VERSION ""

NS_ :

BS_:

BU_: TIMClient3 TIMClient2 TIMClient1 TIMServer
VAL_TABLE_ TIM_AuthErrorCode 39 "LwAPossibleBitMismatch" 38 "AuthenticationAbortedDueToGeneralPeerError" 37 "AuthenticationAbortedByPeerDueToError" 36 "ChallengeDataCorrupt" 35 "InvalidChallengeLength" 34 "FunctionFacilityNotCertified" 33 "RequestNotAllowed" 32 "Reserved_0x20" 31 "AuthenticationTimeout" 30 "CertificateTypeInvalid" 29 "DeviceCertificateRevoked" 28 "ManufacturerSeriesCertificateRevoked" 27 "ManufacturerCertificateRevoked" 26 "LabCertificateRevoked" 25 "RootCertificateRevoked" 24 "CertificateTypeMismatch" 23 "CertificateChainInvalid" 22 "ECU_CCID_Mismatch" 21 "NAME_Mismatch" 20 "ECC_PublicKeyValidationFailed" 19 "UnexpectedRestartAuthenticationBitSet" 18 "AuthenticationStatusInvalid" 17 "AuthenticationTypeNotSupported" 16 "AuthenticationStatusLost" 15 "DeviceCertificateDataCorrupt" 14 "ManufacturerSeriesCertificateDataCorrupt" 13 "ManufacturerCertificateDataCorrupt" 12 "TestLabCertificateDataCorrupt" 11 "RootCertificateDataCorrupt" 10 "InternalError" 9 "ChallengesDontMatch" 8 "DeviceCertificateSignatureInvalid" 7 "ManufacturerSeriesCertificateSignatureInvalid" 6 "ManufacturerCertificateSignatureInvalid" 5 "LabCertificateSignatureInvalid" 4 "RootCertificateSignatureInvalid" 3 "NotAuthenticationServerOrClient" 2 "CertificateFormatNotSupported" 1 "ParticipantBusy" 0 "NoError" ;
VAL_TABLE_ TIM_CertificateType 255 "NotAvailable" 6 "CRLCertificate" 5 "CRLSigningCertificate" 4 "DeviceCertificate" 3 "ManufacturereSeriesCertificate" 2 "ManufacturerCertificate" 1 "TestlabCertificate" 0 "AEFRootCertificate" ;
VAL_TABLE_ NetworkInterconnUnitParametrics 16 "NetworkInterconnectionUnitType" 15 "NumberOfPorts" 14 "UptimeSinceLastPowerOnReset " 13 "AverageNumOfMsgsFilteredPerSec" 12 "AverageNumOfMsgsForwardedPerSec" 11 "AverageNumOfMsgsReceivedPerSec" 10 "NumOfMsgsWithExcessTransitDelayTime " 9 "NumOfMsgsLostDueToBufferOverflow " 8 "AverageTransitDelayTime" 7 "MaxTransitDelayTime" 6 "MaxNumOfMsgsFilteredPerSec" 5 "MaxNumOfMsgsForwardedPerSec" 4 "MaxNumOfMsgsReceivedPerSec" 3 "NumberOfFilterDatabaseEntries" 2 "MaxFilterDatabaseSize" 1 "BufferSize" 0 "RequestAllParameters" ;
VAL_TABLE_ FMI 0 "Above normal (most severe)" 1 "Below normal (most severe)" 2 "Data erratic" 3 "Voltage above normal" 4 "Voltage below normal" 5 "Current below normal" 6 "Current above normal" 7 "Mechanical system not responding" 8 "Abnormal frequency" 9 "Abnormal update rate" 10 "Abnormal rate of change" 11 "Root cause not known" 12 "Bad intelligent device" 13 "Out of calibration" 14 "Special intstructions" 15 "Above normal (least severe)" 16 "Above normal (moderately severe)" 17 "Below normal (least severe)" 18 "Below normal (moderately severe)" 19 "Received network data in error" 31 "Not available" 20 "Data Drifted High" 21 "Data Drifted Low" ;

BO_ 2619670017 TIM21_TIMClient: 16 TIMClient1
 SG_ CurvatureRequest m70 : 32|16@1+ (0.25,-8032) [-8032|8031.75] "1/km" Vector__XXX
 SG_ VehicleSpeedRequest m68 : 32|16@1+ (0.001,-32.128) [-32.127|32.127] "m/s" Vector__XXX
 SG_ HitchPosReq m66 : 32|16@1+ (0.01,0) [0|100] "%" Vector__XXX
 SG_ PTOSpeedRequest m64 : 32|16@1+ (0.125,-4016) [0|0] "1/min" Vector__XXX
 SG_ RequestCounter m0 : 8|4@1+ (1,0) [0|0] "" Vector__XXX
 SG_ AuxValveFlowReq m0 : 32|16@1+ (0.004,-128.512) [0|0] "%" Vector__XXX
 SG_ TIMClientState m249 : 20|4@1+ (1,0) [0|0] "" Vector__XXX
 SG_ ClientHearbeatCounter m249 : 8|8@1+ (1,0) [0|0] "" Vector__XXX
 SG_ TIMFunctionId_4 m245 : 64|8@1+ (1,0) [0|0] "" Vector__XXX
 SG_ TIMFunctionId_3 m245 : 48|8@1+ (1,0) [0|0] "" Vector__XXX
 SG_ TIMFunctionId_2 m245 : 32|8@1+ (1,0) [0|0] "" Vector__XXX
 SG_ TIMFunctionId_1 m245 : 16|8@1+ (1,0) [0|0] "" Vector__XXX
 SG_ NumOfTIMFunctions m245 : 8|8@1+ (1,0) [1|250] "" Vector__XXX
 SG_ RequestType_4 m245 : 77|3@1+ (1,0) [0|0] "" Vector__XXX
 SG_ RequestType_3 m245 : 61|3@1+ (1,0) [0|0] "" Vector__XXX
 SG_ RequestType_2 m245 : 45|3@1+ (1,0) [0|0] "" Vector__XXX
 SG_ RequestType_1 m245 : 29|3@1+ (1,0) [0|0] "" Vector__XXX
 SG_ MinimumTIMVersionNr m246 : 24|8@1+ (1,0) [0|0] "" Vector__XXX
 SG_ ImplementedTIMVersionNr m246 : 16|8@1+ (1,0) [0|0] "" Vector__XXX
 SG_ TIMMessageType m0 : 12|4@1+ (1,0) [0|0] "" Vector__XXX
 SG_ GroupFunctionValue M : 0|8@1+ (1,0) [0|0] "" Vector__XXX

BO_ 2619670018 TIM21_TIMClient2: 16 TIMClient2
 SG_ CurvatureRequest m70 : 32|16@1+ (0.25,-8032) [-8032|8031.75] "1/km" Vector__XXX
 SG_ VehicleSpeedRequest m68 : 32|16@1+ (0.001,-32.128) [-32.127|32.127] "m/s" Vector__XXX
 SG_ HitchPosReq m66 : 32|16@1+ (0.01,0) [0|100] "%" Vector__XXX
 SG_ PTOSpeedRequest m64 : 32|16@1+ (0.125,-4016) [0|0] "1/min" Vector__XXX
 SG_ RequestCounter m0 : 8|4@1+ (1,0) [0|0] "" Vector__XXX
 SG_ AuxValveFlowReq m0 : 32|16@1+ (0.004,-128.512) [0|0] "%" Vector__XXX
 SG_ TIMClientState m249 : 20|4@1+ (1,0) [0|0] "" Vector__XXX
 SG_ ClientHearbeatCounter m249 : 8|8@1+ (1,0) [0|0] "" Vector__XXX
 SG_ TIMFunctionId_4 m245 : 64|8@1+ (1,0) [0|0] "" Vector__XXX
 SG_ TIMFunctionId_3 m245 : 48|8@1+ (1,0) [0|0] "" Vector__XXX
 SG_ TIMFunctionId_2 m245 : 32|8@1+ (1,0) [0|0] "" Vector__XXX
 SG_ TIMFunctionId_1 m245 : 16|8@1+ (1,0) [0|0] "" Vector__XXX
 SG_ NumOfTIMFunctions m245 : 8|8@1+ (1,0) [1|250] "" Vector__XXX
 SG_ RequestType_4 m245 : 77|3@1+ (1,0) [0|0] "" Vector__XXX
 SG_ RequestType_3 m245 : 61|3@1+ (1,0) [0|0] "" Vector__XXX
 SG_ RequestType_2 m245 : 45|3@1+ (1,0) [0|0] "" Vector__XXX
 SG_ RequestType_1 m245 : 29|3@1+ (1,0) [0|0] "" Vector__XXX
 SG_ MinimumTIMVersionNr m246 : 24|8@1+ (1,0) [0|0] "" Vector__XXX
 SG_ ImplementedTIMVersionNr m246 : 16|8@1+ (1,0) [0|0] "" Vector__XXX
 SG_ TIMMessageType m0 : 12|4@1+ (1,0) [0|0] "" Vector__XXX
 SG_ GroupFunctionValue M : 0|8@1+ (1,0) [0|0] "" Vector__XXX

BO_ 2619670019 TIM21_TIMClient3: 16 TIMClient3
 SG_ CurvatureRequest m70 : 32|16@1+ (0.25,-8032) [-8032|8031.75] "1/km" Vector__XXX
 SG_ VehicleSpeedRequest m68 : 32|16@1+ (0.001,-32.128) [-32.127|32.127] "m/s" Vector__XXX
 SG_ HitchPosReq m66 : 32|16@1+ (0.01,0) [0|100] "%" Vector__XXX
 SG_ PTOSpeedRequest m64 : 32|16@1+ (0.125,-4016) [0|0] "1/min" Vector__XXX
 SG_ RequestCounter m0 : 8|4@1+ (1,0) [0|0] "" Vector__XXX
 SG_ AuxValveFlowReq m0 : 32|16@1+ (0.004,-128.512) [0|0] "%" Vector__XXX
 SG_ TIMClientState m249 : 20|4@1+ (1,0) [0|0] "" Vector__XXX
 SG_ ClientHearbeatCounter m249 : 8|8@1+ (1,0) [0|0] "" Vector__XXX
 SG_ TIMFunctionId_4 m245 : 64|8@1+ (1,0) [0|0] "" Vector__XXX
 SG_ TIMFunctionId_3 m245 : 48|8@1+ (1,0) [0|0] "" Vector__XXX
 SG_ TIMFunctionId_2 m245 : 32|8@1+ (1,0) [0|0] "" Vector__XXX
 SG_ TIMFunctionId_1 m245 : 16|8@1+ (1,0) [0|0] "" Vector__XXX
 SG_ NumOfTIMFunctions m245 : 8|8@1+ (1,0) [1|250] "" Vector__XXX
 SG_ RequestType_4 m245 : 77|3@1+ (1,0) [0|0] "" Vector__XXX
 SG_ RequestType_3 m245 : 61|3@1+ (1,0) [0|0] "" Vector__XXX
 SG_ RequestType_2 m245 : 45|3@1+ (1,0) [0|0] "" Vector__XXX
 SG_ RequestType_1 m245 : 29|3@1+ (1,0) [0|0] "" Vector__XXX
 SG_ MinimumTIMVersionNr m246 : 24|8@1+ (1,0) [0|0] "" Vector__XXX
 SG_ ImplementedTIMVersionNr m246 : 16|8@1+ (1,0) [0|0] "" Vector__XXX
 SG_ TIMMessageType m0 : 12|4@1+ (1,0) [0|0] "" Vector__XXX
 SG_ GroupFunctionValue M : 0|8@1+ (1,0) [0|0] "" Vector__XXX

BO_ 2619604717 TIM12_TIMServer: 16 TIMServer
 SG_ Curvature m70 : 32|16@1+ (0.25,-8032) [-8032|8031.75] "1/km" Vector__XXX
 SG_ GuidanceExitReasonCode m70 : 27|5@1+ (1,0) [0|0] "" Vector__XXX
 SG_ VehicleSpeed m68 : 32|16@1+ (0.001,-32.128) [-32.127|32.127] "m/s" Vector__XXX
 SG_ SpeedExitReasonCode m68 : 27|5@1+ (1,0) [0|0] "" Vector__XXX
 SG_ HitchPosition m66 : 32|16@1+ (0.01,0) [0|100] "%" Vector__XXX
 SG_ HitchExitReasonCode m66 : 27|5@1+ (1,0) [0|0] "" Vector__XXX
 SG_ PTOSpeed m64 : 32|16@1+ (0.125,-4016) [0|0] "1/min" Vector__XXX
 SG_ PTOExitReasonCode m64 : 27|5@1+ (1,0) [0|0] "" Vector__XXX
 SG_ TIMAuxValveFlow m0 : 32|16@1+ (0.004,-128.512) [0|0] "%" Vector__XXX
 SG_ FlowType m0 : 24|2@1+ (1,0) [0|0] "" Vector__XXX
 SG_ ReflectedRequestCounter m0 : 8|4@1+ (1,0) [0|0] "" Vector__XXX
 SG_ AuxValveExitReasonCode m0 : 27|5@1+ (1,0) [0|0] "" Vector__XXX
 SG_ AutomationStatus m0 : 16|4@1+ (1,0) [0|0] "" Vector__XXX
 SG_ TIMSystemOperationState m250 : 24|4@1+ (1,0) [0|15] "" Vector__XXX
 SG_ TIMServerState m250 : 28|4@1+ (1,0) [0|0] "" Vector__XXX
 SG_ TIMSystemState m250 : 16|4@1+ (1,0) [0|0] "" Vector__XXX
 SG_ TIMServerMasterIndication m250 : 20|4@1+ (1,0) [0|0] "" Vector__XXX
 SG_ ServerHeartbeatCounter m250 : 8|8@1+ (1,0) [0|0] "" Vector__XXX
 SG_ AssignmentResult_4 m245 : 77|3@1+ (1,0) [0|0] "" Vector__XXX
 SG_ AssignmentResult_3 m245 : 61|3@1+ (1,0) [0|0] "" Vector__XXX
 SG_ AssignmentResult_2 m245 : 45|3@1+ (1,0) [0|0] "" Vector__XXX
 SG_ AssignmentErrorReason_4 m245 : 72|5@1+ (1,0) [0|0] "" Vector__XXX
 SG_ AssignmentErrorReason_3 m245 : 56|5@1+ (1,0) [0|0] "" Vector__XXX
 SG_ AssignmentErrorReason_2 m245 : 40|5@1+ (1,0) [0|0] "" Vector__XXX
 SG_ AssignmentErrorReason_1 m245 : 24|5@1+ (1,0) [0|0] "" Vector__XXX
 SG_ AssignmentResult_1 m245 : 29|3@1+ (1,0) [0|0] "" Vector__XXX
 SG_ TIMFunctionId_4 m245 : 64|8@1+ (1,0) [0|0] "" Vector__XXX
 SG_ TIMFunctionId_3 m245 : 48|8@1+ (1,0) [0|0] "" Vector__XXX
 SG_ TIMFunctionId_2 m245 : 32|8@1+ (1,0) [0|0] "" Vector__XXX
 SG_ TIMFunctionId_1 m245 : 16|8@1+ (1,0) [0|0] "" Vector__XXX
 SG_ NumOfTIMFunctions m245 : 8|8@1+ (1,0) [1|250] "" Vector__XXX
 SG_ NumOfSuportedTIMFunctions m244 : 8|8@1+ (1,0) [1|250] "" Vector__XXX
 SG_ TIMConnectionVersion m246 : 16|8@1+ (1,0) [0|0] "" Vector__XXX
 SG_ ErrorCode m246 : 8|8@1+ (1,0) [0|0] "" Vector__XXX
 SG_ MinimumTIMVersionNr m248 : 24|8@1+ (1,0) [0|0] "" Vector__XXX
 SG_ ImplementedTIMVersionNr m248 : 16|8@1+ (1,0) [0|0] "" Vector__XXX
 SG_ BootTime m248 : 8|8@1+ (1,0) [0|0] "" Vector__XXX
 SG_ TIMMessageType m0 : 12|4@1+ (1,0) [0|0] "" Vector__XXX
 SG_ GroupFunctionValue M : 0|8@1+ (1,0) [0|0] "" Vector__XXX

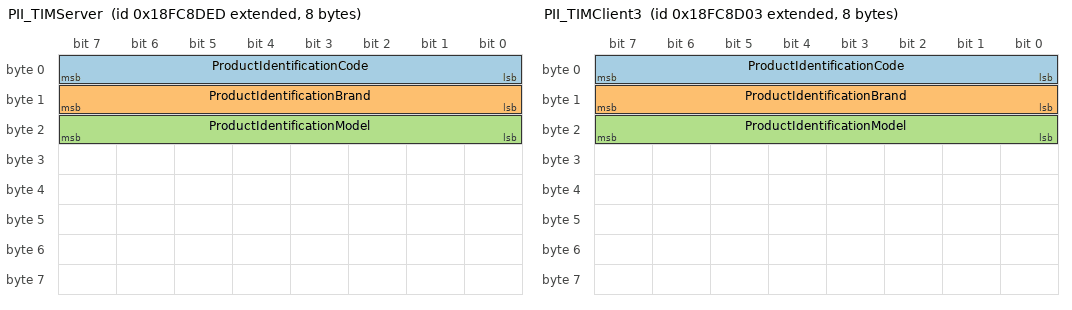
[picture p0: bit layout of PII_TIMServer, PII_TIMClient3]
BO_ 2566688237 PII_TIMServer: 8 TIMServer
 SG_ ProductIdentificationCode : 0|8@1- (1,0) [0|0] "" Vector__XXX
 SG_ ProductIdentificationBrand : 8|8@1- (1,0) [0|0] "" Vector__XXX
 SG_ ProductIdentificationModel : 16|8@1- (1,0) [0|0] "" Vector__XXX

BO_ 2566688003 PII_TIMClient3: 8 TIMClient3
 SG_ ProductIdentificationCode : 0|8@1- (1,0) [0|0] "" Vector__XXX
 SG_ ProductIdentificationBrand : 8|8@1- (1,0) [0|0] "" Vector__XXX
 SG_ ProductIdentificationModel : 16|8@1- (1,0) [0|0] "" Vector__XXX

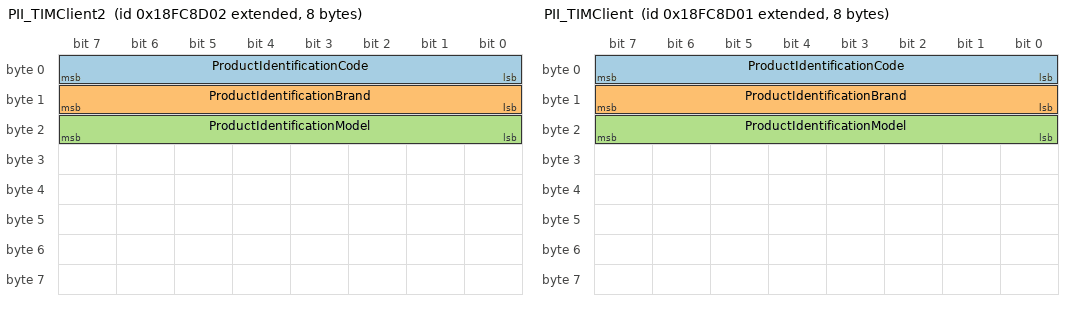
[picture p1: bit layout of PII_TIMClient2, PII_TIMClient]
BO_ 2566688002 PII_TIMClient2: 8 TIMClient2
 SG_ ProductIdentificationCode : 0|8@1- (1,0) [0|0] "" Vector__XXX
 SG_ ProductIdentificationBrand : 8|8@1- (1,0) [0|0] "" Vector__XXX
 SG_ ProductIdentificationModel : 16|8@1- (1,0) [0|0] "" Vector__XXX

BO_ 2566688001 PII_TIMClient: 8 TIMClient1
 SG_ ProductIdentificationCode : 0|8@1- (1,0) [0|0] "" Vector__XXX
 SG_ ProductIdentificationBrand : 8|8@1- (1,0) [0|0] "" Vector__XXX
 SG_ ProductIdentificationModel : 16|8@1- (1,0) [0|0] "" Vector__XXX

BO_ 2566734573 ICC_TIMServer: 8 TIMServer
 SG_ CertLaboratoryType_FirstDef m0 : 9|3@1+ (1,0) [0|7] "" Vector__XXX
 SG_ TestProtocolRevision_MSBits m1 : 11|2@1+ (1,0) [0|0] "" Vector__XXX
 SG_ MessageRevision M : 47|1@1+ (1,0) [0|0] "" Vector__XXX
 SG_ CertificationReferenceNumber : 48|16@1+ (1,0) [0|65535] "" Vector__XXX
 SG_ CertTypeTaskController m0 : 39|1@1+ (1,0) [0|1] "" Vector__XXX
 SG_ CertTypeTCWorkingSetMaster m0 : 38|1@1+ (1,0) [0|1] "" Vector__XXX
 SG_ CertTypeTCWorkingSetMember m0 : 37|1@1+ (1,0) [0|1] "" Vector__XXX
 SG_ CertTypeFileServer m0 : 36|1@1+ (1,0) [0|1] "" Vector__XXX
 SG_ CertTypeGPSReceiver m0 : 35|1@1+ (1,0) [0|1] "" Vector__XXX
 SG_ CertTypeMinimumECU m0 : 31|1@1+ (1,0) [0|1] "" Vector__XXX
 SG_ CertTypeTECUClass1 m0 : 30|1@1+ (1,0) [0|1] "" Vector__XXX
 SG_ CertTypeTECUClass2 m0 : 29|1@1+ (1,0) [0|1] "" Vector__XXX
 SG_ CertTypeTECUClass3 m0 : 28|1@1+ (1,0) [0|1] "" Vector__XXX
 SG_ CertTypeClass3ECU m0 : 27|1@1+ (1,0) [0|1] "" Vector__XXX
 SG_ CertTypeVirtualTerminal m0 : 26|1@1+ (1,0) [0|1] "" Vector__XXX
 SG_ CertTypeVTWorkingSetMaster m0 : 25|1@1+ (1,0) [0|1] "" Vector__XXX
 SG_ CertTypeVTWorkingSetMember m0 : 24|1@1+ (1,0) [0|1] "" Vector__XXX
 SG_ CertificationLaboratoryID : 13|11@1+ (1,0) [0|2047] "" Vector__XXX
 SG_ CertLaboratoryType_SecondDef m1 : 9|2@1+ (1,0) [0|3] "" Vector__XXX
 SG_ TestProtocolRevision : 6|3@1+ (1,0) [0|7] "" Vector__XXX
 SG_ TestProtocolPublicationYear : 0|6@1+ (1,2000) [2000|2061] "year" Vector__XXX

BO_ 2566734339 ICC_TIMClient3: 8 TIMClient3
 SG_ CertLaboratoryType_FirstDef m0 : 9|3@1+ (1,0) [0|7] "" Vector__XXX
 SG_ TestProtocolRevision_MSBits m1 : 11|2@1+ (1,0) [0|0] "" Vector__XXX
 SG_ MessageRevision M : 47|1@1+ (1,0) [0|0] "" Vector__XXX
 SG_ CertificationReferenceNumber : 48|16@1+ (1,0) [0|65535] "" Vector__XXX
 SG_ CertTypeTaskController m0 : 39|1@1+ (1,0) [0|1] "" Vector__XXX
 SG_ CertTypeTCWorkingSetMaster m0 : 38|1@1+ (1,0) [0|1] "" Vector__XXX
 SG_ CertTypeTCWorkingSetMember m0 : 37|1@1+ (1,0) [0|1] "" Vector__XXX
 SG_ CertTypeFileServer m0 : 36|1@1+ (1,0) [0|1] "" Vector__XXX
 SG_ CertTypeGPSReceiver m0 : 35|1@1+ (1,0) [0|1] "" Vector__XXX
 SG_ CertTypeMinimumECU m0 : 31|1@1+ (1,0) [0|1] "" Vector__XXX
 SG_ CertTypeTECUClass1 m0 : 30|1@1+ (1,0) [0|1] "" Vector__XXX
 SG_ CertTypeTECUClass2 m0 : 29|1@1+ (1,0) [0|1] "" Vector__XXX
 SG_ CertTypeTECUClass3 m0 : 28|1@1+ (1,0) [0|1] "" Vector__XXX
 SG_ CertTypeClass3ECU m0 : 27|1@1+ (1,0) [0|1] "" Vector__XXX
 SG_ CertTypeVirtualTerminal m0 : 26|1@1+ (1,0) [0|1] "" Vector__XXX
 SG_ CertTypeVTWorkingSetMaster m0 : 25|1@1+ (1,0) [0|1] "" Vector__XXX
 SG_ CertTypeVTWorkingSetMember m0 : 24|1@1+ (1,0) [0|1] "" Vector__XXX
 SG_ CertificationLaboratoryID : 13|11@1+ (1,0) [0|2047] "" Vector__XXX
 SG_ CertLaboratoryType_SecondDef m1 : 9|2@1+ (1,0) [0|3] "" Vector__XXX
 SG_ TestProtocolRevision : 6|3@1+ (1,0) [0|7] "" Vector__XXX
 SG_ TestProtocolPublicationYear : 0|6@1+ (1,2000) [2000|2061] "year" Vector__XXX

BO_ 2566734338 ICC_TIMClient2: 8 TIMClient2
 SG_ CertLaboratoryType_FirstDef m0 : 9|3@1+ (1,0) [0|7] "" Vector__XXX
 SG_ TestProtocolRevision_MSBits m1 : 11|2@1+ (1,0) [0|0] "" Vector__XXX
 SG_ MessageRevision M : 47|1@1+ (1,0) [0|0] "" Vector__XXX
 SG_ CertificationReferenceNumber : 48|16@1+ (1,0) [0|65535] "" Vector__XXX
 SG_ CertTypeTaskController m0 : 39|1@1+ (1,0) [0|1] "" Vector__XXX
 SG_ CertTypeTCWorkingSetMaster m0 : 38|1@1+ (1,0) [0|1] "" Vector__XXX
 SG_ CertTypeTCWorkingSetMember m0 : 37|1@1+ (1,0) [0|1] "" Vector__XXX
 SG_ CertTypeFileServer m0 : 36|1@1+ (1,0) [0|1] "" Vector__XXX
 SG_ CertTypeGPSReceiver m0 : 35|1@1+ (1,0) [0|1] "" Vector__XXX
 SG_ CertTypeMinimumECU m0 : 31|1@1+ (1,0) [0|1] "" Vector__XXX
 SG_ CertTypeTECUClass1 m0 : 30|1@1+ (1,0) [0|1] "" Vector__XXX
 SG_ CertTypeTECUClass2 m0 : 29|1@1+ (1,0) [0|1] "" Vector__XXX
 SG_ CertTypeTECUClass3 m0 : 28|1@1+ (1,0) [0|1] "" Vector__XXX
 SG_ CertTypeClass3ECU m0 : 27|1@1+ (1,0) [0|1] "" Vector__XXX
 SG_ CertTypeVirtualTerminal m0 : 26|1@1+ (1,0) [0|1] "" Vector__XXX
 SG_ CertTypeVTWorkingSetMaster m0 : 25|1@1+ (1,0) [0|1] "" Vector__XXX
 SG_ CertTypeVTWorkingSetMember m0 : 24|1@1+ (1,0) [0|1] "" Vector__XXX
 SG_ CertificationLaboratoryID : 13|11@1+ (1,0) [0|2047] "" Vector__XXX
 SG_ CertLaboratoryType_SecondDef m1 : 9|2@1+ (1,0) [0|3] "" Vector__XXX
 SG_ TestProtocolRevision : 6|3@1+ (1,0) [0|7] "" Vector__XXX
 SG_ TestProtocolPublicationYear : 0|6@1+ (1,2000) [2000|2061] "year" Vector__XXX

BO_ 2566734337 ICC_TIMClient: 8 TIMClient1
 SG_ CertLaboratoryType_FirstDef m0 : 9|3@1+ (1,0) [0|7] "" Vector__XXX
 SG_ TestProtocolRevision_MSBits m1 : 11|2@1+ (1,0) [0|0] "" Vector__XXX
 SG_ MessageRevision M : 47|1@1+ (1,0) [0|0] "" Vector__XXX
 SG_ CertificationReferenceNumber : 48|16@1+ (1,0) [0|65535] "" Vector__XXX
 SG_ CertTypeTaskController m0 : 39|1@1+ (1,0) [0|1] "" Vector__XXX
 SG_ CertTypeTCWorkingSetMaster m0 : 38|1@1+ (1,0) [0|1] "" Vector__XXX
 SG_ CertTypeTCWorkingSetMember m0 : 37|1@1+ (1,0) [0|1] "" Vector__XXX
 SG_ CertTypeFileServer m0 : 36|1@1+ (1,0) [0|1] "" Vector__XXX
 SG_ CertTypeGPSReceiver m0 : 35|1@1+ (1,0) [0|1] "" Vector__XXX
 SG_ CertTypeMinimumECU m0 : 31|1@1+ (1,0) [0|1] "" Vector__XXX
 SG_ CertTypeTECUClass1 m0 : 30|1@1+ (1,0) [0|1] "" Vector__XXX
 SG_ CertTypeTECUClass2 m0 : 29|1@1+ (1,0) [0|1] "" Vector__XXX
 SG_ CertTypeTECUClass3 m0 : 28|1@1+ (1,0) [0|1] "" Vector__XXX
 SG_ CertTypeClass3ECU m0 : 27|1@1+ (1,0) [0|1] "" Vector__XXX
 SG_ CertTypeVirtualTerminal m0 : 26|1@1+ (1,0) [0|1] "" Vector__XXX
 SG_ CertTypeVTWorkingSetMaster m0 : 25|1@1+ (1,0) [0|1] "" Vector__XXX
 SG_ CertTypeVTWorkingSetMember m0 : 24|1@1+ (1,0) [0|1] "" Vector__XXX
 SG_ CertificationLaboratoryID : 13|11@1+ (1,0) [0|2047] "" Vector__XXX
 SG_ CertLaboratoryType_SecondDef m1 : 9|2@1+ (1,0) [0|3] "" Vector__XXX
 SG_ TestProtocolRevision : 6|3@1+ (1,0) [0|7] "" Vector__XXX
 SG_ TestProtocolPublicationYear : 0|6@1+ (1,2000) [2000|2061] "year" Vector__XXX

BO_ 2624650989 AUTH12_TIMServer: 16 TIMServer
 SG_ NumberOfAuthenticatedClients m8 : 8|8@1+ (1,0) [0|255] "" Vector__XXX
 SG_ AuthenticationStatus m249 : 16|4@1+ (1,0) [0|0] "" Vector__XXX
 SG_ ChallengeSigned m249 : 25|1@1+ (1,0) [0|0] "" Vector__XXX
 SG_ DeviceCertIsValid m249 : 26|1@1+ (1,0) [0|0] "" Vector__XXX
 SG_ ManufactSeriesCertIsValid m249 : 27|1@1+ (1,0) [0|0] "" Vector__XXX
 SG_ ManufactCertIsValid m249 : 28|1@1+ (1,0) [0|0] "" Vector__XXX
 SG_ TestlabCertIsValid m249 : 29|1@1+ (1,0) [0|0] "" Vector__XXX
 SG_ LwAPossible m249 : 30|1@1+ (1,0) [0|0] "" Vector__XXX
 SG_ ReStartAuth m249 : 31|1@1+ (1,0) [0|0] "" Vector__XXX
 SG_ ChallengeData m4 : 40|16@1+ (1,0) [0|0] "" Vector__XXX
 SG_ CertificateData m2 : 40|16@1+ (1,0) [0|0] "" Vector__XXX
 SG_ CertType m2 : 32|8@1+ (1,0) [0|0] "" Vector__XXX
 SG_ CertificateFormat m2 : 24|8@1+ (1,0) [0|0] "" Vector__XXX
 SG_ AuthenticationType m2 : 20|4@1+ (1,0) [0|0] "" Vector__XXX
 SG_ MessageCode M : 0|8@1+ (1,0) [0|0] "" Vector__XXX
 SG_ ErrorCode m2 : 8|8@1+ (1,0) [0|0] "" Vector__XXX

BO_ 2624585219 AUTH21_TIMClient3: 16 TIMClient3
 SG_ NumberOfAuthenticatedServers m9 : 8|8@1+ (1,0) [0|255] "" Vector__XXX
 SG_ LwAPossible m250 : 30|1@1+ (1,0) [0|0] "" Vector__XXX
 SG_ TestlabCertIsValid m250 : 29|1@1+ (1,0) [0|0] "" Vector__XXX
 SG_ ReStartAuth m250 : 31|1@1+ (1,0) [0|0] "" Vector__XXX
 SG_ ManufactSeriesCertIsValid m250 : 27|1@1+ (1,0) [0|0] "" Vector__XXX
 SG_ ManufactCertIsValid m250 : 28|1@1+ (1,0) [0|0] "" Vector__XXX
 SG_ DeviceCertIsValid m250 : 26|1@1+ (1,0) [0|0] "" Vector__XXX
 SG_ ChallengeSigned m250 : 25|1@1+ (1,0) [0|0] "" Vector__XXX
 SG_ AuthenticationStatus m250 : 16|4@1+ (1,0) [0|0] "" Vector__XXX
 SG_ ChallengeData m5 : 40|16@1+ (1,0) [0|0] "" Vector__XXX
 SG_ CertificateData m3 : 40|16@1+ (1,0) [0|0] "" Vector__XXX
 SG_ ErrorCode m3 : 8|8@1+ (1,0) [0|0] "" Vector__XXX
 SG_ CertType m2 : 32|8@1+ (1,0) [0|0] "" Vector__XXX
 SG_ CertificateFormat m2 : 24|8@1+ (1,0) [0|0] "" Vector__XXX
 SG_ AuthenticationType m2 : 20|4@1+ (1,0) [0|0] "" Vector__XXX
 SG_ MessageCode M : 0|8@1+ (1,0) [0|0] "" Vector__XXX

BO_ 2624585218 AUTH21_TIMClient2: 16 TIMClient2
 SG_ NumberOfAuthenticatedServers m9 : 8|8@1+ (1,0) [0|255] "" Vector__XXX
 SG_ LwAPossible m250 : 30|1@1+ (1,0) [0|0] "" Vector__XXX
 SG_ TestlabCertIsValid m250 : 29|1@1+ (1,0) [0|0] "" Vector__XXX
 SG_ ReStartAuth m250 : 31|1@1+ (1,0) [0|0] "" Vector__XXX
 SG_ ManufactSeriesCertIsValid m250 : 27|1@1+ (1,0) [0|0] "" Vector__XXX
 SG_ ManufactCertIsValid m250 : 28|1@1+ (1,0) [0|0] "" Vector__XXX
 SG_ DeviceCertIsValid m250 : 26|1@1+ (1,0) [0|0] "" Vector__XXX
 SG_ ChallengeSigned m250 : 25|1@1+ (1,0) [0|0] "" Vector__XXX
 SG_ AuthenticationStatus m250 : 16|4@1+ (1,0) [0|0] "" Vector__XXX
 SG_ ChallengeData m5 : 40|16@1+ (1,0) [0|0] "" Vector__XXX
 SG_ CertificateData m3 : 40|16@1+ (1,0) [0|0] "" Vector__XXX
 SG_ ErrorCode m3 : 8|8@1+ (1,0) [0|0] "" Vector__XXX
 SG_ CertType m2 : 32|8@1+ (1,0) [0|0] "" Vector__XXX
 SG_ CertificateFormat m2 : 24|8@1+ (1,0) [0|0] "" Vector__XXX
 SG_ AuthenticationType m2 : 20|4@1+ (1,0) [0|0] "" Vector__XXX
 SG_ MessageCode M : 0|8@1+ (1,0) [0|0] "" Vector__XXX

BO_ 2624585217 AUTH21_TIMClient: 16 TIMClient1
 SG_ NumberOfAuthenticatedServers m9 : 8|8@1+ (1,0) [0|255] "" Vector__XXX
 SG_ LwAPossible m250 : 30|1@1+ (1,0) [0|0] "" Vector__XXX
 SG_ TestlabCertIsValid m250 : 29|1@1+ (1,0) [0|0] "" Vector__XXX
 SG_ ReStartAuth m250 : 31|1@1+ (1,0) [0|0] "" Vector__XXX
 SG_ ManufactSeriesCertIsValid m250 : 27|1@1+ (1,0) [0|0] "" Vector__XXX
 SG_ ManufactCertIsValid m250 : 28|1@1+ (1,0) [0|0] "" Vector__XXX
 SG_ DeviceCertIsValid m250 : 26|1@1+ (1,0) [0|0] "" Vector__XXX
 SG_ ChallengeSigned m250 : 25|1@1+ (1,0) [0|0] "" Vector__XXX
 SG_ AuthenticationStatus m250 : 16|4@1+ (1,0) [0|0] "" Vector__XXX
 SG_ ChallengeData m5 : 40|16@1+ (1,0) [0|0] "" Vector__XXX
 SG_ CertificateData m3 : 40|16@1+ (1,0) [0|0] "" Vector__XXX
 SG_ ErrorCode m3 : 8|8@1+ (1,0) [0|0] "" Vector__XXX
 SG_ CertType m2 : 32|8@1+ (1,0) [0|0] "" Vector__XXX
 SG_ CertificateFormat m2 : 24|8@1+ (1,0) [0|0] "" Vector__XXX
 SG_ AuthenticationType m2 : 20|4@1+ (1,0) [0|0] "" Vector__XXX
 SG_ MessageCode M : 0|8@1+ (1,0) [0|0] "" Vector__XXX

BO_ 2565799661 ACL_TIMServer: 8 TIMServer
 SG_ ReservedBit : 48|1@1+ (1,0) [0|0] "" Vector__XXX
 SG_ ArbitraryAddressCapable : 63|1@1+ (1,0) [0|1] "" Vector__XXX
 SG_ IndustryGroup M : 60|3@1+ (1,0) [0|7] "" Vector__XXX
 SG_ VehicleSystemInstance : 56|4@1+ (1,0) [0|15] "" Vector__XXX
 SG_ VehicleSystem m0 : 49|7@1+ (1,0) [0|127] "" Vector__XXX
 SG_ VehicleSystem5 m5 : 49|7@1+ (1,0) [0|127] "" Vector__XXX
 SG_ VehicleSystem4 m4 : 49|7@1+ (1,0) [0|127] "" Vector__XXX
 SG_ VehicleSystem3 m3 : 49|7@1+ (1,0) [0|127] "" Vector__XXX
 SG_ VehicleSystem2 m2 : 49|7@1+ (1,0) [0|127] "" Vector__XXX
 SG_ VehicleSystem1 m1 : 49|7@1+ (1,0) [0|127] "" Vector__XXX
 SG_ Function : 40|8@1+ (1,0) [0|255] "" Vector__XXX
 SG_ FunctionInstance : 35|5@1+ (1,0) [0|31] "" Vector__XXX
 SG_ ECUInstance : 32|3@1+ (1,0) [0|7] "" Vector__XXX
 SG_ ManufacturerCode : 21|11@1+ (1,0) [0|2047] "" Vector__XXX
 SG_ IdentityNumber : 0|21@1+ (1,0) [0|2097152] "" Vector__XXX

BO_ 2565799427 ACL_TIMClient3: 8 TIMClient3
 SG_ ReservedBit : 48|1@1+ (1,0) [0|0] "" Vector__XXX
 SG_ ArbitraryAddressCapable : 63|1@1+ (1,0) [0|1] "" Vector__XXX
 SG_ IndustryGroup M : 60|3@1+ (1,0) [0|7] "" Vector__XXX
 SG_ VehicleSystemInstance : 56|4@1+ (1,0) [0|15] "" Vector__XXX
 SG_ VehicleSystem m0 : 49|7@1+ (1,0) [0|127] "" Vector__XXX
 SG_ VehicleSystem5 m5 : 49|7@1+ (1,0) [0|127] "" Vector__XXX
 SG_ VehicleSystem4 m4 : 49|7@1+ (1,0) [0|127] "" Vector__XXX
 SG_ VehicleSystem3 m3 : 49|7@1+ (1,0) [0|127] "" Vector__XXX
 SG_ VehicleSystem2 m2 : 49|7@1+ (1,0) [0|127] "" Vector__XXX
 SG_ VehicleSystem1 m1 : 49|7@1+ (1,0) [0|127] "" Vector__XXX
 SG_ Function : 40|8@1+ (1,0) [0|255] "" Vector__XXX
 SG_ FunctionInstance : 35|5@1+ (1,0) [0|31] "" Vector__XXX
 SG_ ECUInstance : 32|3@1+ (1,0) [0|7] "" Vector__XXX
 SG_ ManufacturerCode : 21|11@1+ (1,0) [0|2047] "" Vector__XXX
 SG_ IdentityNumber : 0|21@1+ (1,0) [0|2097152] "" Vector__XXX

CM_ BO_ 2619670017 "TIM message: TIM client to TIM server";
CM_ BO_ 2619670018 "TIM message: TIM client to TIM server";
CM_ BO_ 2619670019 "TIM message: TIM client to TIM server";
CM_ BO_ 2619604717 "TIM message: TIM server to TIM client";
CM_ BO_ 2566688237 "Product Identification Information: Each control function of a product shall respond with the same product identification information when it 
receives the Request PGN message for this PGN.";
CM_ SG_ 2566688237 ProductIdentificationCode "The Product Identification Code as assigned by the manufacturer correspondents with the number on the type 
plate of a product.";
CM_ SG_ 2566688237 ProductIdentificationBrand "Specifies  the  brand  of  a  product.  
The  combination  of  the  Product Identification Code and the Product Identification Brand shall make the product unique in the world.";
CM_ SG_ 2566688237 ProductIdentificationModel "The Product Identification Model specifies a unique product within a Brand. ";
CM_ BO_ 2566688003 "Product Identification Information: Each control function of a product shall respond with the same product identification information when it 
receives the Request PGN message for this PGN.";
CM_ SG_ 2566688003 ProductIdentificationCode "The Product Identification Code as assigned by the manufacturer correspondents with the number on the type 
plate of a product.";
CM_ SG_ 2566688003 ProductIdentificationBrand "Specifies  the  brand  of  a  product.  
The  combination  of  the  Product Identification Code and the Product Identification Brand shall make the product unique in the world.";
CM_ SG_ 2566688003 ProductIdentificationModel "The Product Identification Model specifies a unique product within a Brand. ";
CM_ BO_ 2566688002 "Product Identification Information: Each control function of a product shall respond with the same product identification information when it 
receives the Request PGN message for this PGN.";
CM_ SG_ 2566688002 ProductIdentificationCode "The Product Identification Code as assigned by the manufacturer correspondents with the number on the type 
plate of a product.";
CM_ SG_ 2566688002 ProductIdentificationBrand "Specifies  the  brand  of  a  product.  
The  combination  of  the  Product Identification Code and the Product Identification Brand shall make the product unique in the world.";
CM_ SG_ 2566688002 ProductIdentificationModel "The Product Identification Model specifies a unique product within a Brand. ";
CM_ BO_ 2566688001 "Product Identification Information: Each control function of a product shall respond with the same product identification information when it 
receives the Request PGN message for this PGN.";
CM_ SG_ 2566688001 ProductIdentificationCode "The Product Identification Code as assigned by the manufacturer correspondents with the number on the type 
plate of a product.";
CM_ SG_ 2566688001 ProductIdentificationBrand "Specifies  the  brand  of  a  product.  
The  combination  of  the  Product Identification Code and the Product Identification Brand shall make the product unique in the world.";
CM_ SG_ 2566688001 ProductIdentificationModel "The Product Identification Model specifies a unique product within a Brand. ";
CM_ BO_ 2566734573 "ISOBUS compliance certification";
CM_ SG_ 2566734573 CertLaboratoryType_FirstDef "Approving body for the certification laboratory.";
CM_ SG_ 2566734573 MessageRevision "This parameter distinguishes the format of the ISOBUS Compliance Certification message in the second 
edition from the format in the third and later editions.";
CM_ SG_ 2566734573 CertificationReferenceNumber "ISOBUS Compliance certification reference number";
CM_ SG_ 2566734573 CertTypeTaskController "ISOBUS Compliance certification type - Task Controller";
CM_ SG_ 2566734573 CertTypeTCWorkingSetMaster "ISOBUS Compliance certification type - TC working set master";
CM_ SG_ 2566734573 CertTypeTCWorkingSetMember "ISOBUS Compliance certification type - TC working set member";
CM_ SG_ 2566734573 CertTypeFileServer "ISOBUS Compliance certification type - File server";
CM_ SG_ 2566734573 CertTypeGPSReceiver "ISOBUS Compliance certification type - GPS receiver";
CM_ SG_ 2566734573 CertTypeMinimumECU "ISOBUS Compliance certification type - Minimum ECU";
CM_ SG_ 2566734573 CertTypeTECUClass1 "ISOBUS Compliance certification type - TECU Class 1";
CM_ SG_ 2566734573 CertTypeTECUClass2 "ISOBUS Compliance certification type - TECU Class 2";
CM_ SG_ 2566734573 CertTypeTECUClass3 "ISOBUS Compliance certification type - TECU Class 3";
CM_ SG_ 2566734573 CertTypeClass3ECU "ISOBUS Compliance certification type - Class 3 ECU";
CM_ SG_ 2566734573 CertTypeVirtualTerminal "ISOBUS Compliance certification type - Virtual terminal";
CM_ SG_ 2566734573 CertTypeVTWorkingSetMaster "ISOBUS Compliance certification type - VT working set master";
CM_ SG_ 2566734573 CertTypeVTWorkingSetMember "ISOBUS Compliance certification type - VT working set member";
CM_ SG_ 2566734573 CertificationLaboratoryID "ISOBUS Compliance certification laboratory ID";
CM_ SG_ 2566734573 CertLaboratoryType_SecondDef "Approving body for the certification laboratory.";
CM_ SG_ 2566734573 TestProtocolRevision "ISOBUS compliance certificate revision";
CM_ SG_ 2566734573 TestProtocolPublicationYear "ISOBUS compliance certification year";
CM_ BO_ 2566734339 "ISOBUS compliance certification";
CM_ SG_ 2566734339 CertLaboratoryType_FirstDef "Approving body for the certification laboratory.";
CM_ SG_ 2566734339 MessageRevision "This parameter distinguishes the format of the ISOBUS Compliance Certification message in the second 
edition from the format in the third and later editions.";
CM_ SG_ 2566734339 CertificationReferenceNumber "ISOBUS Compliance certification reference number";
CM_ SG_ 2566734339 CertTypeTaskController "ISOBUS Compliance certification type - Task Controller";
CM_ SG_ 2566734339 CertTypeTCWorkingSetMaster "ISOBUS Compliance certification type - TC working set master";
CM_ SG_ 2566734339 CertTypeTCWorkingSetMember "ISOBUS Compliance certification type - TC working set member";
CM_ SG_ 2566734339 CertTypeFileServer "ISOBUS Compliance certification type - File server";
CM_ SG_ 2566734339 CertTypeGPSReceiver "ISOBUS Compliance certification type - GPS receiver";
CM_ SG_ 2566734339 CertTypeMinimumECU "ISOBUS Compliance certification type - Minimum ECU";
CM_ SG_ 2566734339 CertTypeTECUClass1 "ISOBUS Compliance certification type - TECU Class 1";
CM_ SG_ 2566734339 CertTypeTECUClass2 "ISOBUS Compliance certification type - TECU Class 2";
CM_ SG_ 2566734339 CertTypeTECUClass3 "ISOBUS Compliance certification type - TECU Class 3";
CM_ SG_ 2566734339 CertTypeClass3ECU "ISOBUS Compliance certification type - Class 3 ECU";
CM_ SG_ 2566734339 CertTypeVirtualTerminal "ISOBUS Compliance certification type - Virtual terminal";
CM_ SG_ 2566734339 CertTypeVTWorkingSetMaster "ISOBUS Compliance certification type - VT working set master";
CM_ SG_ 2566734339 CertTypeVTWorkingSetMember "ISOBUS Compliance certification type - VT working set member";
CM_ SG_ 2566734339 CertificationLaboratoryID "ISOBUS Compliance certification laboratory ID";
CM_ SG_ 2566734339 CertLaboratoryType_SecondDef "Approving body for the certification laboratory.";
CM_ SG_ 2566734339 TestProtocolRevision "ISOBUS compliance certificate revision";
CM_ SG_ 2566734339 TestProtocolPublicationYear "ISOBUS compliance certification year";
CM_ BO_ 2566734338 "ISOBUS compliance certification";
CM_ SG_ 2566734338 CertLaboratoryType_FirstDef "Approving body for the certification laboratory.";
CM_ SG_ 2566734338 MessageRevision "This parameter distinguishes the format of the ISOBUS Compliance Certification message in the second 
edition from the format in the third and later editions.";
CM_ SG_ 2566734338 CertificationReferenceNumber "ISOBUS Compliance certification reference number";
CM_ SG_ 2566734338 CertTypeTaskController "ISOBUS Compliance certification type - Task Controller";
CM_ SG_ 2566734338 CertTypeTCWorkingSetMaster "ISOBUS Compliance certification type - TC working set master";
CM_ SG_ 2566734338 CertTypeTCWorkingSetMember "ISOBUS Compliance certification type - TC working set member";
CM_ SG_ 2566734338 CertTypeFileServer "ISOBUS Compliance certification type - File server";
CM_ SG_ 2566734338 CertTypeGPSReceiver "ISOBUS Compliance certification type - GPS receiver";
CM_ SG_ 2566734338 CertTypeMinimumECU "ISOBUS Compliance certification type - Minimum ECU";
CM_ SG_ 2566734338 CertTypeTECUClass1 "ISOBUS Compliance certification type - TECU Class 1";
CM_ SG_ 2566734338 CertTypeTECUClass2 "ISOBUS Compliance certification type - TECU Class 2";
CM_ SG_ 2566734338 CertTypeTECUClass3 "ISOBUS Compliance certification type - TECU Class 3";
CM_ SG_ 2566734338 CertTypeClass3ECU "ISOBUS Compliance certification type - Class 3 ECU";
CM_ SG_ 2566734338 CertTypeVirtualTerminal "ISOBUS Compliance certification type - Virtual terminal";
CM_ SG_ 2566734338 CertTypeVTWorkingSetMaster "ISOBUS Compliance certification type - VT working set master";
CM_ SG_ 2566734338 CertTypeVTWorkingSetMember "ISOBUS Compliance certification type - VT working set member";
CM_ SG_ 2566734338 CertificationLaboratoryID "ISOBUS Compliance certification laboratory ID";
CM_ SG_ 2566734338 CertLaboratoryType_SecondDef "Approving body for the certification laboratory.";
CM_ SG_ 2566734338 TestProtocolRevision "ISOBUS compliance certificate revision";
CM_ SG_ 2566734338 TestProtocolPublicationYear "ISOBUS compliance certification year";
CM_ BO_ 2566734337 "ISOBUS compliance certification";
CM_ SG_ 2566734337 CertLaboratoryType_FirstDef "Approving body for the certification laboratory.";
CM_ SG_ 2566734337 MessageRevision "This parameter distinguishes the format of the ISOBUS Compliance Certification message in the second 
edition from the format in the third and later editions.";
CM_ SG_ 2566734337 CertificationReferenceNumber "ISOBUS Compliance certification reference number";
CM_ SG_ 2566734337 CertTypeTaskController "ISOBUS Compliance certification type - Task Controller";
CM_ SG_ 2566734337 CertTypeTCWorkingSetMaster "ISOBUS Compliance certification type - TC working set master";
CM_ SG_ 2566734337 CertTypeTCWorkingSetMember "ISOBUS Compliance certification type - TC working set member";
CM_ SG_ 2566734337 CertTypeFileServer "ISOBUS Compliance certification type - File server";
CM_ SG_ 2566734337 CertTypeGPSReceiver "ISOBUS Compliance certification type - GPS receiver";
CM_ SG_ 2566734337 CertTypeMinimumECU "ISOBUS Compliance certification type - Minimum ECU";
CM_ SG_ 2566734337 CertTypeTECUClass1 "ISOBUS Compliance certification type - TECU Class 1";
CM_ SG_ 2566734337 CertTypeTECUClass2 "ISOBUS Compliance certification type - TECU Class 2";
CM_ SG_ 2566734337 CertTypeTECUClass3 "ISOBUS Compliance certification type - TECU Class 3";
CM_ SG_ 2566734337 CertTypeClass3ECU "ISOBUS Compliance certification type - Class 3 ECU";
CM_ SG_ 2566734337 CertTypeVirtualTerminal "ISOBUS Compliance certification type - Virtual terminal";
CM_ SG_ 2566734337 CertTypeVTWorkingSetMaster "ISOBUS Compliance certification type - VT working set master";
CM_ SG_ 2566734337 CertTypeVTWorkingSetMember "ISOBUS Compliance certification type - VT working set member";
CM_ SG_ 2566734337 CertificationLaboratoryID "ISOBUS Compliance certification laboratory ID";
CM_ SG_ 2566734337 CertLaboratoryType_SecondDef "Approving body for the certification laboratory.";
CM_ SG_ 2566734337 TestProtocolRevision "ISOBUS compliance certificate revision";
CM_ SG_ 2566734337 TestProtocolPublicationYear "ISOBUS compliance certification year";
CM_ BO_ 2624650989 "TIM message: Authentication server to Authentication client";
CM_ BO_ 2624585219 "TIM message: Authentication client to Authentication server";
CM_ BO_ 2624585218 "TIM message: Authentication client to Authentication server";
CM_ BO_ 2624585217 "TIM message: Authentication client to Authentication server";
CM_ BO_ 2565799661 "Address Claimed";
CM_ SG_ 2565799661 ReservedBit "The reserved bit shall be set to zero.";
CM_ BO_ 2565799427 "Address Claimed";
CM_ SG_ 2565799427 ReservedBit "The reserved bit shall be set to zero.";
BA_DEF_  "ISO11783_11_SpecVersion" STRING ;
BA_DEF_  "ISO11783_7_SpecVersion" STRING ;
BA_DEF_  "ISO11783_6_SpecVersion" STRING ;
BA_DEF_ SG_  "DDI" INT 0 65535;
BA_DEF_ BO_  "SingleFrame" INT 0 1;
BA_DEF_ BU_  "NodeLayerModules" STRING ;
BA_DEF_  "ProtocolType" STRING ;
BA_DEF_  "BusType" STRING ;
BA_DEF_  "ISO11783_TIM_SpecVersion" STRING ;
BA_DEF_ BU_  "NmStationAddress" INT 0 255;
BA_DEF_ BU_  "NmJ1939AAC" INT 0 1;
BA_DEF_ BU_  "NmJ1939IndustryGroup" INT 0 7;
BA_DEF_ BU_  "NmJ1939Function" INT 0 255;
BA_DEF_ BU_  "NmJ1939FunctionInstance" INT 0 7;
BA_DEF_ BU_  "NmJ1939ManufacturerCode" INT 0 2047;
BA_DEF_ BU_  "NmJ1939IdentityNumber" INT 0 2097151;
BA_DEF_ BO_  "VFrameFormat" ENUM  "StandardCAN","ExtendedCAN","reserved","J1939PG","vector_leerstring";
BA_DEF_ BO_  "GenMsgSendType" ENUM  "cyclic","NotUsed","IfActive","NotUsed","NotUsed","NotUsed","NotUsed","NotUsed","noMsgSendType","vector_leerstring";
BA_DEF_ BO_  "GenMsgCycleTime" INT 0 3600000;
BA_DEF_ BO_  "GenMsgRequestable" INT 0 1;
BA_DEF_ BO_  "GenMsgCycleTimeFast" INT 0 3600000;
BA_DEF_ SG_  "SPN" INT 0 524287;
BA_DEF_  "DatabaseVersion" STRING ;
BA_DEF_ SG_  "GenSigSendType" ENUM  "Cyclic","OnWrite","OnWriteWithRepetition","OnChange","OnChangeWithRepetition","IfActive","IfActiveWithRepetition","NoSigSendType";
BA_DEF_ SG_  "SigType" ENUM  "Default","Range","RangeSigned","ASCII","Discrete","Control","ReferencePGN","DTC","StringDelimiter","StringLength","StringLengthControl","MessageCounter","MessageChecksum";
BA_DEF_  "ISO11783_12_SpecVersion" STRING ;
BA_DEF_  "ISO11783_13_SpecVersion" STRING ;
BA_DEF_ SG_  "GenSigStartValue" INT -2147483648 2147483647;
BA_DEF_ BU_  "ISO11783IOPVersion" ENUM  "0","1","2","3","4";
BA_DEF_ BU_  "ISO11783PDDVersion" ENUM  "0","1","2","3";
BA_DEF_ SG_  "SystemSignalLongSymbol" STRING ;
BA_DEF_DEF_  "ISO11783_11_SpecVersion" "";
BA_DEF_DEF_  "ISO11783_7_SpecVersion" "";
BA_DEF_DEF_  "ISO11783_6_SpecVersion" "";
BA_DEF_DEF_  "DDI" 0;
BA_DEF_DEF_  "SingleFrame" 1;
BA_DEF_DEF_  "NodeLayerModules" "";
BA_DEF_DEF_  "ProtocolType" "";
BA_DEF_DEF_  "BusType" "";
BA_DEF_DEF_  "ISO11783_TIM_SpecVersion" "";
BA_DEF_DEF_  "NmStationAddress" 254;
BA_DEF_DEF_  "NmJ1939AAC" 0;
BA_DEF_DEF_  "NmJ1939IndustryGroup" 0;
BA_DEF_DEF_  "NmJ1939Function" 0;
BA_DEF_DEF_  "NmJ1939FunctionInstance" 0;
BA_DEF_DEF_  "NmJ1939ManufacturerCode" 0;
BA_DEF_DEF_  "NmJ1939IdentityNumber" 0;
BA_DEF_DEF_  "VFrameFormat" "J1939PG";
BA_DEF_DEF_  "GenMsgSendType" "noMsgSendType";
BA_DEF_DEF_  "GenMsgCycleTime" 0;
BA_DEF_DEF_  "GenMsgRequestable" 1;
BA_DEF_DEF_  "GenMsgCycleTimeFast" 0;
BA_DEF_DEF_  "SPN" 0;
BA_DEF_DEF_  "DatabaseVersion" "";
BA_DEF_DEF_  "GenSigSendType" "NoSigSendType";
BA_DEF_DEF_  "SigType" "Default";
BA_DEF_DEF_  "ISO11783_12_SpecVersion" "";
BA_DEF_DEF_  "ISO11783_13_SpecVersion" "";
BA_DEF_DEF_  "GenSigStartValue" 0;
BA_DEF_DEF_  "ISO11783IOPVersion" "3";
BA_DEF_DEF_  "ISO11783PDDVersion" "3";
BA_DEF_DEF_  "SystemSignalLongSymbol" "";
BA_ "ISO11783_12_SpecVersion" "2013-01-29 IS (ISO/TC 23/SC 19)";
BA_ "DatabaseVersion" "7.5 SP2";
BA_ "ProtocolType" "ISO11783";
BA_ "ISO11783_6_SpecVersion" "2010-05-11 FDIS";
BA_ "ISO11783_7_SpecVersion" "2009-01-29 FDIS";
BA_ "ISO11783_11_SpecVersion" "2007-04-01 IS";
BA_ "BusType" "CAN";
BA_ "ISO11783_13_SpecVersion" "2010-01-29 2007 With Amendments ";
BA_ "ISO11783_TIM_SpecVersion" "AEF 023 DIG 0_07 ISOBUS - ISOBUS Automation Principles";
BA_ "NmJ1939ManufacturerCode" BU_ TIMClient3 1861;
BA_ "NmJ1939IndustryGroup" BU_ TIMClient3 2;
BA_ "NmJ1939AAC" BU_ TIMClient3 1;
BA_ "NmStationAddress" BU_ TIMClient3 3;
BA_ "NodeLayerModules" BU_ TIMClient3 "ISO11783_IL.dll";
BA_ "NmJ1939FunctionInstance" BU_ TIMClient3 3;
BA_ "NmJ1939ManufacturerCode" BU_ TIMClient2 1861;
BA_ "NmJ1939FunctionInstance" BU_ TIMClient2 2;
BA_ "NmJ1939IndustryGroup" BU_ TIMClient2 2;
BA_ "NmJ1939AAC" BU_ TIMClient2 1;
BA_ "NmStationAddress" BU_ TIMClient2 2;
BA_ "NodeLayerModules" BU_ TIMClient2 "ISO11783_IL.dll";
BA_ "NmJ1939ManufacturerCode" BU_ TIMClient1 1861;
BA_ "NmJ1939FunctionInstance" BU_ TIMClient1 1;
BA_ "NmJ1939IndustryGroup" BU_ TIMClient1 2;
BA_ "NmJ1939AAC" BU_ TIMClient1 1;
BA_ "NmStationAddress" BU_ TIMClient1 1;
BA_ "NodeLayerModules" BU_ TIMClient1 "ISO11783_IL.dll";
BA_ "NmJ1939ManufacturerCode" BU_ TIMServer 1861;
BA_ "NmJ1939IndustryGroup" BU_ TIMServer 2;
BA_ "NmJ1939AAC" BU_ TIMServer 1;
BA_ "NmStationAddress" BU_ TIMServer 237;
BA_ "NodeLayerModules" BU_ TIMServer "ISO11783_IL.dll";
BA_ "NmJ1939Function" BU_ TIMServer 142;
BA_ "NmJ1939IdentityNumber" BU_ TIMServer 2;
BA_ "SigType" SG_ 2619670017 CurvatureRequest 1;
BA_ "GenSigStartValue" SG_ 2619670017 CurvatureRequest 32128;
BA_ "SigType" SG_ 2619670017 VehicleSpeedRequest 1;
BA_ "GenSigStartValue" SG_ 2619670017 VehicleSpeedRequest 32128;
BA_ "SigType" SG_ 2619670017 HitchPosReq 1;
BA_ "SigType" SG_ 2619670017 PTOSpeedRequest 1;
BA_ "GenSigStartValue" SG_ 2619670017 PTOSpeedRequest 32128;
BA_ "SigType" SG_ 2619670017 AuxValveFlowReq 1;
BA_ "GenSigStartValue" SG_ 2619670017 AuxValveFlowReq 32128;
BA_ "GenSigStartValue" SG_ 2619670017 NumOfTIMFunctions 1;
BA_ "SigType" SG_ 2619670018 CurvatureRequest 1;
BA_ "GenSigStartValue" SG_ 2619670018 CurvatureRequest 32128;
BA_ "SigType" SG_ 2619670018 VehicleSpeedRequest 1;
BA_ "GenSigStartValue" SG_ 2619670018 VehicleSpeedRequest 32128;
BA_ "SigType" SG_ 2619670018 HitchPosReq 1;
BA_ "SigType" SG_ 2619670018 PTOSpeedRequest 1;
BA_ "GenSigStartValue" SG_ 2619670018 PTOSpeedRequest 32128;
BA_ "SigType" SG_ 2619670018 AuxValveFlowReq 1;
BA_ "GenSigStartValue" SG_ 2619670018 AuxValveFlowReq 32128;
BA_ "GenSigStartValue" SG_ 2619670018 NumOfTIMFunctions 1;
BA_ "SigType" SG_ 2619670019 CurvatureRequest 1;
BA_ "GenSigStartValue" SG_ 2619670019 CurvatureRequest 32128;
BA_ "SigType" SG_ 2619670019 VehicleSpeedRequest 1;
BA_ "GenSigStartValue" SG_ 2619670019 VehicleSpeedRequest 32128;
BA_ "SigType" SG_ 2619670019 HitchPosReq 1;
BA_ "SigType" SG_ 2619670019 PTOSpeedRequest 1;
BA_ "GenSigStartValue" SG_ 2619670019 PTOSpeedRequest 32128;
BA_ "SigType" SG_ 2619670019 AuxValveFlowReq 1;
BA_ "GenSigStartValue" SG_ 2619670019 AuxValveFlowReq 32128;
BA_ "GenSigStartValue" SG_ 2619670019 NumOfTIMFunctions 1;
BA_ "SigType" SG_ 2619604717 Curvature 1;
BA_ "GenSigStartValue" SG_ 2619604717 Curvature 32128;
BA_ "SigType" SG_ 2619604717 VehicleSpeed 1;
BA_ "GenSigStartValue" SG_ 2619604717 VehicleSpeed 32128;
BA_ "SigType" SG_ 2619604717 HitchPosition 1;
BA_ "SigType" SG_ 2619604717 PTOSpeed 1;
BA_ "GenSigStartValue" SG_ 2619604717 PTOSpeed 32128;
BA_ "SigType" SG_ 2619604717 TIMAuxValveFlow 1;
BA_ "GenSigStartValue" SG_ 2619604717 TIMAuxValveFlow 32128;
BA_ "GenSigStartValue" SG_ 2619604717 NumOfTIMFunctions 1;
BA_ "GenSigStartValue" SG_ 2619604717 NumOfSuportedTIMFunctions 1;
BA_ "SPN" SG_ 2566688237 ProductIdentificationCode 6699;
BA_ "SigType" SG_ 2566688237 ProductIdentificationCode 8;
BA_ "SPN" SG_ 2566688237 ProductIdentificationBrand 6701;
BA_ "SigType" SG_ 2566688237 ProductIdentificationBrand 8;
BA_ "SPN" SG_ 2566688237 ProductIdentificationModel 6701;
BA_ "SigType" SG_ 2566688237 ProductIdentificationModel 8;
BA_ "SPN" SG_ 2566688003 ProductIdentificationCode 6699;
BA_ "SigType" SG_ 2566688003 ProductIdentificationCode 8;
BA_ "SPN" SG_ 2566688003 ProductIdentificationBrand 6701;
BA_ "SigType" SG_ 2566688003 ProductIdentificationBrand 8;
BA_ "SPN" SG_ 2566688003 ProductIdentificationModel 6701;
BA_ "SigType" SG_ 2566688003 ProductIdentificationModel 8;
BA_ "SPN" SG_ 2566688002 ProductIdentificationCode 6699;
BA_ "SigType" SG_ 2566688002 ProductIdentificationCode 8;
BA_ "SPN" SG_ 2566688002 ProductIdentificationBrand 6701;
BA_ "SigType" SG_ 2566688002 ProductIdentificationBrand 8;
BA_ "SPN" SG_ 2566688002 ProductIdentificationModel 6701;
BA_ "SigType" SG_ 2566688002 ProductIdentificationModel 8;
BA_ "SPN" SG_ 2566688001 ProductIdentificationCode 6699;
BA_ "SigType" SG_ 2566688001 ProductIdentificationCode 8;
BA_ "SPN" SG_ 2566688001 ProductIdentificationBrand 6701;
BA_ "SigType" SG_ 2566688001 ProductIdentificationBrand 8;
BA_ "SPN" SG_ 2566688001 ProductIdentificationModel 6701;
BA_ "SigType" SG_ 2566688001 ProductIdentificationModel 8;
BA_ "SPN" SG_ 2566734573 CertLaboratoryType_FirstDef 4315;
BA_ "SPN" SG_ 2566734573 MessageRevision 7446;
BA_ "SPN" SG_ 2566734573 CertificationReferenceNumber 4330;
BA_ "SPN" SG_ 2566734573 CertTypeTaskController 4325;
BA_ "SPN" SG_ 2566734573 CertTypeTCWorkingSetMaster 4326;
BA_ "SPN" SG_ 2566734573 CertTypeTCWorkingSetMember 4327;
BA_ "SPN" SG_ 2566734573 CertTypeFileServer 4328;
BA_ "SPN" SG_ 2566734573 CertTypeGPSReceiver 4329;
BA_ "SPN" SG_ 2566734573 CertTypeMinimumECU 4317;
BA_ "SPN" SG_ 2566734573 CertTypeTECUClass1 4318;
BA_ "SPN" SG_ 2566734573 CertTypeTECUClass2 4319;
BA_ "SPN" SG_ 2566734573 CertTypeTECUClass3 4320;
BA_ "SPN" SG_ 2566734573 CertTypeClass3ECU 4321;
BA_ "SPN" SG_ 2566734573 CertTypeVirtualTerminal 4322;
BA_ "SPN" SG_ 2566734573 CertTypeVTWorkingSetMaster 4323;
BA_ "SPN" SG_ 2566734573 CertTypeVTWorkingSetMember 4324;
BA_ "SPN" SG_ 2566734573 CertificationLaboratoryID 4316;
BA_ "SPN" SG_ 2566734573 CertLaboratoryType_SecondDef 4315;
BA_ "SPN" SG_ 2566734573 TestProtocolRevision 4314;
BA_ "SPN" SG_ 2566734573 TestProtocolPublicationYear 4313;
BA_ "SPN" SG_ 2566734339 CertLaboratoryType_FirstDef 4315;
BA_ "SPN" SG_ 2566734339 MessageRevision 7446;
BA_ "SPN" SG_ 2566734339 CertificationReferenceNumber 4330;
BA_ "SPN" SG_ 2566734339 CertTypeTaskController 4325;
BA_ "SPN" SG_ 2566734339 CertTypeTCWorkingSetMaster 4326;
BA_ "SPN" SG_ 2566734339 CertTypeTCWorkingSetMember 4327;
BA_ "SPN" SG_ 2566734339 CertTypeFileServer 4328;
BA_ "SPN" SG_ 2566734339 CertTypeGPSReceiver 4329;
BA_ "SPN" SG_ 2566734339 CertTypeMinimumECU 4317;
BA_ "SPN" SG_ 2566734339 CertTypeTECUClass1 4318;
BA_ "SPN" SG_ 2566734339 CertTypeTECUClass2 4319;
BA_ "SPN" SG_ 2566734339 CertTypeTECUClass3 4320;
BA_ "SPN" SG_ 2566734339 CertTypeClass3ECU 4321;
BA_ "SPN" SG_ 2566734339 CertTypeVirtualTerminal 4322;
BA_ "SPN" SG_ 2566734339 CertTypeVTWorkingSetMaster 4323;
BA_ "SPN" SG_ 2566734339 CertTypeVTWorkingSetMember 4324;
BA_ "SPN" SG_ 2566734339 CertificationLaboratoryID 4316;
BA_ "SPN" SG_ 2566734339 CertLaboratoryType_SecondDef 4315;
BA_ "SPN" SG_ 2566734339 TestProtocolRevision 4314;
BA_ "SPN" SG_ 2566734339 TestProtocolPublicationYear 4313;
BA_ "SPN" SG_ 2566734338 CertLaboratoryType_FirstDef 4315;
BA_ "SPN" SG_ 2566734338 MessageRevision 7446;
BA_ "SPN" SG_ 2566734338 CertificationReferenceNumber 4330;
BA_ "SPN" SG_ 2566734338 CertTypeTaskController 4325;
BA_ "SPN" SG_ 2566734338 CertTypeTCWorkingSetMaster 4326;
BA_ "SPN" SG_ 2566734338 CertTypeTCWorkingSetMember 4327;
BA_ "SPN" SG_ 2566734338 CertTypeFileServer 4328;
BA_ "SPN" SG_ 2566734338 CertTypeGPSReceiver 4329;
BA_ "SPN" SG_ 2566734338 CertTypeMinimumECU 4317;
BA_ "SPN" SG_ 2566734338 CertTypeTECUClass1 4318;
BA_ "SPN" SG_ 2566734338 CertTypeTECUClass2 4319;
BA_ "SPN" SG_ 2566734338 CertTypeTECUClass3 4320;
BA_ "SPN" SG_ 2566734338 CertTypeClass3ECU 4321;
BA_ "SPN" SG_ 2566734338 CertTypeVirtualTerminal 4322;
BA_ "SPN" SG_ 2566734338 CertTypeVTWorkingSetMaster 4323;
BA_ "SPN" SG_ 2566734338 CertTypeVTWorkingSetMember 4324;
BA_ "SPN" SG_ 2566734338 CertificationLaboratoryID 4316;
BA_ "SPN" SG_ 2566734338 CertLaboratoryType_SecondDef 4315;
BA_ "SPN" SG_ 2566734338 TestProtocolRevision 4314;
BA_ "SPN" SG_ 2566734338 TestProtocolPublicationYear 4313;
BA_ "SPN" SG_ 2566734337 CertLaboratoryType_FirstDef 4315;
BA_ "SPN" SG_ 2566734337 MessageRevision 7446;
BA_ "SPN" SG_ 2566734337 CertificationReferenceNumber 4330;
BA_ "SPN" SG_ 2566734337 CertTypeTaskController 4325;
BA_ "SPN" SG_ 2566734337 CertTypeTCWorkingSetMaster 4326;
BA_ "SPN" SG_ 2566734337 CertTypeTCWorkingSetMember 4327;
BA_ "SPN" SG_ 2566734337 CertTypeFileServer 4328;
BA_ "SPN" SG_ 2566734337 CertTypeGPSReceiver 4329;
BA_ "SPN" SG_ 2566734337 CertTypeMinimumECU 4317;
BA_ "SPN" SG_ 2566734337 CertTypeTECUClass1 4318;
BA_ "SPN" SG_ 2566734337 CertTypeTECUClass2 4319;
BA_ "SPN" SG_ 2566734337 CertTypeTECUClass3 4320;
BA_ "SPN" SG_ 2566734337 CertTypeClass3ECU 4321;
BA_ "SPN" SG_ 2566734337 CertTypeVirtualTerminal 4322;
BA_ "SPN" SG_ 2566734337 CertTypeVTWorkingSetMaster 4323;
BA_ "SPN" SG_ 2566734337 CertTypeVTWorkingSetMember 4324;
BA_ "SPN" SG_ 2566734337 CertificationLaboratoryID 4316;
BA_ "SPN" SG_ 2566734337 CertLaboratoryType_SecondDef 4315;
BA_ "SPN" SG_ 2566734337 TestProtocolRevision 4314;
BA_ "SPN" SG_ 2566734337 TestProtocolPublicationYear 4313;
BA_ "SigType" SG_ 2624650989 ChallengeData 9;
BA_ "SigType" SG_ 2624650989 CertificateData 9;
BA_ "SigType" SG_ 2624585219 ChallengeData 9;
BA_ "SigType" SG_ 2624585219 CertificateData 9;
BA_ "SigType" SG_ 2624585218 ChallengeData 9;
BA_ "SigType" SG_ 2624585218 CertificateData 9;
BA_ "SigType" SG_ 2624585217 ChallengeData 9;
BA_ "SigType" SG_ 2624585217 CertificateData 9;
BA_ "SPN" SG_ 2565799661 ArbitraryAddressCapable 2844;
BA_ "SPN" SG_ 2565799661 IndustryGroup 2846;
BA_ "SPN" SG_ 2565799661 VehicleSystemInstance 2843;
BA_ "SPN" SG_ 2565799661 Function 2841;
BA_ "SPN" SG_ 2565799661 FunctionInstance 2839;
BA_ "SPN" SG_ 2565799661 ECUInstance 2840;
BA_ "SigType" SG_ 2565799661 ManufacturerCode 1;
BA_ "SPN" SG_ 2565799661 ManufacturerCode 2838;
BA_ "SPN" SG_ 2565799661 IdentityNumber 2837;
BA_ "SPN" SG_ 2565799427 ArbitraryAddressCapable 2844;
BA_ "SPN" SG_ 2565799427 IndustryGroup 2846;
BA_ "SPN" SG_ 2565799427 VehicleSystemInstance 2843;
BA_ "SPN" SG_ 2565799427 Function 2841;
BA_ "SPN" SG_ 2565799427 FunctionInstance 2839;
BA_ "SPN" SG_ 2565799427 ECUInstance 2840;
BA_ "SigType" SG_ 2565799427 ManufacturerCode 1;
BA_ "SPN" SG_ 2565799427 ManufacturerCode 2838;
BA_ "SPN" SG_ 2565799427 IdentityNumber 2837;
VAL_ 2619670017 CurvatureRequest 64511 "ReadyToControl" 64509 "RequestingOperatorAwareness" 32128 "Straight" ;
VAL_ 2619670017 VehicleSpeedRequest 64511 "ReadyToControl" 64510 "AcceptFunctionWithoutOperatorAwareness " 64509 "RequestingOperatorAwareness" 64256 "ForwardSpeedSetByTimServer" 32128 "Stop" 0 "ReverseSpeedSetByTimServer" ;
VAL_ 2619670017 HitchPosReq 64259 "RaiseUntilStopRequest" 64258 "LowerUntilStopRequest" 64511 "ReadyToControl" 64509 "RequestingOperatorAction" 64257 "Stop" 64256 "Float" ;
VAL_ 2619670017 PTOSpeedRequest 64511 "ReadyToControl" 64509 "RequestingOperatorAction" 64256 "On_SpeedClockwiseSetByTimServer" 32128 "Off" 0 "On_SpeedCounterClockwiseSetByTimServer" ;
VAL_ 2619670017 RequestCounter 15 "NotAvailable_DontCare " 14 "Reserved" ;
VAL_ 2619670017 AuxValveFlowReq 64511 "ReadyToControl" 64509 "ReleasedControlRequestingOperatorActionBeforeFunctionValueIncreases" 64257 "Float" 64256 "ValveFullyOpened_Retract" 32128 "Block" 0 "ValveFullyOpened_Extend" ;
VAL_ 2619670017 TIMClientState 13 "AutomationFault" 5 "AutomationActive" 15 "NotAvailable" 14 "Error" 3 "AutomationEnabled" 2 "AutomationReadyToEnable" 1 "AutomationNotReady" 0 "AutomationUnavailable" ;
VAL_ 2619670017 ClientHearbeatCounter 255 "GracefulShutdown" 254 "ErrorConditionOnSender" 251 "ResetOfHeartbeatCounter" ;
VAL_ 2619670017 TIMFunctionId_4 32 "AuxValve32" 70 "ExternalGuidance" 68 "VehicleSpeed" 67 "RearHitch" 66 "FrontHitch" 65 "RearPTO" 64 "FrontPTO" 31 "AuxValve31" 30 "AuxValve30" 29 "AuxValve29" 28 "AuxValve28" 27 "AuxValve27" 26 "AuxValve26" 25 "AuxValve25" 24 "AuxValve24" 23 "AuxValve23" 22 "AuxValve22" 21 "AuxValve21" 20 "AuxValve20" 19 "AuxValve19" 18 "AuxValve18" 17 "AuxValve17" 16 "AuxValve16" 15 "AuxValve15" 14 "AuxValve14" 13 "AuxValve13" 12 "AuxValve12" 11 "AuxValve11" 10 "AuxValve10" 9 "AuxValve9" 8 "AuxValve8" 7 "AuxValve7" 6 "AuxValve6" 5 "AuxValve5" 4 "AuxValve4" 3 "AuxValve3" 2 "AuxValve2" 1 "AuxValve1" ;
VAL_ 2619670017 TIMFunctionId_3 32 "AuxValve32" 70 "ExternalGuidance" 68 "VehicleSpeed" 67 "RearHitch" 66 "FrontHitch" 65 "RearPTO" 64 "FrontPTO" 31 "AuxValve31" 30 "AuxValve30" 29 "AuxValve29" 28 "AuxValve28" 27 "AuxValve27" 26 "AuxValve26" 25 "AuxValve25" 24 "AuxValve24" 23 "AuxValve23" 22 "AuxValve22" 21 "AuxValve21" 20 "AuxValve20" 19 "AuxValve19" 18 "AuxValve18" 17 "AuxValve17" 16 "AuxValve16" 15 "AuxValve15" 14 "AuxValve14" 13 "AuxValve13" 12 "AuxValve12" 11 "AuxValve11" 10 "AuxValve10" 9 "AuxValve9" 8 "AuxValve8" 7 "AuxValve7" 6 "AuxValve6" 5 "AuxValve5" 4 "AuxValve4" 3 "AuxValve3" 2 "AuxValve2" 1 "AuxValve1" ;
VAL_ 2619670017 TIMFunctionId_2 32 "AuxValve32" 70 "ExternalGuidance" 68 "VehicleSpeed" 67 "RearHitch" 66 "FrontHitch" 65 "RearPTO" 64 "FrontPTO" 31 "AuxValve31" 30 "AuxValve30" 29 "AuxValve29" 28 "AuxValve28" 27 "AuxValve27" 26 "AuxValve26" 25 "AuxValve25" 24 "AuxValve24" 23 "AuxValve23" 22 "AuxValve22" 21 "AuxValve21" 20 "AuxValve20" 19 "AuxValve19" 18 "AuxValve18" 17 "AuxValve17" 16 "AuxValve16" 15 "AuxValve15" 14 "AuxValve14" 13 "AuxValve13" 12 "AuxValve12" 11 "AuxValve11" 10 "AuxValve10" 9 "AuxValve9" 8 "AuxValve8" 7 "AuxValve7" 6 "AuxValve6" 5 "AuxValve5" 4 "AuxValve4" 3 "AuxValve3" 2 "AuxValve2" 1 "AuxValve1" ;
VAL_ 2619670017 TIMFunctionId_1 32 "AuxValve32" 70 "ExternalGuidance" 68 "VehicleSpeed" 67 "RearHitch" 66 "FrontHitch" 65 "RearPTO" 64 "FrontPTO" 31 "AuxValve31" 30 "AuxValve30" 29 "AuxValve29" 28 "AuxValve28" 27 "AuxValve27" 26 "AuxValve26" 25 "AuxValve25" 24 "AuxValve24" 23 "AuxValve23" 22 "AuxValve22" 21 "AuxValve21" 20 "AuxValve20" 19 "AuxValve19" 18 "AuxValve18" 17 "AuxValve17" 16 "AuxValve16" 15 "AuxValve15" 14 "AuxValve14" 13 "AuxValve13" 12 "AuxValve12" 11 "AuxValve11" 10 "AuxValve10" 9 "AuxValve9" 8 "AuxValve8" 7 "AuxValve7" 6 "AuxValve6" 5 "AuxValve5" 4 "AuxValve4" 3 "AuxValve3" 2 "AuxValve2" 1 "AuxValve1" ;
VAL_ 2619670017 RequestType_4 7 "DontCare" 6 "Error" 1 "AssignToRequestingClient" 0 "ReleaseAssignmentOfRequestingClient" ;
VAL_ 2619670017 RequestType_3 7 "DontCare" 6 "Error" 1 "AssignToRequestingClient" 0 "ReleaseAssignmentOfRequestingClient" ;
VAL_ 2619670017 RequestType_2 7 "DontCare" 6 "Error" 1 "AssignToRequestingClient" 0 "ReleaseAssignmentOfRequestingClient" ;
VAL_ 2619670017 RequestType_1 7 "DontCare" 6 "Error" 1 "AssignToRequestingClient" 0 "ReleaseAssignmentOfRequestingClient" ;
VAL_ 2619670017 TIMMessageType 1 "TIMFunctionStatus" 0 "TIMFunctionRequest" ;
VAL_ 2619670017 GroupFunctionValue 32 "TIM_AuxValve32Request" 249 "ClientStatus" 248 "ServerVersionRequest" 247 "ClientVersionResponse" 246 "ConnectionVersionRequest" 245 "FunctionsAssignmentRequest" 244 "FunctionsSupportRequest" 243 "FunctionsAssignmentStatusRequest" 70 "ExternalGuidanceRequest" 68 "VehicleSpeedRequest" 67 "RearHitchRequest" 66 "FrontHitchRequest" 65 "RearPTORequest" 64 "FrontPTORequest" 31 "TIM_AuxValve31Request" 30 "TIM_AuxValve30Request" 29 "TIM_AuxValve29Request" 28 "TIM_AuxValve28Request" 27 "TIM_AuxValve27Request" 26 "TIM_AuxValve26Request" 25 "TIM_AuxValve25Request" 24 "TIM_AuxValve24Request" 23 "TIM_AuxValve23Request" 22 "TIM_AuxValve22Request" 21 "TIM_AuxValve21Request" 20 "TIM_AuxValve20Request" 19 "TIM_AuxValve19Request" 18 "TIM_AuxValve18Request" 17 "TIM_AuxValve17Request" 16 "TIM_AuxValve16Request" 15 "TIM_AuxValve15Request" 14 "TIM_AuxValve14Request" 13 "TIM_AuxValve13Request" 12 "TIM_AuxValve12Request" 11 "TIM_AuxValve11Request" 10 "TIM_AuxValve10Request" 9 "TIM_AuxValve9Request" 8 "TIM_AuxValve8Request" 7 "TIM_AuxValve7Request" 6 "TIM_AuxValve6Request" 5 "TIM_AuxValve5Request" 4 "TIM_AuxValve4Request" 3 "TIM_AuxValve3Request" 2 "TIM_AuxValve2Request" 1 "TIM_AuxValve1Request" ;
VAL_ 2619670018 CurvatureRequest 64511 "ReadyToControl" 64509 "RequestingOperatorAwareness" 32128 "Straight" ;
VAL_ 2619670018 VehicleSpeedRequest 64511 "ReadyToControl" 64510 "AcceptFunctionWithoutOperatorAwareness " 64509 "RequestingOperatorAwareness" 64256 "ForwardSpeedSetByTimServer" 32128 "Stop" 0 "ReverseSpeedSetByTimServer" ;
VAL_ 2619670018 HitchPosReq 64259 "RaiseUntilStopRequest" 64258 "LowerUntilStopRequest" 64511 "ReadyToControl" 64509 "RequestingOperatorAction" 64257 "Stop" 64256 "Float" ;
VAL_ 2619670018 PTOSpeedRequest 64511 "ReadyToControl" 64509 "RequestingOperatorAction" 64256 "On_SpeedClockwiseSetByTimServer" 32128 "Off" 0 "On_SpeedCounterClockwiseSetByTimServer" ;
VAL_ 2619670018 RequestCounter 15 "NotAvailable_DontCare " 14 "Reserved" ;
VAL_ 2619670018 AuxValveFlowReq 64511 "ReadyToControl" 64509 "ReleasedControlRequestingOperatorActionBeforeFunctionValueIncreases" 64257 "Float" 64256 "ValveFullyOpened_Retract" 32128 "Block" 0 "ValveFullyOpened_Extend" ;
VAL_ 2619670018 TIMClientState 13 "AutomationFault" 5 "AutomationActive" 15 "NotAvailable" 14 "Error" 3 "AutomationEnabled" 2 "AutomationReadyToEnable" 1 "AutomationNotReady" 0 "AutomationUnavailable" ;
VAL_ 2619670018 ClientHearbeatCounter 255 "GracefulShutdown" 254 "ErrorConditionOnSender" 251 "ResetOfHeartbeatCounter" ;
VAL_ 2619670018 TIMFunctionId_4 32 "AuxValve32" 70 "ExternalGuidance" 68 "VehicleSpeed" 67 "RearHitch" 66 "FrontHitch" 65 "RearPTO" 64 "FrontPTO" 31 "AuxValve31" 30 "AuxValve30" 29 "AuxValve29" 28 "AuxValve28" 27 "AuxValve27" 26 "AuxValve26" 25 "AuxValve25" 24 "AuxValve24" 23 "AuxValve23" 22 "AuxValve22" 21 "AuxValve21" 20 "AuxValve20" 19 "AuxValve19" 18 "AuxValve18" 17 "AuxValve17" 16 "AuxValve16" 15 "AuxValve15" 14 "AuxValve14" 13 "AuxValve13" 12 "AuxValve12" 11 "AuxValve11" 10 "AuxValve10" 9 "AuxValve9" 8 "AuxValve8" 7 "AuxValve7" 6 "AuxValve6" 5 "AuxValve5" 4 "AuxValve4" 3 "AuxValve3" 2 "AuxValve2" 1 "AuxValve1" ;
VAL_ 2619670018 TIMFunctionId_3 32 "AuxValve32" 70 "ExternalGuidance" 68 "VehicleSpeed" 67 "RearHitch" 66 "FrontHitch" 65 "RearPTO" 64 "FrontPTO" 31 "AuxValve31" 30 "AuxValve30" 29 "AuxValve29" 28 "AuxValve28" 27 "AuxValve27" 26 "AuxValve26" 25 "AuxValve25" 24 "AuxValve24" 23 "AuxValve23" 22 "AuxValve22" 21 "AuxValve21" 20 "AuxValve20" 19 "AuxValve19" 18 "AuxValve18" 17 "AuxValve17" 16 "AuxValve16" 15 "AuxValve15" 14 "AuxValve14" 13 "AuxValve13" 12 "AuxValve12" 11 "AuxValve11" 10 "AuxValve10" 9 "AuxValve9" 8 "AuxValve8" 7 "AuxValve7" 6 "AuxValve6" 5 "AuxValve5" 4 "AuxValve4" 3 "AuxValve3" 2 "AuxValve2" 1 "AuxValve1" ;
VAL_ 2619670018 TIMFunctionId_2 32 "AuxValve32" 70 "ExternalGuidance" 68 "VehicleSpeed" 67 "RearHitch" 66 "FrontHitch" 65 "RearPTO" 64 "FrontPTO" 31 "AuxValve31" 30 "AuxValve30" 29 "AuxValve29" 28 "AuxValve28" 27 "AuxValve27" 26 "AuxValve26" 25 "AuxValve25" 24 "AuxValve24" 23 "AuxValve23" 22 "AuxValve22" 21 "AuxValve21" 20 "AuxValve20" 19 "AuxValve19" 18 "AuxValve18" 17 "AuxValve17" 16 "AuxValve16" 15 "AuxValve15" 14 "AuxValve14" 13 "AuxValve13" 12 "AuxValve12" 11 "AuxValve11" 10 "AuxValve10" 9 "AuxValve9" 8 "AuxValve8" 7 "AuxValve7" 6 "AuxValve6" 5 "AuxValve5" 4 "AuxValve4" 3 "AuxValve3" 2 "AuxValve2" 1 "AuxValve1" ;
VAL_ 2619670018 TIMFunctionId_1 32 "AuxValve32" 70 "ExternalGuidance" 68 "VehicleSpeed" 67 "RearHitch" 66 "FrontHitch" 65 "RearPTO" 64 "FrontPTO" 31 "AuxValve31" 30 "AuxValve30" 29 "AuxValve29" 28 "AuxValve28" 27 "AuxValve27" 26 "AuxValve26" 25 "AuxValve25" 24 "AuxValve24" 23 "AuxValve23" 22 "AuxValve22" 21 "AuxValve21" 20 "AuxValve20" 19 "AuxValve19" 18 "AuxValve18" 17 "AuxValve17" 16 "AuxValve16" 15 "AuxValve15" 14 "AuxValve14" 13 "AuxValve13" 12 "AuxValve12" 11 "AuxValve11" 10 "AuxValve10" 9 "AuxValve9" 8 "AuxValve8" 7 "AuxValve7" 6 "AuxValve6" 5 "AuxValve5" 4 "AuxValve4" 3 "AuxValve3" 2 "AuxValve2" 1 "AuxValve1" ;
VAL_ 2619670018 RequestType_4 7 "DontCare" 6 "Error" 1 "AssignToRequestingClient" 0 "ReleaseAssignmentOfRequestingClient" ;
VAL_ 2619670018 RequestType_3 7 "DontCare" 6 "Error" 1 "AssignToRequestingClient" 0 "ReleaseAssignmentOfRequestingClient" ;
VAL_ 2619670018 RequestType_2 7 "DontCare" 6 "Error" 1 "AssignToRequestingClient" 0 "ReleaseAssignmentOfRequestingClient" ;
VAL_ 2619670018 RequestType_1 7 "DontCare" 6 "Error" 1 "AssignToRequestingClient" 0 "ReleaseAssignmentOfRequestingClient" ;
VAL_ 2619670018 TIMMessageType 1 "TIMFunctionStatus" 0 "TIMFunctionRequest" ;
VAL_ 2619670018 GroupFunctionValue 32 "TIM_AuxValve32Request" 249 "ClientStatus" 248 "ServerVersionRequest" 247 "ClientVersionResponse" 246 "ConnectionVersionRequest" 245 "FunctionsAssignmentRequest" 244 "FunctionsSupportRequest" 243 "FunctionsAssignmentStatusRequest" 70 "ExternalGuidanceRequest" 68 "VehicleSpeedRequest" 67 "RearHitchRequest" 66 "FrontHitchRequest" 65 "RearPTORequest" 64 "FrontPTORequest" 31 "TIM_AuxValve31Request" 30 "TIM_AuxValve30Request" 29 "TIM_AuxValve29Request" 28 "TIM_AuxValve28Request" 27 "TIM_AuxValve27Request" 26 "TIM_AuxValve26Request" 25 "TIM_AuxValve25Request" 24 "TIM_AuxValve24Request" 23 "TIM_AuxValve23Request" 22 "TIM_AuxValve22Request" 21 "TIM_AuxValve21Request" 20 "TIM_AuxValve20Request" 19 "TIM_AuxValve19Request" 18 "TIM_AuxValve18Request" 17 "TIM_AuxValve17Request" 16 "TIM_AuxValve16Request" 15 "TIM_AuxValve15Request" 14 "TIM_AuxValve14Request" 13 "TIM_AuxValve13Request" 12 "TIM_AuxValve12Request" 11 "TIM_AuxValve11Request" 10 "TIM_AuxValve10Request" 9 "TIM_AuxValve9Request" 8 "TIM_AuxValve8Request" 7 "TIM_AuxValve7Request" 6 "TIM_AuxValve6Request" 5 "TIM_AuxValve5Request" 4 "TIM_AuxValve4Request" 3 "TIM_AuxValve3Request" 2 "TIM_AuxValve2Request" 1 "TIM_AuxValve1Request" ;
VAL_ 2619670019 CurvatureRequest 64511 "ReadyToControl" 64509 "RequestingOperatorAwareness" 32128 "Straight" ;
VAL_ 2619670019 VehicleSpeedRequest 64511 "ReadyToControl" 64510 "AcceptFunctionWithoutOperatorAwareness " 64509 "RequestingOperatorAwareness" 64256 "ForwardSpeedSetByTimServer" 32128 "Stop" 0 "ReverseSpeedSetByTimServer" ;
VAL_ 2619670019 HitchPosReq 64259 "RaiseUntilStopRequest" 64258 "LowerUntilStopRequest" 64511 "ReadyToControl" 64509 "RequestingOperatorAction" 64257 "Stop" 64256 "Float" ;
VAL_ 2619670019 PTOSpeedRequest 64511 "ReadyToControl" 64509 "RequestingOperatorAction" 64256 "On_SpeedClockwiseSetByTimServer" 32128 "Off" 0 "On_SpeedCounterClockwiseSetByTimServer" ;
VAL_ 2619670019 RequestCounter 15 "NotAvailable_DontCare " 14 "Reserved" ;
VAL_ 2619670019 AuxValveFlowReq 64511 "ReadyToControl" 64509 "ReleasedControlRequestingOperatorActionBeforeFunctionValueIncreases" 64257 "Float" 64256 "ValveFullyOpened_Retract" 32128 "Block" 0 "ValveFullyOpened_Extend" ;
VAL_ 2619670019 TIMClientState 13 "AutomationFault" 5 "AutomationActive" 15 "NotAvailable" 14 "Error" 3 "AutomationEnabled" 2 "AutomationReadyToEnable" 1 "AutomationNotReady" 0 "AutomationUnavailable" ;
VAL_ 2619670019 ClientHearbeatCounter 255 "GracefulShutdown" 254 "ErrorConditionOnSender" 251 "ResetOfHeartbeatCounter" ;
VAL_ 2619670019 TIMFunctionId_4 32 "AuxValve32" 70 "ExternalGuidance" 68 "VehicleSpeed" 67 "RearHitch" 66 "FrontHitch" 65 "RearPTO" 64 "FrontPTO" 31 "AuxValve31" 30 "AuxValve30" 29 "AuxValve29" 28 "AuxValve28" 27 "AuxValve27" 26 "AuxValve26" 25 "AuxValve25" 24 "AuxValve24" 23 "AuxValve23" 22 "AuxValve22" 21 "AuxValve21" 20 "AuxValve20" 19 "AuxValve19" 18 "AuxValve18" 17 "AuxValve17" 16 "AuxValve16" 15 "AuxValve15" 14 "AuxValve14" 13 "AuxValve13" 12 "AuxValve12" 11 "AuxValve11" 10 "AuxValve10" 9 "AuxValve9" 8 "AuxValve8" 7 "AuxValve7" 6 "AuxValve6" 5 "AuxValve5" 4 "AuxValve4" 3 "AuxValve3" 2 "AuxValve2" 1 "AuxValve1" ;
VAL_ 2619670019 TIMFunctionId_3 32 "AuxValve32" 70 "ExternalGuidance" 68 "VehicleSpeed" 67 "RearHitch" 66 "FrontHitch" 65 "RearPTO" 64 "FrontPTO" 31 "AuxValve31" 30 "AuxValve30" 29 "AuxValve29" 28 "AuxValve28" 27 "AuxValve27" 26 "AuxValve26" 25 "AuxValve25" 24 "AuxValve24" 23 "AuxValve23" 22 "AuxValve22" 21 "AuxValve21" 20 "AuxValve20" 19 "AuxValve19" 18 "AuxValve18" 17 "AuxValve17" 16 "AuxValve16" 15 "AuxValve15" 14 "AuxValve14" 13 "AuxValve13" 12 "AuxValve12" 11 "AuxValve11" 10 "AuxValve10" 9 "AuxValve9" 8 "AuxValve8" 7 "AuxValve7" 6 "AuxValve6" 5 "AuxValve5" 4 "AuxValve4" 3 "AuxValve3" 2 "AuxValve2" 1 "AuxValve1" ;
VAL_ 2619670019 TIMFunctionId_2 32 "AuxValve32" 70 "ExternalGuidance" 68 "VehicleSpeed" 67 "RearHitch" 66 "FrontHitch" 65 "RearPTO" 64 "FrontPTO" 31 "AuxValve31" 30 "AuxValve30" 29 "AuxValve29" 28 "AuxValve28" 27 "AuxValve27" 26 "AuxValve26" 25 "AuxValve25" 24 "AuxValve24" 23 "AuxValve23" 22 "AuxValve22" 21 "AuxValve21" 20 "AuxValve20" 19 "AuxValve19" 18 "AuxValve18" 17 "AuxValve17" 16 "AuxValve16" 15 "AuxValve15" 14 "AuxValve14" 13 "AuxValve13" 12 "AuxValve12" 11 "AuxValve11" 10 "AuxValve10" 9 "AuxValve9" 8 "AuxValve8" 7 "AuxValve7" 6 "AuxValve6" 5 "AuxValve5" 4 "AuxValve4" 3 "AuxValve3" 2 "AuxValve2" 1 "AuxValve1" ;
VAL_ 2619670019 TIMFunctionId_1 32 "AuxValve32" 70 "ExternalGuidance" 68 "VehicleSpeed" 67 "RearHitch" 66 "FrontHitch" 65 "RearPTO" 64 "FrontPTO" 31 "AuxValve31" 30 "AuxValve30" 29 "AuxValve29" 28 "AuxValve28" 27 "AuxValve27" 26 "AuxValve26" 25 "AuxValve25" 24 "AuxValve24" 23 "AuxValve23" 22 "AuxValve22" 21 "AuxValve21" 20 "AuxValve20" 19 "AuxValve19" 18 "AuxValve18" 17 "AuxValve17" 16 "AuxValve16" 15 "AuxValve15" 14 "AuxValve14" 13 "AuxValve13" 12 "AuxValve12" 11 "AuxValve11" 10 "AuxValve10" 9 "AuxValve9" 8 "AuxValve8" 7 "AuxValve7" 6 "AuxValve6" 5 "AuxValve5" 4 "AuxValve4" 3 "AuxValve3" 2 "AuxValve2" 1 "AuxValve1" ;
VAL_ 2619670019 RequestType_4 7 "DontCare" 6 "Error" 1 "AssignToRequestingClient" 0 "ReleaseAssignmentOfRequestingClient" ;
VAL_ 2619670019 RequestType_3 7 "DontCare" 6 "Error" 1 "AssignToRequestingClient" 0 "ReleaseAssignmentOfRequestingClient" ;
VAL_ 2619670019 RequestType_2 7 "DontCare" 6 "Error" 1 "AssignToRequestingClient" 0 "ReleaseAssignmentOfRequestingClient" ;
VAL_ 2619670019 RequestType_1 7 "DontCare" 6 "Error" 1 "AssignToRequestingClient" 0 "ReleaseAssignmentOfRequestingClient" ;
VAL_ 2619670019 TIMMessageType 1 "TIMFunctionStatus" 0 "TIMFunctionRequest" ;
VAL_ 2619670019 GroupFunctionValue 32 "TIM_AuxValve32Request" 249 "ClientStatus" 248 "ServerVersionRequest" 247 "ClientVersionResponse" 246 "ConnectionVersionRequest" 245 "FunctionsAssignmentRequest" 244 "FunctionsSupportRequest" 243 "FunctionsAssignmentStatusRequest" 70 "ExternalGuidanceRequest" 68 "VehicleSpeedRequest" 67 "RearHitchRequest" 66 "FrontHitchRequest" 65 "RearPTORequest" 64 "FrontPTORequest" 31 "TIM_AuxValve31Request" 30 "TIM_AuxValve30Request" 29 "TIM_AuxValve29Request" 28 "TIM_AuxValve28Request" 27 "TIM_AuxValve27Request" 26 "TIM_AuxValve26Request" 25 "TIM_AuxValve25Request" 24 "TIM_AuxValve24Request" 23 "TIM_AuxValve23Request" 22 "TIM_AuxValve22Request" 21 "TIM_AuxValve21Request" 20 "TIM_AuxValve20Request" 19 "TIM_AuxValve19Request" 18 "TIM_AuxValve18Request" 17 "TIM_AuxValve17Request" 16 "TIM_AuxValve16Request" 15 "TIM_AuxValve15Request" 14 "TIM_AuxValve14Request" 13 "TIM_AuxValve13Request" 12 "TIM_AuxValve12Request" 11 "TIM_AuxValve11Request" 10 "TIM_AuxValve10Request" 9 "TIM_AuxValve9Request" 8 "TIM_AuxValve8Request" 7 "TIM_AuxValve7Request" 6 "TIM_AuxValve6Request" 5 "TIM_AuxValve5Request" 4 "TIM_AuxValve4Request" 3 "TIM_AuxValve3Request" 2 "TIM_AuxValve2Request" 1 "TIM_AuxValve1Request" ;
VAL_ 2619604717 Curvature 32128 "Straight" ;
VAL_ 2619604717 GuidanceExitReasonCode 21 "HydraulicOilLevelTooLow" 20 "HydraulicOilTemperatureTooLow" 19 "VehicleTransmissionGearDoesntAllowRemoteCommands" 18 "VehicleSpeedTooLow" 17 "VehicleSpeedTooHigh" 16 "AlternateGuidanceSystemActive" 31 "NotAvailable" 30 "Error" 15 "ControlUnitInDiagnosticMode" 9 "FunctionFault" 8 "OperatorControlFault" 5 "RemoteCommandTimeout" 4 "OperatorControlNotInValidPosition" 3 "OperatorOverrideOfFunction" 2 "ImplementReleasedControiOfFunction" 7 "FunctionNotCalibrated" 6 "RemoteCommandOutOfRangeOrInvalid" 1 "RequiredLevelOfOperatorPresence_AwarenessNotDetected" 0 "NoReason_AllClear" ;
VAL_ 2619604717 SpeedExitReasonCode 31 "NotAvailable" 30 "Error" 15 "VehicleTransmissionGearDoesntAllowRemoteCommands " 9 "FunctionFault" 8 "OperatorControlFault" 5 "RemoteCommandTimeout" 4 "OperatorControlNotInValidPosition" 3 "OperatorOverrideOfFunction" 2 "ImplementReleasedControiOfFunction" 7 "FunctionNotCalibrated" 6 "RemoteCommandOutOfRangeOrInvalid" 1 "RequiredLevelOfOperatorPresence_AwarenessNotDetected" 0 "NoReason_AllClear" ;
VAL_ 2619604717 HitchPosition 64256 "Float" ;
VAL_ 2619604717 HitchExitReasonCode 16 "HitchLockedOut" 31 "NotAvailable" 30 "Error" 15 "HydraulicOilLevelLow" 9 "FunctionFault" 8 "OperatorControlFault" 5 "RemoteCommandTimeout" 4 "OperatorControlNotInValidPosition" 3 "OperatorOverrideOfFunction" 2 "ImplementReleasedControiOfFunction" 7 "FunctionNotCalibrated" 6 "RemoteCommandOutOfRangeOrInvalid" 1 "RequiredLevelOfOperatorPresence_AwarenessNotDetected" 0 "NoReason_AllClear" ;
VAL_ 2619604717 PTOExitReasonCode 31 "NotAvailable" 30 "Error" 15 "InvalidPtoGear" 9 "FunctionFault" 8 "OperatorControlFault" 5 "RemoteCommandTimeout" 4 "OperatorControlNotInValidPosition" 3 "OperatorOverrideOfFunction" 2 "ImplementReleasedControlOfFunction" 7 "FunctionNotCalibrated" 6 "RemoteCommandOutOfRange_Invalid" 1 "RequiredLevelOfOperatorPresence_AwarenessNotDetected" 0 "NoReason_AllClear" ;
VAL_ 2619604717 TIMAuxValveFlow 64257 "Float" 64256 "ValveFullyOpened_Retract" 32128 "NoFlow_Block" 0 "ValveFullyOpened_Extend" ;
VAL_ 2619604717 FlowType 3 "NotAvailable" 2 "Error" 1 "Measured" 0 "Estimated" ;
VAL_ 2619604717 ReflectedRequestCounter 15 "NotAvailable_DontCare " 14 "Reserved" ;
VAL_ 2619604717 AuxValveExitReasonCode 31 "NotAvailable" 30 "Error" 16 "ValveLockedOut_TransportLock" 15 "HydraulicOilLevelLow" 9 "FunctionFault" 8 "OperatorControlFault" 5 "RemoteCommandTimeout" 4 "OperatorControlNotInValidPosition" 3 "OperatorOverrideOfFunction" 2 "ImplementReleasedControlOfFunction" 7 "FunctionNotCalibrated" 6 "RemoteCommandOutOfRange_Invalid" 1 "RequiredLevelOfOperatorPresence_AwarenessNotDetected" 0 "NoReason_AllClear" ;
VAL_ 2619604717 AutomationStatus 13 "AutomationFault" 7 "ActiveLimitedLow" 6 "ActiveLimitedHigh" 5 "ActiveNotLimited" 0 "AutomationUnavailable" 1 "AutomationNotReady" 2 "AutomationReadyToEnable" 3 "AutomationEnabled" 4 "AutomationPending" 14 "NonRecoverableFault" 15 "NotAvailable" ;
VAL_ 2619604717 TIMSystemOperationState 15 "NotAvailable" 14 "Error" 3 "RequirementsStationaryFulfilled" 2 "RequirementsStandstillFulfilled" 1 "RequirementsNormalFulfilled" 0 "RequirementsNotFulfilled" ;
VAL_ 2619604717 TIMServerState 13 "AutomationFault" 5 "AutomationActive" 3 "AutomationEnabled" 15 "NotAvailable" 14 "Error" 1 "AutomationNotReady" 0 "AutomationUnavailable" ;
VAL_ 2619604717 TIMSystemState 15 "NotAvailable" 14 "Error" 5 "AutomationActive" 1 "NoAutomationActive" ;
VAL_ 2619604717 TIMServerMasterIndication 15 "NotAvailable" 14 "Error" 1 "IsMasterAndAutomationAllowed" 0 "IsMasterButAutomationNotAllowed" ;
VAL_ 2619604717 ServerHeartbeatCounter 255 "GracefulShutdown" 254 "ErrorConditionOnSender" 251 "ResetOfHeartbeatCounter" ;
VAL_ 2619604717 AssignmentResult_4 7 "NotAvailable" 6 "Error" 5 "AssignmentNotSuccessful" 1 "IsAssigned" 0 "IsNotAssigned" ;
VAL_ 2619604717 AssignmentResult_3 7 "NotAvailable" 6 "Error" 5 "AssignmentNotSuccessful" 1 "IsAssigned" 0 "IsNotAssigned" ;
VAL_ 2619604717 AssignmentResult_2 7 "NotAvailable" 6 "Error" 5 "AssignmentNotSuccessful" 1 "IsAssigned" 0 "IsNotAssigned" ;
VAL_ 2619604717 AssignmentErrorReason_4 31 "NotAvailable" 30 "AnyOtherError" 8 "ClientNotAuthenticated" 7 "NoMatchingFacility" 6 "ServerBusyWithAssignmentRequest" 5 "ClientNotCertifiedForFunction" 4 "ErrorInRequestMessage" 3 "UnknownRequestType" 2 "FunctionCurrentlyNotAvailable" 1 "FunctionNotSupportedByServer" 0 "AllClearNoReason" ;
VAL_ 2619604717 AssignmentErrorReason_3 31 "NotAvailable" 30 "AnyOtherError" 8 "ClientNotAuthenticated" 7 "NoMatchingFacility" 6 "ServerBusyWithAssignmentRequest" 5 "ClientNotCertifiedForFunction" 4 "ErrorInRequestMessage" 3 "UnknownRequestType" 2 "FunctionCurrentlyNotAvailable" 1 "FunctionNotSupportedByServer" 0 "AllClearNoReason" ;
VAL_ 2619604717 AssignmentErrorReason_2 31 "NotAvailable" 30 "AnyOtherError" 8 "ClientNotAuthenticated" 7 "NoMatchingFacility" 6 "ServerBusyWithAssignmentRequest" 5 "ClientNotCertifiedForFunction" 4 "ErrorInRequestMessage" 3 "UnknownRequestType" 2 "FunctionCurrentlyNotAvailable" 1 "FunctionNotSupportedByServer" 0 "AllClearNoReason" ;
VAL_ 2619604717 AssignmentErrorReason_1 31 "NotAvailable" 30 "AnyOtherError" 8 "ClientNotAuthenticated" 7 "NoMatchingFacility" 6 "ServerBusyWithAssignmentRequest" 5 "ClientNotCertifiedForFunction" 4 "ErrorInRequestMessage" 3 "UnknownRequestType" 2 "FunctionCurrentlyNotAvailable" 1 "FunctionNotSupportedByServer" 0 "AllClearNoReason" ;
VAL_ 2619604717 AssignmentResult_1 7 "NotAvailable" 6 "Error" 5 "AssignmentNotSuccessful" 1 "IsAssigned" 0 "IsNotAssigned" ;
VAL_ 2619604717 TIMFunctionId_4 32 "AuxValve32" 70 "ExternalGuidance" 68 "VehicleSpeed" 67 "RearHitch" 66 "FrontHitch" 65 "RearPTO" 64 "FrontPTO" 31 "AuxValve31" 30 "AuxValve30" 29 "AuxValve29" 28 "AuxValve28" 27 "AuxValve27" 26 "AuxValve26" 25 "AuxValve25" 24 "AuxValve24" 23 "AuxValve23" 22 "AuxValve22" 21 "AuxValve21" 20 "AuxValve20" 19 "AuxValve19" 18 "AuxValve18" 17 "AuxValve17" 16 "AuxValve16" 15 "AuxValve15" 14 "AuxValve14" 13 "AuxValve13" 12 "AuxValve12" 11 "AuxValve11" 10 "AuxValve10" 9 "AuxValve9" 8 "AuxValve8" 7 "AuxValve7" 6 "AuxValve6" 5 "AuxValve5" 4 "AuxValve4" 3 "AuxValve3" 2 "AuxValve2" 1 "AuxValve1" ;
VAL_ 2619604717 TIMFunctionId_3 32 "AuxValve32" 70 "ExternalGuidance" 68 "VehicleSpeed" 67 "RearHitch" 66 "FrontHitch" 65 "RearPTO" 64 "FrontPTO" 31 "AuxValve31" 30 "AuxValve30" 29 "AuxValve29" 28 "AuxValve28" 27 "AuxValve27" 26 "AuxValve26" 25 "AuxValve25" 24 "AuxValve24" 23 "AuxValve23" 22 "AuxValve22" 21 "AuxValve21" 20 "AuxValve20" 19 "AuxValve19" 18 "AuxValve18" 17 "AuxValve17" 16 "AuxValve16" 15 "AuxValve15" 14 "AuxValve14" 13 "AuxValve13" 12 "AuxValve12" 11 "AuxValve11" 10 "AuxValve10" 9 "AuxValve9" 8 "AuxValve8" 7 "AuxValve7" 6 "AuxValve6" 5 "AuxValve5" 4 "AuxValve4" 3 "AuxValve3" 2 "AuxValve2" 1 "AuxValve1" ;
VAL_ 2619604717 TIMFunctionId_2 32 "AuxValve32" 70 "ExternalGuidance" 68 "VehicleSpeed" 67 "RearHitch" 66 "FrontHitch" 65 "RearPTO" 64 "FrontPTO" 31 "AuxValve31" 30 "AuxValve30" 29 "AuxValve29" 28 "AuxValve28" 27 "AuxValve27" 26 "AuxValve26" 25 "AuxValve25" 24 "AuxValve24" 23 "AuxValve23" 22 "AuxValve22" 21 "AuxValve21" 20 "AuxValve20" 19 "AuxValve19" 18 "AuxValve18" 17 "AuxValve17" 16 "AuxValve16" 15 "AuxValve15" 14 "AuxValve14" 13 "AuxValve13" 12 "AuxValve12" 11 "AuxValve11" 10 "AuxValve10" 9 "AuxValve9" 8 "AuxValve8" 7 "AuxValve7" 6 "AuxValve6" 5 "AuxValve5" 4 "AuxValve4" 3 "AuxValve3" 2 "AuxValve2" 1 "AuxValve1" ;
VAL_ 2619604717 TIMFunctionId_1 32 "AuxValve32" 70 "ExternalGuidance" 68 "VehicleSpeed" 67 "RearHitch" 66 "FrontHitch" 65 "RearPTO" 64 "FrontPTO" 31 "AuxValve31" 30 "AuxValve30" 29 "AuxValve29" 28 "AuxValve28" 27 "AuxValve27" 26 "AuxValve26" 25 "AuxValve25" 24 "AuxValve24" 23 "AuxValve23" 22 "AuxValve22" 21 "AuxValve21" 20 "AuxValve20" 19 "AuxValve19" 18 "AuxValve18" 17 "AuxValve17" 16 "AuxValve16" 15 "AuxValve15" 14 "AuxValve14" 13 "AuxValve13" 12 "AuxValve12" 11 "AuxValve11" 10 "AuxValve10" 9 "AuxValve9" 8 "AuxValve8" 7 "AuxValve7" 6 "AuxValve6" 5 "AuxValve5" 4 "AuxValve4" 3 "AuxValve3" 2 "AuxValve2" 1 "AuxValve1" ;
VAL_ 2619604717 TIMConnectionVersion 255 "IncompatibleTIMServerAndClientVersions" ;
VAL_ 2619604717 ErrorCode 1 "IncompatibleTIMServerAndClientVersions" 0 "NoError" ;
VAL_ 2619604717 TIMMessageType 1 "TIMFunctionStatus" 0 "TIMFunctionRequest" ;
VAL_ 2619604717 GroupFunctionValue 32 "TIM_AuxValve32Status" 243 "FunctionsAssignmentStatusResponse" 250 "ServerStatus" 248 "ServerVersionResponse" 247 "ClientVersionRequest" 246 "ConnectionVersionResponse" 245 "FunctionsAssignmentResponse" 244 "FunctionsSupportResponse" 70 "ExternalGuidanceStatus" 68 "VehicleSpeedStatus" 67 "RearHitchStatus" 66 "FrontHitchStatus" 65 "RearPTOStatus" 64 "FrontPTOStatus" 31 "TIM_AuxValve31Status" 30 "TIM_AuxValve30Status" 29 "TIM_AuxValve29Status" 28 "TIM_AuxValve28Status" 27 "TIM_AuxValve27Status" 26 "TIM_AuxValve26Status" 25 "TIM_AuxValve25Status" 24 "TIM_AuxValve24Status" 23 "TIM_AuxValve23Status" 22 "TIM_AuxValve22Status" 21 "TIM_AuxValve21Status" 20 "TIM_AuxValve20Status" 19 "TIM_AuxValve19Status" 18 "TIM_AuxValve18Status" 17 "TIM_AuxValve17Status" 16 "TIM_AuxValve16Status" 15 "TIM_AuxValve15Status" 14 "TIM_AuxValve14Status" 13 "TIM_AuxValve13Status" 12 "TIM_AuxValve12Status" 11 "TIM_AuxValve11Status" 10 "TIM_AuxValve10Status" 9 "TIM_AuxValve9Status" 8 "TIM_AuxValve8Status" 7 "TIM_AuxValve7Status" 6 "TIM_AuxValve6Status" 5 "TIM_AuxValve5Status" 4 "TIM_AuxValve4Status" 3 "TIM_AuxValve3Status" 2 "TIM_AuxValve2Status" 1 "TIM_AuxValve1Status" ;
VAL_ 2566734573 CertLaboratoryType_FirstDef 7 "Not available (not certified) " 0 "Non-certified laboratory/self-test" 1 "AEF certified laboratory " 2 "Reserved " ;
VAL_ 2566734573 MessageRevision 1 "Third and later edition message revision" 0 "Format of message in second edition." ;
VAL_ 2566734573 CertificationReferenceNumber 0 "NotCertified" 1 "CertificationTestPerformed" ;
VAL_ 2566734573 CertTypeTaskController 0 "NotCertified" 1 "CertificationTestPerformed" ;
VAL_ 2566734573 CertTypeTCWorkingSetMaster 0 "NotCertified" 1 "CertificationTestPerformed" ;
VAL_ 2566734573 CertTypeTCWorkingSetMember 0 "NotCertified" 1 "CertificationTestPerformed" ;
VAL_ 2566734573 CertTypeFileServer 0 "NotCertified" 1 "CertificationTestPerformed" ;
VAL_ 2566734573 CertTypeGPSReceiver 0 "NotCertified" 1 "CertificationTestPerformed" ;
VAL_ 2566734573 CertTypeMinimumECU 0 "NotCertified" 1 "CertificationTestPerformed" ;
VAL_ 2566734573 CertTypeTECUClass1 0 "NotCertified" 1 "CertificationTestPerformed" ;
VAL_ 2566734573 CertTypeTECUClass2 0 "NotCertified" 1 "CertificationTestPerformed" ;
VAL_ 2566734573 CertTypeTECUClass3 0 "NotCertified" 1 "CertificationTestPerformed" ;
VAL_ 2566734573 CertTypeClass3ECU 0 "NotCertified" 1 "CertificationTestPerformed" ;
VAL_ 2566734573 CertTypeVirtualTerminal 0 "NotCertified" 1 "CertificationTestPerformed" ;
VAL_ 2566734573 CertTypeVTWorkingSetMaster 0 "NotCertified" 1 "CertificationTestPerformed" ;
VAL_ 2566734573 CertTypeVTWorkingSetMember 0 "NotCertified" 1 "CertificationTestPerformed" ;
VAL_ 2566734573 CertLaboratoryType_SecondDef 3 "Not available (not certified) " 0 "Non-certified Laboratory/self-certification" 1 "AEF certified laboratory " 2 "Reserved " ;
VAL_ 2566734573 TestProtocolRevision 0 "FirstRevision" 1 "SecondRevision" 2 "ThirdRevision" 3 "NotAvailable" ;
VAL_ 2566734339 CertLaboratoryType_FirstDef 7 "Not available (not certified) " 0 "Non-certified laboratory/self-test" 1 "AEF certified laboratory " 2 "Reserved " ;
VAL_ 2566734339 MessageRevision 1 "Third and later edition message revision" 0 "Format of message in second edition." ;
VAL_ 2566734339 CertificationReferenceNumber 0 "NotCertified" 1 "CertificationTestPerformed" ;
VAL_ 2566734339 CertTypeTaskController 0 "NotCertified" 1 "CertificationTestPerformed" ;
VAL_ 2566734339 CertTypeTCWorkingSetMaster 0 "NotCertified" 1 "CertificationTestPerformed" ;
VAL_ 2566734339 CertTypeTCWorkingSetMember 0 "NotCertified" 1 "CertificationTestPerformed" ;
VAL_ 2566734339 CertTypeFileServer 0 "NotCertified" 1 "CertificationTestPerformed" ;
VAL_ 2566734339 CertTypeGPSReceiver 0 "NotCertified" 1 "CertificationTestPerformed" ;
VAL_ 2566734339 CertTypeMinimumECU 0 "NotCertified" 1 "CertificationTestPerformed" ;
VAL_ 2566734339 CertTypeTECUClass1 0 "NotCertified" 1 "CertificationTestPerformed" ;
VAL_ 2566734339 CertTypeTECUClass2 0 "NotCertified" 1 "CertificationTestPerformed" ;
VAL_ 2566734339 CertTypeTECUClass3 0 "NotCertified" 1 "CertificationTestPerformed" ;
VAL_ 2566734339 CertTypeClass3ECU 0 "NotCertified" 1 "CertificationTestPerformed" ;
VAL_ 2566734339 CertTypeVirtualTerminal 0 "NotCertified" 1 "CertificationTestPerformed" ;
VAL_ 2566734339 CertTypeVTWorkingSetMaster 0 "NotCertified" 1 "CertificationTestPerformed" ;
VAL_ 2566734339 CertTypeVTWorkingSetMember 0 "NotCertified" 1 "CertificationTestPerformed" ;
VAL_ 2566734339 CertLaboratoryType_SecondDef 3 "Not available (not certified) " 0 "Non-certified Laboratory/self-certification" 1 "AEF certified laboratory " 2 "Reserved " ;
VAL_ 2566734339 TestProtocolRevision 0 "FirstRevision" 1 "SecondRevision" 2 "ThirdRevision" 3 "NotAvailable" ;
VAL_ 2566734338 CertLaboratoryType_FirstDef 7 "Not available (not certified) " 0 "Non-certified laboratory/self-test" 1 "AEF certified laboratory " 2 "Reserved " ;
VAL_ 2566734338 MessageRevision 1 "Third and later edition message revision" 0 "Format of message in second edition." ;
VAL_ 2566734338 CertificationReferenceNumber 0 "NotCertified" 1 "CertificationTestPerformed" ;
VAL_ 2566734338 CertTypeTaskController 0 "NotCertified" 1 "CertificationTestPerformed" ;
VAL_ 2566734338 CertTypeTCWorkingSetMaster 0 "NotCertified" 1 "CertificationTestPerformed" ;
VAL_ 2566734338 CertTypeTCWorkingSetMember 0 "NotCertified" 1 "CertificationTestPerformed" ;
VAL_ 2566734338 CertTypeFileServer 0 "NotCertified" 1 "CertificationTestPerformed" ;
VAL_ 2566734338 CertTypeGPSReceiver 0 "NotCertified" 1 "CertificationTestPerformed" ;
VAL_ 2566734338 CertTypeMinimumECU 0 "NotCertified" 1 "CertificationTestPerformed" ;
VAL_ 2566734338 CertTypeTECUClass1 0 "NotCertified" 1 "CertificationTestPerformed" ;
VAL_ 2566734338 CertTypeTECUClass2 0 "NotCertified" 1 "CertificationTestPerformed" ;
VAL_ 2566734338 CertTypeTECUClass3 0 "NotCertified" 1 "CertificationTestPerformed" ;
VAL_ 2566734338 CertTypeClass3ECU 0 "NotCertified" 1 "CertificationTestPerformed" ;
VAL_ 2566734338 CertTypeVirtualTerminal 0 "NotCertified" 1 "CertificationTestPerformed" ;
VAL_ 2566734338 CertTypeVTWorkingSetMaster 0 "NotCertified" 1 "CertificationTestPerformed" ;
VAL_ 2566734338 CertTypeVTWorkingSetMember 0 "NotCertified" 1 "CertificationTestPerformed" ;
VAL_ 2566734338 CertLaboratoryType_SecondDef 3 "Not available (not certified) " 0 "Non-certified Laboratory/self-certification" 1 "AEF certified laboratory " 2 "Reserved " ;
VAL_ 2566734338 TestProtocolRevision 0 "FirstRevision" 1 "SecondRevision" 2 "ThirdRevision" 3 "NotAvailable" ;
VAL_ 2566734337 CertLaboratoryType_FirstDef 7 "Not available (not certified) " 0 "Non-certified laboratory/self-test" 1 "AEF certified laboratory " 2 "Reserved " ;
VAL_ 2566734337 MessageRevision 1 "Third and later edition message revision" 0 "Format of message in second edition." ;
VAL_ 2566734337 CertificationReferenceNumber 0 "NotCertified" 1 "CertificationTestPerformed" ;
VAL_ 2566734337 CertTypeTaskController 0 "NotCertified" 1 "CertificationTestPerformed" ;
VAL_ 2566734337 CertTypeTCWorkingSetMaster 0 "NotCertified" 1 "CertificationTestPerformed" ;
VAL_ 2566734337 CertTypeTCWorkingSetMember 0 "NotCertified" 1 "CertificationTestPerformed" ;
VAL_ 2566734337 CertTypeFileServer 0 "NotCertified" 1 "CertificationTestPerformed" ;
VAL_ 2566734337 CertTypeGPSReceiver 0 "NotCertified" 1 "CertificationTestPerformed" ;
VAL_ 2566734337 CertTypeMinimumECU 0 "NotCertified" 1 "CertificationTestPerformed" ;
VAL_ 2566734337 CertTypeTECUClass1 0 "NotCertified" 1 "CertificationTestPerformed" ;
VAL_ 2566734337 CertTypeTECUClass2 0 "NotCertified" 1 "CertificationTestPerformed" ;
VAL_ 2566734337 CertTypeTECUClass3 0 "NotCertified" 1 "CertificationTestPerformed" ;
VAL_ 2566734337 CertTypeClass3ECU 0 "NotCertified" 1 "CertificationTestPerformed" ;
VAL_ 2566734337 CertTypeVirtualTerminal 0 "NotCertified" 1 "CertificationTestPerformed" ;
VAL_ 2566734337 CertTypeVTWorkingSetMaster 0 "NotCertified" 1 "CertificationTestPerformed" ;
VAL_ 2566734337 CertTypeVTWorkingSetMember 0 "NotCertified" 1 "CertificationTestPerformed" ;
VAL_ 2566734337 CertLaboratoryType_SecondDef 3 "Not available (not certified) " 0 "Non-certified Laboratory/self-certification" 1 "AEF certified laboratory " 2 "Reserved " ;
VAL_ 2566734337 TestProtocolRevision 0 "FirstRevision" 1 "SecondRevision" 2 "ThirdRevision" 3 "NotAvailable" ;
VAL_ 2624650989 AuthenticationStatus 15 "NotAvailable" 14 "Error" 1 "Authenticated" 0 "NotAuthenticated" ;
VAL_ 2624650989 ChallengeSigned 1 "SetOrTrue" 0 "UnsetOrFalse" ;
VAL_ 2624650989 DeviceCertIsValid 1 "SetOrTrue" 0 "UnsetOrFalse" ;
VAL_ 2624650989 ManufactSeriesCertIsValid 1 "SetOrTrue" 0 "UnsetOrFalse" ;
VAL_ 2624650989 ManufactCertIsValid 1 "SetOrTrue" 0 "UnsetOrFalse" ;
VAL_ 2624650989 TestlabCertIsValid 1 "SetOrTrue" 0 "UnsetOrFalse" ;
VAL_ 2624650989 LwAPossible 1 "SetOrTrue" 0 "UnsetOrFalse" ;
VAL_ 2624650989 ReStartAuth 1 "SetOrTrue" 0 "UnsetOrFalse" ;
VAL_ 2624650989 CertType 255 "NotAvailable" 6 "CRLCertificate" 5 "CRLSigningCertificate" 4 "DeviceCertificate" 3 "ManufacturereSeriesCertificate" 2 "ManufacturerCertificate" 1 "TestlabCertificate" 0 "AEFRootCertificate" ;
VAL_ 2624650989 CertificateFormat 255 "NotAvailable" 0 "DER_BinaryInASN1" ;
VAL_ 2624650989 AuthenticationType 15 "NotAvailable" 14 "Error" 0 "TIM_Authentication" ;
VAL_ 2624650989 MessageCode 9 "ClientAuthenticationInfoRequest" 8 "ServerAuthenticationInfoResponse" 249 "ServerAuthenticationStatus" 7 "ClientSignedChallengeRequest" 6 "ServerSignedChallengeResponse" 5 "ClientRandomChallengeRequest" 4 "ServerRandomChallengeResponse" 3 "ClientCertificateRequest" 2 "ServerCertificateResponse" ;
VAL_ 2624650989 ErrorCode 39 "LwAPossibleBitMismatch" 38 "AuthenticationAbortedDueToGeneralPeerError" 37 "AuthenticationAbortedByPeerDueToError" 36 "ChallengeDataCorrupt" 35 "InvalidChallengeLength" 34 "FunctionFacilityNotCertified" 33 "RequestNotAllowed" 32 "Reserved_0x20" 31 "AuthenticationTimeout" 30 "CertificateTypeInvalid" 29 "DeviceCertificateRevoked" 28 "ManufacturerSeriesCertificateRevoked" 27 "ManufacturerCertificateRevoked" 26 "LabCertificateRevoked" 25 "RootCertificateRevoked" 24 "CertificateTypeMismatch" 23 "CertificateChainInvalid" 22 "ECU_CCID_Mismatch" 21 "NAME_Mismatch" 20 "ECC_PublicKeyValidationFailed" 19 "UnexpectedRestartAuthenticationBitSet" 18 "AuthenticationStatusInvalid" 17 "AuthenticationTypeNotSupported" 16 "AuthenticationStatusLost" 15 "DeviceCertificateDataCorrupt" 14 "ManufacturerSeriesCertificateDataCorrupt" 13 "ManufacturerCertificateDataCorrupt" 12 "TestLabCertificateDataCorrupt" 11 "RootCertificateDataCorrupt" 10 "InternalError" 9 "ChallengesDontMatch" 8 "DeviceCertificateSignatureInvalid" 7 "ManufacturerSeriesCertificateSignatureInvalid" 6 "ManufacturerCertificateSignatureInvalid" 5 "LabCertificateSignatureInvalid" 4 "RootCertificateSignatureInvalid" 3 "NotAuthenticationServerOrClient" 2 "CertificateFormatNotSupported" 1 "ParticipantBusy" 0 "NoError" ;
VAL_ 2624585219 LwAPossible 1 "SetOrTrue" 0 "UnsetOrFalse" ;
VAL_ 2624585219 TestlabCertIsValid 1 "SetOrTrue" 0 "UnsetOrFalse" ;
VAL_ 2624585219 ReStartAuth 1 "SetOrTrue" 0 "UnsetOrFalse" ;
VAL_ 2624585219 ManufactSeriesCertIsValid 1 "SetOrTrue" 0 "UnsetOrFalse" ;
VAL_ 2624585219 ManufactCertIsValid 1 "SetOrTrue" 0 "UnsetOrFalse" ;
VAL_ 2624585219 DeviceCertIsValid 1 "SetOrTrue" 0 "UnsetOrFalse" ;
VAL_ 2624585219 ChallengeSigned 1 "SetOrTrue" 0 "UnsetOrFalse" ;
VAL_ 2624585219 AuthenticationStatus 15 "NotAvailable" 14 "Error" 1 "Authenticated" 0 "NotAuthenticated" ;
VAL_ 2624585219 ErrorCode 39 "LwAPossibleBitMismatch" 38 "AuthenticationAbortedDueToGeneralPeerError" 37 "AuthenticationAbortedByPeerDueToError" 36 "ChallengeDataCorrupt" 35 "InvalidChallengeLength" 34 "FunctionFacilityNotCertified" 33 "RequestNotAllowed" 32 "Reserved_0x20" 31 "AuthenticationTimeout" 30 "CertificateTypeInvalid" 29 "DeviceCertificateRevoked" 28 "ManufacturerSeriesCertificateRevoked" 27 "ManufacturerCertificateRevoked" 26 "LabCertificateRevoked" 25 "RootCertificateRevoked" 24 "CertificateTypeMismatch" 23 "CertificateChainInvalid" 22 "ECU_CCID_Mismatch" 21 "NAME_Mismatch" 20 "ECC_PublicKeyValidationFailed" 19 "UnexpectedRestartAuthenticationBitSet" 18 "AuthenticationStatusInvalid" 17 "AuthenticationTypeNotSupported" 16 "AuthenticationStatusLost" 15 "DeviceCertificateDataCorrupt" 14 "ManufacturerSeriesCertificateDataCorrupt" 13 "ManufacturerCertificateDataCorrupt" 12 "TestLabCertificateDataCorrupt" 11 "RootCertificateDataCorrupt" 10 "InternalError" 9 "ChallengesDontMatch" 8 "DeviceCertificateSignatureInvalid" 7 "ManufacturerSeriesCertificateSignatureInvalid" 6 "ManufacturerCertificateSignatureInvalid" 5 "LabCertificateSignatureInvalid" 4 "RootCertificateSignatureInvalid" 3 "NotAuthenticationServerOrClient" 2 "CertificateFormatNotSupported" 1 "ParticipantBusy" 0 "NoError" ;
VAL_ 2624585219 CertType 255 "NotAvailable" 6 "CRLCertificate" 5 "CRLSigningCertificate" 4 "DeviceCertificate" 3 "ManufacturereSeriesCertificate" 2 "ManufacturerCertificate" 1 "TestlabCertificate" 0 "AEFRootCertificate" ;
VAL_ 2624585219 CertificateFormat 255 "NotAvailable" 0 "DER_BinaryInASN_1" ;
VAL_ 2624585219 AuthenticationType 15 "NotAvailable" 14 "Error" 0 "TIM_Authentication" ;
VAL_ 2624585219 MessageCode 9 "ClientAuthenticationInfoResponse" 8 "ServerAuthenticationInfoRequest" 250 "ClientAuthenticationStatus" 7 "ClientSignedChallengeResponse" 6 "ServerSignedChallengeRequest" 5 "ClientRandomChallengeResponse" 4 "ServerRandomChallengeRequest" 3 "ClientCertificateResponse" 2 "ServerCertificateRequest" ;
VAL_ 2624585218 LwAPossible 1 "SetOrTrue" 0 "UnsetOrFalse" ;
VAL_ 2624585218 TestlabCertIsValid 1 "SetOrTrue" 0 "UnsetOrFalse" ;
VAL_ 2624585218 ReStartAuth 1 "SetOrTrue" 0 "UnsetOrFalse" ;
VAL_ 2624585218 ManufactSeriesCertIsValid 1 "SetOrTrue" 0 "UnsetOrFalse" ;
VAL_ 2624585218 ManufactCertIsValid 1 "SetOrTrue" 0 "UnsetOrFalse" ;
VAL_ 2624585218 DeviceCertIsValid 1 "SetOrTrue" 0 "UnsetOrFalse" ;
VAL_ 2624585218 ChallengeSigned 1 "SetOrTrue" 0 "UnsetOrFalse" ;
VAL_ 2624585218 AuthenticationStatus 15 "NotAvailable" 14 "Error" 1 "Authenticated" 0 "NotAuthenticated" ;
VAL_ 2624585218 ErrorCode 39 "LwAPossibleBitMismatch" 38 "AuthenticationAbortedDueToGeneralPeerError" 37 "AuthenticationAbortedByPeerDueToError" 36 "ChallengeDataCorrupt" 35 "InvalidChallengeLength" 34 "FunctionFacilityNotCertified" 33 "RequestNotAllowed" 32 "Reserved_0x20" 31 "AuthenticationTimeout" 30 "CertificateTypeInvalid" 29 "DeviceCertificateRevoked" 28 "ManufacturerSeriesCertificateRevoked" 27 "ManufacturerCertificateRevoked" 26 "LabCertificateRevoked" 25 "RootCertificateRevoked" 24 "CertificateTypeMismatch" 23 "CertificateChainInvalid" 22 "ECU_CCID_Mismatch" 21 "NAME_Mismatch" 20 "ECC_PublicKeyValidationFailed" 19 "UnexpectedRestartAuthenticationBitSet" 18 "AuthenticationStatusInvalid" 17 "AuthenticationTypeNotSupported" 16 "AuthenticationStatusLost" 15 "DeviceCertificateDataCorrupt" 14 "ManufacturerSeriesCertificateDataCorrupt" 13 "ManufacturerCertificateDataCorrupt" 12 "TestLabCertificateDataCorrupt" 11 "RootCertificateDataCorrupt" 10 "InternalError" 9 "ChallengesDontMatch" 8 "DeviceCertificateSignatureInvalid" 7 "ManufacturerSeriesCertificateSignatureInvalid" 6 "ManufacturerCertificateSignatureInvalid" 5 "LabCertificateSignatureInvalid" 4 "RootCertificateSignatureInvalid" 3 "NotAuthenticationServerOrClient" 2 "CertificateFormatNotSupported" 1 "ParticipantBusy" 0 "NoError" ;
VAL_ 2624585218 CertType 255 "NotAvailable" 6 "CRLCertificate" 5 "CRLSigningCertificate" 4 "DeviceCertificate" 3 "ManufacturereSeriesCertificate" 2 "ManufacturerCertificate" 1 "TestlabCertificate" 0 "AEFRootCertificate" ;
VAL_ 2624585218 CertificateFormat 255 "NotAvailable" 0 "DER_BinaryInASN_1" ;
VAL_ 2624585218 AuthenticationType 15 "NotAvailable" 14 "Error" 0 "TIM_Authentication" ;
VAL_ 2624585218 MessageCode 9 "ClientAuthenticationInfoResponse" 8 "ServerAuthenticationInfoRequest" 250 "ClientAuthenticationStatus" 7 "ClientSignedChallengeResponse" 6 "ServerSignedChallengeRequest" 5 "ClientRandomChallengeResponse" 4 "ServerRandomChallengeRequest" 3 "ClientCertificateResponse" 2 "ServerCertificateRequest" ;
VAL_ 2624585217 LwAPossible 1 "SetOrTrue" 0 "UnsetOrFalse" ;
VAL_ 2624585217 TestlabCertIsValid 1 "SetOrTrue" 0 "UnsetOrFalse" ;
VAL_ 2624585217 ReStartAuth 1 "SetOrTrue" 0 "UnsetOrFalse" ;
VAL_ 2624585217 ManufactSeriesCertIsValid 1 "SetOrTrue" 0 "UnsetOrFalse" ;
VAL_ 2624585217 ManufactCertIsValid 1 "SetOrTrue" 0 "UnsetOrFalse" ;
VAL_ 2624585217 DeviceCertIsValid 1 "SetOrTrue" 0 "UnsetOrFalse" ;
VAL_ 2624585217 ChallengeSigned 1 "SetOrTrue" 0 "UnsetOrFalse" ;
VAL_ 2624585217 AuthenticationStatus 15 "NotAvailable" 14 "Error" 1 "Authenticated" 0 "NotAuthenticated" ;
VAL_ 2624585217 ErrorCode 39 "LwAPossibleBitMismatch" 38 "AuthenticationAbortedDueToGeneralPeerError" 37 "AuthenticationAbortedByPeerDueToError" 36 "ChallengeDataCorrupt" 35 "InvalidChallengeLength" 34 "FunctionFacilityNotCertified" 33 "RequestNotAllowed" 32 "Reserved_0x20" 31 "AuthenticationTimeout" 30 "CertificateTypeInvalid" 29 "DeviceCertificateRevoked" 28 "ManufacturerSeriesCertificateRevoked" 27 "ManufacturerCertificateRevoked" 26 "LabCertificateRevoked" 25 "RootCertificateRevoked" 24 "CertificateTypeMismatch" 23 "CertificateChainInvalid" 22 "ECU_CCID_Mismatch" 21 "NAME_Mismatch" 20 "ECC_PublicKeyValidationFailed" 19 "UnexpectedRestartAuthenticationBitSet" 18 "AuthenticationStatusInvalid" 17 "AuthenticationTypeNotSupported" 16 "AuthenticationStatusLost" 15 "DeviceCertificateDataCorrupt" 14 "ManufacturerSeriesCertificateDataCorrupt" 13 "ManufacturerCertificateDataCorrupt" 12 "TestLabCertificateDataCorrupt" 11 "RootCertificateDataCorrupt" 10 "InternalError" 9 "ChallengesDontMatch" 8 "DeviceCertificateSignatureInvalid" 7 "ManufacturerSeriesCertificateSignatureInvalid" 6 "ManufacturerCertificateSignatureInvalid" 5 "LabCertificateSignatureInvalid" 4 "RootCertificateSignatureInvalid" 3 "NotAuthenticationServerOrClient" 2 "CertificateFormatNotSupported" 1 "ParticipantBusy" 0 "NoError" ;
VAL_ 2624585217 CertType 255 "NotAvailable" 6 "CRLCertificate" 5 "CRLSigningCertificate" 4 "DeviceCertificate" 3 "ManufacturereSeriesCertificate" 2 "ManufacturerCertificate" 1 "TestlabCertificate" 0 "AEFRootCertificate" ;
VAL_ 2624585217 CertificateFormat 255 "NotAvailable" 0 "DER_BinaryInASN_1" ;
VAL_ 2624585217 AuthenticationType 15 "NotAvailable" 14 "Error" 0 "TIM_Authentication" ;
VAL_ 2624585217 MessageCode 9 "ClientAuthenticationInfoResponse" 8 "ServerAuthenticationInfoRequest" 250 "ClientAuthenticationStatus" 7 "ClientSignedChallengeResponse" 6 "ServerSignedChallengeRequest" 5 "ClientRandomChallengeResponse" 4 "ServerRandomChallengeRequest" 3 "ClientCertificateResponse" 2 "ServerCertificateRequest" ;
VAL_ 2565799661 IndustryGroup 7 "Reserved for SAE" 5 "IndustrialProcessCtrlStationary" 4 "Marine" 3 "Construction" 2 "Agricultural and Forestry" 1 "On-Highway" 0 "Global" ;
VAL_ 2565799661 VehicleSystem 127 "Not Available" 0 "Non-specific System" ;
VAL_ 2565799661 VehicleSystem5 0 "Ind. Process Control Stationary" 127 "Not Available" ;
VAL_ 2565799661 VehicleSystem4 0 "Non-specific System" 127 "Not Available" 10 "System Tools" 20 "Safety Systems" 25 "Inter/Intranetwork Device" 30 "Electrical Distribution" 40 "Steering and Control Surfaces" 50 "Propulsion" 60 "Navigation" 70 "Communications" 80 "Instrumentation/General Systems (deprecate)" 90 "Internal Environment" 100 "Deck, Cargo and Fishing Equipment" 35 "Electrical Generation" 75 "Sensor Communication Interface" 85 "External Environment" 120 "Display" 125 "Entertainment" ;
VAL_ 2565799661 VehicleSystem3 0 "Non-specific System" 127 "Not Available" 1 "Skid Steer Loader" 2 "Articulated Dump Truck" 3 "Backhoe" 4 "Crawler" 5 "Excavator" 6 "Forklift" 7 "Four Wheel Drive Loader" 8 "Grader" ;
VAL_ 2565799661 VehicleSystem2 0 "Non-specific System" 127 "Not Available" 1 "Tractor" 2 "Tillage" 3 "Secondary Tillage" 4 "Planters/Seeders" 5 "Fertilizers" 6 "Sprayers" 7 "Harvesters" 8 "Root Harvesters" 9 "Forage" 10 "Irrigation" 11 "Transport/Trailer" 12 "Farm Yard Operations" 13 "Powered Auxiliary Device" 14 "Special Crops" 15 "Earth Work" 16 "Skidder" 17 "Sensor Systems" 19 "Timber Harvesters" 20 "Forwarders" 21 "Timber loaders" 22 "Timber Processing Machines" 23 "Mulchers" 24 "Utility Vehicles" 25 "Slurry Applicators" ;
VAL_ 2565799661 VehicleSystem1 0 "Non-specific System" 127 "Not Available" 1 "Tractor" 2 "Trailer" ;
VAL_ 2565799661 Function 43 "Transmission Display" 44 "Exhaust Emission Control" 45 "Vehicle Dynamic Stability Control" 46 "Oil Sensor Unit" 47 "Information System Controller" 48 "Ramp Control" 49 "Clutch/Converter Control" 50 "Auxiliary Heater" 51 "Forward-Looking Collision Warning System" 52 "Chassis Controller" 53 "Alternator/Charging System" 54 "Communications Unit, Cellular" 55 "Communications Unit, Satellite" 56 "Communications Unit, Radio" 57 "Steering Column Unit" 58 "Fan Drive Control" 59 "Starter" 60 "Cab Display" 61 "File Server/Printer" 62 "On-Board Diagnostic Unit" 63 "Engine Valve Controller" 64 "Endurance Braking" 65 "Gas Flow Measurement" 66 "I/O Controller" 67 "Electrical System Controller" 68 "Aftertreatment system gas measurement" 69 "Engine Emission Aftertreatement System" 70 "Auxiliary Regeneration Device" 71 "Transfer Case Control" 72 "Coolant Valve Controller" 73 "Rollover Detection Control" 74 "Lubrication System" 75 "Supplemental Fan" 76 "Temperature Sensor" 77 "Fuel Properties Sensor" 78 "Fire Suppression System" 79 "Power Systems Manager" 80 "Electric Powertrain" 81 "Hydraulic Powertrain" 82 "File Server" 83 "Printer" 84 "Start Aid Device" 85 "Engine Injection Control Module" 86 "Reserved" 87 "Reserved" 88 "Reserved" 89 "Reserved" 90 "Reserved" 91 "Reserved" 92 "Reserved" 93 "Reserved" 94 "Reserved" 95 "Reserved" 96 "Reserved" 97 "Reserved" 98 "Reserved" 99 "Reserved" 100 "Reserved" 0 "Engine" 1 "Auxiliary Power Unit (APU)" 2 "Electric Propulsion Control" 3 "Transmission" 4 "Battery Pack Monitor" 5 "Shift Control/Console" 6 "Power TakeOff - (Main or Rear)" 7 "Axle - Steering" 8 "Axle - Drive" 9 "Brakes - System Controller" 10 "Brakes - Steer Axle" 11 "Brakes - Drive Axle" 12 "Retarder - Engine" 13 "Retarder - Driveline" 14 "Cruise Control" 15 "Fuel System" 16 "Steering Controller" 17 "Suspension - Steer Axle" 18 "Suspension - Drive Axle" 19 "Instrument Cluster" 20 "Trip Recorder" 21 "Cab Climate Control" 22 "Aerodynamic Control" 23 "Vehicle Navigation" 24 "Vehicle Security" 25 "Network Interconnect ECU" 26 "Body Controller" 27 "Power TakeOff (Secondary or Front)" 28 "Off Vehicle Gateway" 29 "Virtual Terminal (in cab)" 30 "Management Computer" 31 "Propulsion Battery Charger" 32 "Headway Controller" 33 "System Monitor" 34 "Hydraulic Pump Controller" 35 "Suspension - System Controller" 36 "Pneumatic - System Controller" 37 "Cab Controller" 38 "Tire Pressure Control" 39 "Ignition Control Module" 40 "Seat Control" 41 "Lighting - Operator Controls" 42 "Water Pump Control" 101 "Reserved" 102 "Reserved" 103 "Reserved" 104 "Reserved" 105 "Reserved" 106 "Reserved" 107 "Reserved" 108 "Reserved" 109 "Reserved" 110 "Reserved" 111 "Reserved" 112 "Reserved" 113 "Reserved" 114 "Reserved" 115 "Reserved" 116 "Reserved" 117 "Reserved" 118 "Reserved" 119 "Reserved" 120 "Reserved" 121 "Reserved" 122 "Reserved" 123 "Reserved" 124 "Reserved" 125 "Reserved" 126 "Reserved" 127 "Reserved" 255 "Not Available" ;
VAL_ 2565799661 ManufacturerCode 1863 "Thomas G. Faria Co." 1862 "Sanshin" 1861 "Vector North America " 1860 "MMP" 1859 "Kvasar AB" 1858 "Litton" 1857 "Simrad" 1856 "Trimble" 1855 "Furuno USA" 1854 "Northstar Technologies" 1853 "Japan Radio Co" 1852 "Navionics" 1851 "RayMarine" 1850 "Teleflex" 786 "Johnson Matthey Battery Systems" 785 "Fischer Panda GmbH" 784 "CM Automotive Systems, Inc." 783 "Loup Electronics Inc." 782 "AVR bvba" 781 "Poly-Planar LLC" 780 "AVID Technology Ltd" 779 "RLC Electronic Systems" 778 "Seakeeper Inc." 777 "Ocean Signal Ltd" 776 "HMI Systems LLC" 775 "ZIEHL-ABEGG Automotive GmbH" 774 "Taisho Corporation" 773 "Clarion Corporation of America" 772 "Blink Marine" 771 "Shaw Development, LLC" 770 "MONOSEM" 769 "Trombetta" 768 "Flores Automation, LLC" 767 "Alliance Wireless Technologies Inc." 766 "Epec Oy" 765 "GIGAVAC" 764 "Bednar FMT s.r.o." 763 "AT-Systems BVBA" 762 "ROJ s.r.l." 761 "MITA OLEODINAMICA S.p.A." 760 "Bernecker + Rainer Industrie Elektronik GmbH" 759 "Hydro-Gear" 758 "Banner Engineering Corp." 757 "IMPCO Technologies" 756 "Maschio Gaspardo S.P.A." 755 "Firefly Integrations" 754 "Parker Hannifin Corp., Automation Group" 753 "AIROD Technologies" 752 "Deep Sea Electronics Plc" 751 "Pacific Track" 750 "Joskin SA" 749 "Chart Inc." 748 "ISOTTA" 747 "Agratronix" 746 "SureFire Ag Systems, Inc." 745 "Cidra Corporate Services Inc." 744 "Woosung Engineering Co., Ltd." 743 "Daemyung Elevator Co., Ltd." 742 "EROAD" 741 "Carling Technologies" 740 "e-Traction" 739 "LXNAV d.o.o." 738 "Blue Ink Technologies" 737 "Balluff GmbH" 736 "Terex Aerial Work Platforms - Genie" 735 "AEM Performance Electronics" 734 "REAPsystems" 733 "Intendia S.L." 732 "Gefran S.p.A." 731 "Modine Manufacturing Company" 730 "BERTHOUD AGRICOLE" 729 "Liebherr" 728 "Streumaster / Panien" 727 "Dhoot Transmission Pvt Ltd." 726 "MIDORI PRECISIONS" 725 "Hitachi Construction Machinery Co., Ltd." 724 "Electronic Applications, Inc." 723 "Jabil Inc." 722 "Contelec AG" 721 "Hypro" 720 "WITZ Corporation" 719 "Cojali S. L." 718 "Micronet Inc" 717 "Yacht Devices Ltd" 716 "Eaton Control & Power Conversion Division (CPCD)" 715 "Autonnic Research Ltd" 714 "Kobashi Kogyo Co., Ltd." 713 "US Hybrid Corporation" 712 "LOR Manufacturing Company Inc." 711 "DAS Co., LTD" 710 "Greentronics Ltd." 709 "Marquardt GmbH" 708 "Lars Thrane A/S" 707 "Rochester Gauges Inc" 706 "Shanghai Diesel Engine Corporation Limited" 705 "SVAB Hydraulik AB" 704 "JL Audio, Inc." 703 "Hydro Tab Marine Engineering" 702 "Weichai Power Co., Ltd." 701 "BigRoad Inc." 700 "K-Tec Earthmovers Inc." 699 "Harman International Industries" 698 "Scorpion Technologies Ltd." 697 "Ålö AB" 696 "DRS Network & Imaging Systems, LLC (DRS Technologies)" 695 "Weldon Technologies" 694 "GasTOPS Ltd." 693 "Agility Fuel Solutions (formerly Agility Fuel Systems)" 692 "Tanhay Corporation" 691 "Digitroll Agricultural Electronics" 690 "LINAK A/S" 689 "Aarcomm Systems Inc" 688 "Rockford Corp" 687 "Flight Systems, Inc." 686 "Taigene Electric Machinery Corp." 685 "ANEDO Ltd." 684 "KEB" 683 "Fosen Elektro" 682 "Eckelmann AG" 681 "BEDIA Motorentechnik GmbH & Co. KG" 680 "AMVAC Chemical Corporation" 679 "Cimco Marine AB" 678 "KeepTruckin, Inc." 677 "DSA Daten- und Systemtechnik GmbH" 676 "Danfoss IXA A/S" 675 "Kawasaki Motors Corp., USA" 674 "Yara International ASA" 673 "Caruelle Nicolas" 672 "OPTIMA Concept" 671 "Innovative Controls Inc." 670 "STEMCO LP" 669 "Quantum Fuel Systems Technologies Worldwide, Inc" 668 "MacDon Industries Ltd." 667 "Bartec" 666 "Schaeffler Technologies AG & Co., KG" 665 "Gebr. Bode GmbH & Co. KG" 664 "Level Developments Ltd" 663 "Delta Systems, Inc" 662 "Kissling Elektrotechnik GmbH" 661 "SPAL Automotive S.r.l." 660 "Auto-Gaz Centrum" 659 "Data Panel Corp." 658 "Shenzhen Jiuzhou Himunication Technology Co., Ltd" 657 "Terzo Power Systems" 656 "PRO SOLUS do Brasil" 655 "Genge & Thoma AG" 654 "Kohler Power Systems, Detroit Engine Development Center (DEDC)" 653 "AEV, spol. s r. o." 652 "MicroControl GmbH & Co. KG" 651 "Takakita Co, Ltd." 650 "Seiko Epson Corp." 649 "Control-Q BV" 648 "OJSC Ekran" 647 "Siloking" 646 "Veenhuis Machines BV" 645 "esd electronic system design gmbh" 644 "KUS USA" 643 "Bogballe A/S" 642 "Moog / Aspen Motion Technologies" 641 "Diverse Yacht Services" 640 "Power Solutions International" 639 "Startec s.r.l." 638 "KVH Industries, Inc." 637 "Bavaria Yachtbau GmbH" 636 "Divelbiss Corporation" 635 "Argo Tractors S.p.A." 634 "Rocky Research" 633 "TORC Robotics" 632 "Pepperl+Fuchs GmbH" 631 "Reltima" 630 "SmartDrive Systems Inc." 629 "Agri Info Design, Ltd." 524 "Vomax Instrumentation Pty. Ltd." 523 "Reggio Emilia Innovazione" 522 "Nebraska Tractor Test Laboratory" 521 "Clever Devices Ltd." 520 "Trapeze" 519 "Peeters Landbouwmachines b.v." 518 "Transas USA Inc." 517 "Noland Engineering" 516 "AVAT Automation GmbH" 515 "GINAF Trucks Nederland B.V." 514 "DISTek Integration, Inc." 513 "FarmscanAg" 512 "Inpower LLC" 511 "Sulky" 510 "Marinesoft Co. Ltd" 509 "MOTORTECH GmbH" 508 "Transtech Innovations" 507 "ISOBUS Test Center" 506 "IHI STAR Machinery Corporation" 505 "Yetter Farm Equipment" 504 "Vesper Marine" 503 "Naviop S.R.L." 502 "Attwood Corporation" 501 "Agrotronix S.A." 500 "Oxbo International Corporation" 499 "LCJ Capteurs" 498 "Innovative Design Solutions, Inc." 497 "SENTRON Sistemas Embarcados" 496 "W. Gessmann GmbH" 495 "HOLMER Maschinenbau GmbH" 494 "Synerject" 493 "Watcheye" 492 "Inergy Automotive Systems" 491 "Penny and Giles Ltd" 490 "QuikQ" 489 "Appareo Systems, LLC" 488 "The Charles Machine Works, Inc." 487 "DSE Test Solutions A/S" 486 "Westport Innovations Inc." 485 "MATT automotive" 484 "Headsight Inc." 483 "Valeo" 482 "Tricon Electronics" 481 "Chetco Digital Instruments" 480 "EnerDel, Inc." 479 "Vapor Bus International" 478 "OceanSat BV" 477 "OilQuick AB" 476 "Hummingbird Marine Electronics" 475 "GME" 474 "Persen Technologies Inc." 473 "Boss Industries, Inc." 472 "Tenneco Inc." 471 "Sea Cross Marine AB" 628 "Falck Schmidt Defence Systems" 627 "Radio Ocean" 626 "AVL DiTEST GmbH" 625 "Global MRV Inc." 624 "Blackbox Machine Control Pty Ltd" 623 "Xirgo Technologies" 622 "Floyd Bell Inc" 621 "Hagie Manufacturing Company" 620 "Sevcon Ltd." 619 "Right Weigh Load Scales" 618 "Evrard SA" 617 "Zero Emission Vehicles" 616 "SMART-TEC s.r.o." 615 "Networkfleet, Verizon Telematics" 614 "ARLT Technologies GmbH" 613 "HKS Co., Ltd." 612 "Samwon IT" 611 "Esterline" 610 "Trail Tech" 609 "Walvoil S.p.A." 608 "Gale Banks Engineering" 607 "Knappco/Civacon" 606 "Intellian Technologies" 605 "Aventics GmbH" 604 "Indexator Rototilt Systems AB" 603 "Kereval" 602 "Nomad Digital Ltd." 601 "Navitas Systems" 600 "Aquatic AV" 599 "Spudnik Equipment Co, LLC" 598 "ABB Turbo Systems Ltd" 597 "Hydac Filter Systems GmbH" 596 "Brunelco Electronic Innovators B.V." 595 "CustomWare" 594 "Kongsberg Automotive" 593 "Sensata Technologies" 592 "tecsis GmbH" 591 "United States Coast Guard" 590 "ARGO-HYTOS GMBH" 589 "MICO, Inc." 588 "Vignal Systems" 587 "JCA Electronics" 586 "Suzuki Motor Corp" 585 "Industrial Electronic Controls" 584 "CarMedialab GmbH" 583 "Yachtcontrol" 582 "Innovative Software Engineering" 581 "Väderstad - Verken AB" 580 "San Jose Technology, Inc." 579 "KVH Industries, Inc." 578 "advanSea" 577 "Denchi Power Ltd  (formerly ABSL Power Solutions Limited)" 576 "Vectia" 575 "Lytx" 574 "Vishay Precision Group" 573 "Orolia Ltd" 572 "Fasse Valves" 571 "Marinecraft Co., Ltd." 570 "frenzel + berg electronic GmbH & Co. KG" 569 "LORD MicroStrain Sensing Systems" 568 "Makersan Ltd. Co." 567 "Lithiumstart LLC" 566 "Geode Technology, Inc." 565 "Micro-Trak Systems, Inc." 564 "Auto Power Electronic" 563 "LOHR Sistemas Eletronicos LTDA" 562 "Bombardier Transportation GmbH" 561 "b-plus GmbH" 560 "Iowa State University, Agricultural and Biosystems Engineering" 559 "Four Peaks Navigation" 558 "Davis Instruments Corp." 557 "Rockson Automation GmbH" 556 "Doosan Infracore Norway" 555 "Sasaki Corporation" 554 "iris-GmbH infrared & intelligent sensors" 553 "KIB Electronics" 552 "Matsuyama Plow Mfg Co, Ltd" 551 "Wexler CSD Ltd." 550 "SUN-A Corporation" 549 "ROAD Deutschland GmbH" 548 "TM4 Inc." 547 "Thomson Linear LLC" 546 "Maruyama Mfg Co, Inc." 545 "GS Hydraulics" 544 "Au Group Electronics" 543 "BAUER Maschinen GmbH" 542 "Dinamica Generale s.p.a." 541 "Total Fire Systems, Inc." 540 "Dinex A/S" 539 "Mobileview" 538 "Crop Ventures, Inc." 537 "Schrader Electronics Ltd." 536 "SSI Technologies" 535 "MOTORPAL, a.s." 534 "Webasto Thermo & Comfort SE" 533 "Doran Manufacturing, LLC" 532 "Onwa Marine Electronics Co Ltd." 531 "Genge & Thoma AG" 530 "NMEA" 529 "National Instruments Korea" 528 "Hoganas AB, Electric Drive Systems" 527 "GKN Walterscheid GmbH" 526 "LOFA Industries, Inc" 525 "Rust Sales INC" 470 "SI-TEX Marine Electronics" 469 "RA Consulting GmbH" 468 "Tyco Fire Protection Products" 467 "Lely Industries N.V." 466 "Veethree Electronics and Marine LLC" 465 "Ashcroft Inc" 464 "Leach International Corporation" 463 "PROBOTIQ" 462 "IHI Shibaura Machinery Corporation" 461 "HAWE Hydraulik SE" 460 "San Giorgio S.E.I.N." 459 "Alltek Marine Electronics Corp" 458 "Control Solutions, Inc." 457 "RUSELPROM-ElectricDrive Ltd" 456 "General Kinetics" 455 "ADZ NAGANO GmbH" 454 "NGK Spark Plug Co. Ltd" 453 "Cooper Bussmann" 452 "WIKA Alexander Wiegand SE & Co. KG" 451 "Parker Hannifin Corp" 450 "Dycor Technologies Ltd." 449 "Polaris Industries Inc" 448 "Stanadyne Corporation, Electronics Systems" 447 "Great Plains Mfg." 446 "CertTech, L.L.C." 445 "KAT MECHATRONIC, Electronic Product Division" 444 "ITT Power Solutions" 443 "SignalQuest, Inc." 442 "Horsch Maschinen GmbH" 441 "PTG Reifendruckregelsysteme GmbH" 440 "Cummins Power Generation" 439 "Hyundai Heavy Industries" 438 "Comar Systems Ltd" 437 "Digital Yacht Limited" 436 "Kinze Manufacturing" 435 "Zunhammer GmbH" 434 "Stored Energy Systems" 433 "Rowe Electronics" 432 "S&A Systems, Inc." 431 "Tohatsu Corporation" 430 "Auteq Telematica S.A." 429 "Rota Engineering Ltd." 425 "Methode Electronics Inc, MDI" 424 "Odyne LLC" 423 "BSM Wireless, Inc." 422 "True Heading AB" 421 "Vertex Standard Co, Ltd" 420 "Vermeer Corporation, ACS Group" 419 "Fusion Electronics Ltd" 418 "Intellistick Inc" 417 "KZValve" 416 "Kubota Corporation" 415 "Valid Manufacturing Ltd." 414 "Cattron Group International" 413 "Datapross Nijbroek bv" 412 "WebTech Wireless Inc." 411 "Hy-Drive Technologies Ltd." 410 "COBO S.p.A. Divisione 3B6" 409 "Transfluid S.r.L." 408 "Corvus Energy Ltd." 407 "Comtech Mobile Datacom" 406 "Vecima Networks Inc." 405 "Wema System AS" 404 "Com Nav Marine Ltd" 403 "Trackwell ADS, Inc." 402 "Simma Software, Inc." 401 "Torqeedo GmbH" 400 "Livorsi Marine" 399 "ISEKI & Co., Ltd." 398 "Hilite International" 397 "Sanyo-kiki Co Ltd." 396 "Beyond Measure" 395 "GENTEC S.R.L." 394 "Capi 2 Nederland BV" 393 "Harvest Tec, Inc" 392 "Tianyuan Technology Co Ltd." 391 "Electronic Design for Industry, Inc" 390 "Partech Inc." 389 "Benchmark Electronics, Minnesota Division" 388 "Innomatix, LLC" 387 "Orscheln Products, LLC" 386 "JLG Automation BVBA" 385 "Johnson Outdoor Marine Electronics" 384 "Camano Light" 383 "MCL Industries" 382 "National Agriculture and Food Research Organization" 381 "B & G" 380 "Suntech International Ltd." 379 "Yamabiko Corporation" 378 "Glendinning Marine Products" 377 "ifm electronic gmbh" 376 "Quake Global" 375 "Williams Controls Inc." 374 "Northern Lights, Inc." 373 "Electronic Design Inc." 372 "Delphi" 371 "Heinzmann GmbH & Co. KG" 370 "Rolls-Royce Marine AS" 369 "Power Torque Engineering Ltd" 368 "HANSENHOF_electronic" 367 "Fliegl Agrartechnik" 366 "Viewnyx Corp." 365 "Digi-Star, LLC" 364 "OEM Controls Inc." 363 "BEI Duncan" 362 "Poettinger Landtechnik GmbH (formerly Alois Poettinger Maschinenfabrik GmbH)" 361 "InMach" 360 "HJS Emission Technology GmbH & Co KG   (formerly HJS Fahrzeugtechnik GmbH & Co KG)" 359 "Ludwig Bergmann GmbH" 358 "Victron Energy BV" 357 "Hardi International A/S" 356 "Fischer Panda Generators, Inc" 355 "Mastervolt International B.V." 354 "Junkkari OY" 353 "Hegemon Electronics, Inc." 352 "SAME DEUTZ-FAHR GROUP S.p.A." 351 "Thrane & Thrane" 350 "Noris Marine Systems GmbH & Co KG" 349 "Suonentieto" 348 "Amazonen Werke H. Dreyer" 347 "Honeywell" 346 "Control Solutions" 345 "Korean Maritime University" 344 "Parvus Corporation" 343 "Baumer Group" 342 "THOMAS MAGNETE GmbH" 341 "Boning GmbH & Co" 340 "Continental AG" 339 "Competence Center ISOBUS e.V." 338 "GRAF-SYTECO" 337 "Carraro S.p.A." 336 "APE s.r.o." 335 "Evo Electric Ltd" 334 "Takata-Petri AG" 333 "Hadley Products Corporation" 332 "HWH Corporation" 331 "Horton, Inc." 330 "Kidde Aerospace and Defense" 329 "Deif A/S" 328 "Qwerty Electronik AB" 327 "Sonceboz SA" 326 "Akron Brass Company" 325 "ASM Automation Sensorik Messtechnik GmbH" 324 "Snap-on Diagnostics" 323 "Mobileye Vision Technologies Ltd." 322 "MICHENKA s.r.o." 321 "Ultra Electronics, Electrics" 320 "Miedema Landbouwwerktuigenfabriek B.V." 319 "Cadec Global" 318 "SAT Plan" 317 "Navtronics Bvba" 263 "IMMI" 262 "HydraForce, Inc" 261 "Red Dot Corporation" 260 "Reichhardt GmbH Steuerungstechnik" 259 "Jetter AG" 258 "ARAG" 257 "Honda Motor Co., Ltd" 256 "Tyco Electronics AMP" 255 "MEAS France" 254 "GE Sensing" 253 "Mobile Control Systems" 252 "Sensor-Technik Wiedemann GmbH" 251 "German Agricultural Society, Test Center (DLG)" 250 "Kuhn Group" 249 "Schaltbau GmbH" 248 "Cooper Standard Automotive Active Systems Group" 247 "ePULSE" 246 "Class 1, Inc" 245 "Capstan Ag Systems, Inc." 244 "Techno-Matic" 243 "eRide, Inc." 242 "Kokusandenki Co. Ltd" 241 "Schneider Automation SAS" 240 "Vanair Mfg" 239 "May & Scofield Ltd" 238 "ZF Friedrichshafen AG" 237 "Agtron Enterprises Inc" 236 "NORAC Systems International Inc" 235 "SailorMade Marine Telemetry - Tetra Technology Ltd." 234 "Mondial electronic GmbH" 233 "Yacht Monitoring Solutions Inc." 232 "TSD Integrated Controls" 231 "Topcon Positioning Systems, Inc." 230 "Saucon Technologies" 229 "Garmin International Inc." 228 "Unused (formerly ZF Marine Electronics)" 227 "Lykketronic A/S" 226 "Monaco Coach Corporation" 225 "SKF" 224 "EMMI Network, S.L." 223 "Vaueo Retarder Co., Ltd." 222 "Generac Power Systems, Inc." 221 "SiE" 220 "Beede Electrical Instrument Company, Inc" 219 "Cat OEM Solutions" 218 "Gits Manufacturing Company" 217 "RM Michaelides Software & Elektronik GmbH" 216 "Paneltronics Inc." 215 "Aetna Engineering/Fireboy-Xintex" 214 "MC elettronica Srl" 164 "MTU Friedrichshafen GmbH (formerly DaimlerChrysler Off-Highway)" 163 "BRP Inc." 162 "Axiomatic Technologies" 161 "Offshore Systems (UK) Ltd" 160 "Nido" 159 "NTech Industries Inc" 158 "Firestone Industrial Products Company" 157 "ISSPRO Inc." 156 "ITT Industries - Cannon" 155 "Vetronix Corporation" 154 "Westerbeke Corporation" 153 "Woodward, Industrial Controls Division" 152 "elobau GmbH & Co. KG" 151 "Raven Industries, Inc." 150 "Fleetguard" 149 "Holset" 148 "Blue Water Data, Inc." 147 "Nautibus electronic GmbH" 146 "Maxima Technologies" 145 "MurCal Controls" 144 "Mercury Marine" 143 "W. Gmeiner GmbH & Co." 142 "TRW Automotive (Commercial Steering Systems)" 141 "Thales Navigation Ltd." 140 "Lowrance Electronics, Inc." 139 "Caterpillar Trimble Control Technologies (CTCT), LLC" 138 "Georg Fritzmeier GmbH & Co. KG" 137 "Maretron" 136 "Komatsu Ltd" 135 "Airmar Technology Corporation" 134 "Iris Technology Ltd" 133 "Bucher Schoerling GmbH" 132 "Mulag-Fahrzeugwerk" 131 "ITT Industries" 130 "Nido - Universal Machines B.V." 129 "OMNEX Control Systems Inc." 128 "Gerhard Duecker GmbH & Co. KG" 127 "Holland USA" 126 "Driver Tech" 125 "Nevada Automotive Test Center" 124 "Hydac Electronic" 123 "Basler Electric" 122 "FG Wilson (Engineering) Limited" 121 "HED (Hydro Electronic Devices, Inc.)" 120 "RDS Technology Ltd" 119 "IntegriNautics  " 118 "Intron GmbH" 117 "HUSCO International" 116 "BEELINE Technologies" 115 "NACCO Materials Handling Group, Inc." 114 "EControls, Inc." 113 "Stress-Tek, Inc." 112 "MECALAC" 111 "Maschinenfabrik Bernard Krone GmbH" 110 "EPIQ Sensor-Nite" 109 "TeeJet Technologies Denmark (formerly LH Technologies ApS)" 108 "WTK-Elecktronik GmbH" 107 "Grimme Landmaschinen GmbH & Co. KG" 106 "BAE Systems Controls, Inc." 105 "Kiepe Elektrik GmbH & Co. KG" 104 "CLAAS KGaA mbH (formerly CLAAS Selbstfahrende Erntemaschinen GmbH)" 103 "CLAAS E-Systems KGaA mbH & Co. KG (formerly CLAAS Agrosystems GmbH & Co. KG)" 102 "AGCO (formerly AGCO GmbH & Co.)" 101 "Sensoria" 100 "VDO Technik AG" 99 "International Transmissions Ltd (ITL)" 98 "Mueller-Elektronik GmbH & Co" 97 "Ag Leader Technology, Inc." 96 "Mech@tronic IT GmbH" 95 "Pacific Insight Electronics Corp." 94 "CNH Industrial N.V. (formerly CNH Global N.V.)" 93 "Perkins Engines Company Ltd." 92 "Ag-Chem Equipment Co., Inc." 91 "BSG Bodensee Steuergeraete GmbH" 90 "Knorr-Bremse SfN GmbH" 89 "Kverneland Group, Electronics Division" 88 "Satloc Precision GPS" 87 "J.C. Bamford Excavators Ltd (JCB)" 86 "C. E. Niehoff & Company" 85 "Kohler Co" 84 "New Holland UK Limited" 83 "Bendix VORAD Technologies (formerly Eaton VORAD Technologies)" 82 "Bobcat/Ingersoll-Rand (formerly Melroe/Ingersoll-Rand)" 81 "Fire Research Corp." 80 "Twin Disc, Inc." 79 "Daimler Benz AG - Engine Division (PBM)" 78 "Frank W. Murphy Manufacturing, Inc" 77 "Deere Power Systems Group" 76 "unused (formerly Deere & Co, Construction Division)" 75 "Deere & Co, Agricultural Division" 74 "Eaton Axle-Brake Division" 73 "LeTourneau, Inc." 72 "Sisu Corporation" 71 "Vansco Electronics Ltd." 70 "Flex-coil Limited" 69 "Trimble Navigation" 316 "ITT Flow Control" 315 "Icom Incorporated" 314 "CSM GmbH" 313 "Ilmor Engineering, Inc." 312 "Lectronix, Inc." 311 "Patrick Power Products" 310 "TECNORD srl" 309 "Krauss-Maffei Wegmann GmbH & Co. KG" 308 "Cyntrx" 307 "MAS Technologies" 306 "Sleipner Motor AB" 305 "NovAtel Inc" 304 "EmpirBus AB" 303 "CTS Corporation" 302 "Nissin Kogyo Co., LTD" 301 "Parker Hannifin (UK) Ltd FDE group" 300 "Systron Donner Automotive" 299 "Rauch" 298 "Holley Performance" 297 "Zonar Systems Inc" 296 "micro dynamics GmbH" 295 "BEP Marine" 294 "Grayhill Inc." 293 "Spyder Controls Corp." 292 "IKUSI - Angel Iglesias S.A." 291 "Groeneveld Transport Efficiency BV" 290 "Kuebler GmbH" 289 "Watlow" 288 "Mitsubishi FUSO Truck & Bus Corp." 287 "NTech Industries, Inc" 286 "Coelmo srl" 285 "Sea Recovery Corp" 284 "Mobile Tech Chile" 283 "CWF Hamilton & Co Ltd" 282 "Medallion Instrumentation Systems" 281 "Precision Governors LLC" 280 "Leica Geosystems Pty Ltd" 279 "Geometris LP" 278 "Takata Electronics" 277 "LHP Telematics" 276 "Aqua-Hot Heating Systems" 275 "Navico Egersund AS" 274 "LTW Technology Co., LTD" 273 "Active Research Limited" 272 "Gross Mechanical Laboratories, Inc" 271 "Cole Hersee" 270 "Tennant" 269 "Saft America Inc.,  Space & Defense Division" 268 "Accurate Technologies" 267 "Red Lion Controls, Inc" 266 "International Thermal Research Ltd" 265 "MTS Sensor Technologie GmbH" 264 "Autolync" 213 "CNH Belgium N.V." 212 "Sure Power Industries, Inc" 211 "DNA Group" 210 "Iteris, Inc." 209 "Bell Equip. Co. SA (PTY) LTD" 208 "Drew Technologies, Inc" 207 "Otto Engineering" 206 "port GmbH" 205 "SmarTire Systems Inc" 204 "The Morey Corporation" 203 "MILtronik GmbH" 202 "Curtis Instruments, Inc" 201 "Disenos y Tecnologia S.A." 200 "MGM Brakes" 199 "Actia Corp" 198 "Mystic Valley Communications" 197 "Mechron Power Systems" 196 "LEMKEN GmbH & Co KG" 195 "General Engine Products" 194 "TriMark Corporation" 193 "Jeppesen Marine" 192 "Floscan" 191 "XRS Corporation (formerly XATA Corporation)" 190 "Hella KGaA Hueck & Co" 189 "QUALCOMM" 188 "EMP Corp" 187 "Air-Weigh" 186 "Altronic, Inc" 185 "Beede Electrical Instrument Company" 184 "EIA Electronics" 183 "KDS Controls, Inc" 182 "Vehicle Systems Engineering B.V." 181 "Coretronics, Inc." 180 "Smart Power Systems" 179 "TeeJet Technologies Springfield (formerly Midwest Technologies Illinois, LLC)" 178 "Continental Automotive GmbH (formerly Siemens VDO Automotive AG)" 177 "Diagnostic Systems Associates" 176 "Moritz Aerospace" 175 "Veris Technologies, Inc." 174 "AB Volvo Penta" 173 "Ryeso, Inc." 172 "Yanmar Co., Ltd. (formerly Yanmar Marine USA)" 171 "Wachendorff Elektronik GmbH & Co. KG" 170 "Computronics Corporation Ltd." 169 "Marlin Technologies Inc." 168 "Xantrex" 167 "JLG Industries Inc" 166 "John Deere Electronic Solutions (formerly Phoenix International)" 165 "CPAC Systems AB" 68 "Scania" 67 "John Deere Coffeyville Works (formerly Funk Manufacturing Company)" 66 "John Deere Construction Equipment Division" 65 "MAN Nutzfahrzeuge AG" 64 "Unused (formerly SpectraPrecision Laserplane, then SpectraPhysics)" 63 "ZF Industries Inc." 62 "Wabco" 61 "Volvo Truck Corp." 60 "Volvo Trucks North America Inc." 59 "VES Inc." 58 "SPX Corporation, OTC Div" 57 "Danfoss  (formerly Sauer Sundstrand Co, then Sauer-Danfoss Co)" 56 "SAIC" 55 "Ryder System Inc." 54 "Meritor Wabco" 53 "Continental Automotive Systems US, Inc. (formerly Rockwell Land Transportation)" 52 "Meritor Automotive, Inc. (formerly Rockwell Automotive)" 51 "Robert Bosch GmbH" 50 "Robert Bosch Corp" 49 "RE America Inc." 48 "Pollak Alphabet" 47 "Phillips Semiconductor" 46 "Noregon Systems, Inc  (formerly Parasoft Computing Solutions)" 45 "PACCAR" 44 "Nippondenso Co. Ltd." 43 "International Truck and Engine Corporation - Vehicle Electronics (formerly Navistar Intl Trans Corp.)" 42 "International Truck and Engine Corporation - Engine Electronics  (formerly Navistar Intl Trans Co., Engine Electronics)" 41 "Motorola Inc." 40 "Motorola AIEG Inc." 39 "Microfirm Inc." 38 "Micro Processor Systems Inc." 37 "Mack Trucks Inc." 36 "Lucas Ind." 35 "Kenworth Truck Co." 34 "Kelsey Hayes Co." 33 "John Deere" 32 "Jacobs Vehicle Systems" 31 "J Pollak Corp" 30 "Isuzu Motors Ltd" 29 "Hino Motors Ltd." 28 "Grote Ind. Inc." 27 "GMC" 26 "General Motors Corp, Service Technology Grp" 25 "Daimler Trucks North America LLC (formerly Freightliner LLC)" 24 "Ford Motor Co., Vehicle Controls" 23 "Ford Motor Co., Heavy Truck" 22 "Ford Motor Co., Electronic Concepts & Systems" 21 "Echlin Inc., Midland Brake Inc." 20 "Eaton Ltd" 19 "Eaton Corp. Trucking Info Services" 18 "Eaton Corp, Transmission Div." 17 "Eaton Corp, Corp Res & Dev" 16 "Eaton Corp" 15 "DICKEY-john Corporation" 14 "Detroit Diesel Corporation" 13 "Delco Electronics" 12 "Deere & Company, Precision Farming" 11 "Dearborn Group Inc." 10 "Cummins Inc (formerly Cummins Engine Co)" 9 "Chrysler Corp." 8 "Caterpillar Inc." 7 "Case Corp." 6 "Berifors Electronics AB" 5 "AMP Inc." 4 "Ametek-Dixson" 3 "Ametek, US Gauge Division" 2 "Allison Transmission, Inc." 1 "Bendix Commercial Vehicle Systems LLC (formerly Allied Signal Inc.)" 0 "Reserved" ;
VAL_ 2565799427 IndustryGroup 7 "Reserved for SAE" 5 "IndustrialProcessCtrlStationary" 4 "Marine" 3 "Construction" 2 "Agricultural and Forestry" 1 "On-Highway" 0 "Global" ;
VAL_ 2565799427 VehicleSystem 127 "Not Available" 0 "Non-specific System" ;
VAL_ 2565799427 VehicleSystem5 0 "Ind. Process Control Stationary" 127 "Not Available" ;
VAL_ 2565799427 VehicleSystem4 0 "Non-specific System" 127 "Not Available" 10 "System Tools" 20 "Safety Systems" 25 "Inter/Intranetwork Device" 30 "Electrical Distribution" 40 "Steering and Control Surfaces" 50 "Propulsion" 60 "Navigation" 70 "Communications" 80 "Instrumentation/General Systems (deprecate)" 90 "Internal Environment" 100 "Deck, Cargo and Fishing Equipment" 35 "Electrical Generation" 75 "Sensor Communication Interface" 85 "External Environment" 120 "Display" 125 "Entertainment" ;
VAL_ 2565799427 VehicleSystem3 0 "Non-specific System" 127 "Not Available" 1 "Skid Steer Loader" 2 "Articulated Dump Truck" 3 "Backhoe" 4 "Crawler" 5 "Excavator" 6 "Forklift" 7 "Four Wheel Drive Loader" 8 "Grader" ;
VAL_ 2565799427 VehicleSystem2 0 "Non-specific System" 127 "Not Available" 1 "Tractor" 2 "Tillage" 3 "Secondary Tillage" 4 "Planters/Seeders" 5 "Fertilizers" 6 "Sprayers" 7 "Harvesters" 8 "Root Harvesters" 9 "Forage" 10 "Irrigation" 11 "Transport/Trailer" 12 "Farm Yard Operations" 13 "Powered Auxiliary Device" 14 "Special Crops" 15 "Earth Work" 16 "Skidder" 17 "Sensor Systems" 19 "Timber Harvesters" 20 "Forwarders" 21 "Timber loaders" 22 "Timber Processing Machines" 23 "Mulchers" 24 "Utility Vehicles" 25 "Slurry Applicators" ;
VAL_ 2565799427 VehicleSystem1 0 "Non-specific System" 127 "Not Available" 1 "Tractor" 2 "Trailer" ;
VAL_ 2565799427 Function 43 "Transmission Display" 44 "Exhaust Emission Control" 45 "Vehicle Dynamic Stability Control" 46 "Oil Sensor Unit" 47 "Information System Controller" 48 "Ramp Control" 49 "Clutch/Converter Control" 50 "Auxiliary Heater" 51 "Forward-Looking Collision Warning System" 52 "Chassis Controller" 53 "Alternator/Charging System" 54 "Communications Unit, Cellular" 55 "Communications Unit, Satellite" 56 "Communications Unit, Radio" 57 "Steering Column Unit" 58 "Fan Drive Control" 59 "Starter" 60 "Cab Display" 61 "File Server/Printer" 62 "On-Board Diagnostic Unit" 63 "Engine Valve Controller" 64 "Endurance Braking" 65 "Gas Flow Measurement" 66 "I/O Controller" 67 "Electrical System Controller" 68 "Aftertreatment system gas measurement" 69 "Engine Emission Aftertreatement System" 70 "Auxiliary Regeneration Device" 71 "Transfer Case Control" 72 "Coolant Valve Controller" 73 "Rollover Detection Control" 74 "Lubrication System" 75 "Supplemental Fan" 76 "Temperature Sensor" 77 "Fuel Properties Sensor" 78 "Fire Suppression System" 79 "Power Systems Manager" 80 "Electric Powertrain" 81 "Hydraulic Powertrain" 82 "File Server" 83 "Printer" 84 "Start Aid Device" 85 "Engine Injection Control Module" 86 "Reserved" 87 "Reserved" 88 "Reserved" 89 "Reserved" 90 "Reserved" 91 "Reserved" 92 "Reserved" 93 "Reserved" 94 "Reserved" 95 "Reserved" 96 "Reserved" 97 "Reserved" 98 "Reserved" 99 "Reserved" 100 "Reserved" 0 "Engine" 1 "Auxiliary Power Unit (APU)" 2 "Electric Propulsion Control" 3 "Transmission" 4 "Battery Pack Monitor" 5 "Shift Control/Console" 6 "Power TakeOff - (Main or Rear)" 7 "Axle - Steering" 8 "Axle - Drive" 9 "Brakes - System Controller" 10 "Brakes - Steer Axle" 11 "Brakes - Drive Axle" 12 "Retarder - Engine" 13 "Retarder - Driveline" 14 "Cruise Control" 15 "Fuel System" 16 "Steering Controller" 17 "Suspension - Steer Axle" 18 "Suspension - Drive Axle" 19 "Instrument Cluster" 20 "Trip Recorder" 21 "Cab Climate Control" 22 "Aerodynamic Control" 23 "Vehicle Navigation" 24 "Vehicle Security" 25 "Network Interconnect ECU" 26 "Body Controller" 27 "Power TakeOff (Secondary or Front)" 28 "Off Vehicle Gateway" 29 "Virtual Terminal (in cab)" 30 "Management Computer" 31 "Propulsion Battery Charger" 32 "Headway Controller" 33 "System Monitor" 34 "Hydraulic Pump Controller" 35 "Suspension - System Controller" 36 "Pneumatic - System Controller" 37 "Cab Controller" 38 "Tire Pressure Control" 39 "Ignition Control Module" 40 "Seat Control" 41 "Lighting - Operator Controls" 42 "Water Pump Control" 101 "Reserved" 102 "Reserved" 103 "Reserved" 104 "Reserved" 105 "Reserved" 106 "Reserved" 107 "Reserved" 108 "Reserved" 109 "Reserved" 110 "Reserved" 111 "Reserved" 112 "Reserved" 113 "Reserved" 114 "Reserved" 115 "Reserved" 116 "Reserved" 117 "Reserved" 118 "Reserved" 119 "Reserved" 120 "Reserved" 121 "Reserved" 122 "Reserved" 123 "Reserved" 124 "Reserved" 125 "Reserved" 126 "Reserved" 127 "Reserved" 255 "Not Available" ;
VAL_ 2565799427 ManufacturerCode 1863 "Thomas G. Faria Co." 1862 "Sanshin" 1861 "Vector North America " 1860 "MMP" 1859 "Kvasar AB" 1858 "Litton" 1857 "Simrad" 1856 "Trimble" 1855 "Furuno USA" 1854 "Northstar Technologies" 1853 "Japan Radio Co" 1852 "Navionics" 1851 "RayMarine" 1850 "Teleflex" 786 "Johnson Matthey Battery Systems" 785 "Fischer Panda GmbH" 784 "CM Automotive Systems, Inc." 783 "Loup Electronics Inc." 782 "AVR bvba" 781 "Poly-Planar LLC" 780 "AVID Technology Ltd" 779 "RLC Electronic Systems" 778 "Seakeeper Inc." 777 "Ocean Signal Ltd" 776 "HMI Systems LLC" 775 "ZIEHL-ABEGG Automotive GmbH" 774 "Taisho Corporation" 773 "Clarion Corporation of America" 772 "Blink Marine" 771 "Shaw Development, LLC" 770 "MONOSEM" 769 "Trombetta" 768 "Flores Automation, LLC" 767 "Alliance Wireless Technologies Inc." 766 "Epec Oy" 765 "GIGAVAC" 764 "Bednar FMT s.r.o." 763 "AT-Systems BVBA" 762 "ROJ s.r.l." 761 "MITA OLEODINAMICA S.p.A." 760 "Bernecker + Rainer Industrie Elektronik GmbH" 759 "Hydro-Gear" 758 "Banner Engineering Corp." 757 "IMPCO Technologies" 756 "Maschio Gaspardo S.P.A." 755 "Firefly Integrations" 754 "Parker Hannifin Corp., Automation Group" 753 "AIROD Technologies" 752 "Deep Sea Electronics Plc" 751 "Pacific Track" 750 "Joskin SA" 749 "Chart Inc." 748 "ISOTTA" 747 "Agratronix" 746 "SureFire Ag Systems, Inc." 745 "Cidra Corporate Services Inc." 744 "Woosung Engineering Co., Ltd." 743 "Daemyung Elevator Co., Ltd." 742 "EROAD" 741 "Carling Technologies" 740 "e-Traction" 739 "LXNAV d.o.o." 738 "Blue Ink Technologies" 737 "Balluff GmbH" 736 "Terex Aerial Work Platforms - Genie" 735 "AEM Performance Electronics" 734 "REAPsystems" 733 "Intendia S.L." 732 "Gefran S.p.A." 731 "Modine Manufacturing Company" 730 "BERTHOUD AGRICOLE" 729 "Liebherr" 728 "Streumaster / Panien" 727 "Dhoot Transmission Pvt Ltd." 726 "MIDORI PRECISIONS" 725 "Hitachi Construction Machinery Co., Ltd." 724 "Electronic Applications, Inc." 723 "Jabil Inc." 722 "Contelec AG" 721 "Hypro" 720 "WITZ Corporation" 719 "Cojali S. L." 718 "Micronet Inc" 717 "Yacht Devices Ltd" 716 "Eaton Control & Power Conversion Division (CPCD)" 715 "Autonnic Research Ltd" 714 "Kobashi Kogyo Co., Ltd." 713 "US Hybrid Corporation" 712 "LOR Manufacturing Company Inc." 711 "DAS Co., LTD" 710 "Greentronics Ltd." 709 "Marquardt GmbH" 708 "Lars Thrane A/S" 707 "Rochester Gauges Inc" 706 "Shanghai Diesel Engine Corporation Limited" 705 "SVAB Hydraulik AB" 704 "JL Audio, Inc." 703 "Hydro Tab Marine Engineering" 702 "Weichai Power Co., Ltd." 701 "BigRoad Inc." 700 "K-Tec Earthmovers Inc." 699 "Harman International Industries" 698 "Scorpion Technologies Ltd." 697 "Ålö AB" 696 "DRS Network & Imaging Systems, LLC (DRS Technologies)" 695 "Weldon Technologies" 694 "GasTOPS Ltd." 693 "Agility Fuel Solutions (formerly Agility Fuel Systems)" 692 "Tanhay Corporation" 691 "Digitroll Agricultural Electronics" 690 "LINAK A/S" 689 "Aarcomm Systems Inc" 688 "Rockford Corp" 687 "Flight Systems, Inc." 686 "Taigene Electric Machinery Corp." 685 "ANEDO Ltd." 684 "KEB" 683 "Fosen Elektro" 682 "Eckelmann AG" 681 "BEDIA Motorentechnik GmbH & Co. KG" 680 "AMVAC Chemical Corporation" 679 "Cimco Marine AB" 678 "KeepTruckin, Inc." 677 "DSA Daten- und Systemtechnik GmbH" 676 "Danfoss IXA A/S" 675 "Kawasaki Motors Corp., USA" 674 "Yara International ASA" 673 "Caruelle Nicolas" 672 "OPTIMA Concept" 671 "Innovative Controls Inc." 670 "STEMCO LP" 669 "Quantum Fuel Systems Technologies Worldwide, Inc" 668 "MacDon Industries Ltd." 667 "Bartec" 666 "Schaeffler Technologies AG & Co., KG" 665 "Gebr. Bode GmbH & Co. KG" 664 "Level Developments Ltd" 663 "Delta Systems, Inc" 662 "Kissling Elektrotechnik GmbH" 661 "SPAL Automotive S.r.l." 660 "Auto-Gaz Centrum" 659 "Data Panel Corp." 658 "Shenzhen Jiuzhou Himunication Technology Co., Ltd" 657 "Terzo Power Systems" 656 "PRO SOLUS do Brasil" 655 "Genge & Thoma AG" 654 "Kohler Power Systems, Detroit Engine Development Center (DEDC)" 653 "AEV, spol. s r. o." 652 "MicroControl GmbH & Co. KG" 651 "Takakita Co, Ltd." 650 "Seiko Epson Corp." 649 "Control-Q BV" 648 "OJSC Ekran" 647 "Siloking" 646 "Veenhuis Machines BV" 645 "esd electronic system design gmbh" 644 "KUS USA" 643 "Bogballe A/S" 642 "Moog / Aspen Motion Technologies" 641 "Diverse Yacht Services" 640 "Power Solutions International" 639 "Startec s.r.l." 638 "KVH Industries, Inc." 637 "Bavaria Yachtbau GmbH" 636 "Divelbiss Corporation" 635 "Argo Tractors S.p.A." 634 "Rocky Research" 633 "TORC Robotics" 632 "Pepperl+Fuchs GmbH" 631 "Reltima" 630 "SmartDrive Systems Inc." 629 "Agri Info Design, Ltd." 524 "Vomax Instrumentation Pty. Ltd." 523 "Reggio Emilia Innovazione" 522 "Nebraska Tractor Test Laboratory" 521 "Clever Devices Ltd." 520 "Trapeze" 519 "Peeters Landbouwmachines b.v." 518 "Transas USA Inc." 517 "Noland Engineering" 516 "AVAT Automation GmbH" 515 "GINAF Trucks Nederland B.V." 514 "DISTek Integration, Inc." 513 "FarmscanAg" 512 "Inpower LLC" 511 "Sulky" 510 "Marinesoft Co. Ltd" 509 "MOTORTECH GmbH" 508 "Transtech Innovations" 507 "ISOBUS Test Center" 506 "IHI STAR Machinery Corporation" 505 "Yetter Farm Equipment" 504 "Vesper Marine" 503 "Naviop S.R.L." 502 "Attwood Corporation" 501 "Agrotronix S.A." 500 "Oxbo International Corporation" 499 "LCJ Capteurs" 498 "Innovative Design Solutions, Inc." 497 "SENTRON Sistemas Embarcados" 496 "W. Gessmann GmbH" 495 "HOLMER Maschinenbau GmbH" 494 "Synerject" 493 "Watcheye" 492 "Inergy Automotive Systems" 491 "Penny and Giles Ltd" 490 "QuikQ" 489 "Appareo Systems, LLC" 488 "The Charles Machine Works, Inc." 487 "DSE Test Solutions A/S" 486 "Westport Innovations Inc." 485 "MATT automotive" 484 "Headsight Inc." 483 "Valeo" 482 "Tricon Electronics" 481 "Chetco Digital Instruments" 480 "EnerDel, Inc." 479 "Vapor Bus International" 478 "OceanSat BV" 477 "OilQuick AB" 476 "Hummingbird Marine Electronics" 475 "GME" 474 "Persen Technologies Inc." 473 "Boss Industries, Inc." 472 "Tenneco Inc." 471 "Sea Cross Marine AB" 628 "Falck Schmidt Defence Systems" 627 "Radio Ocean" 626 "AVL DiTEST GmbH" 625 "Global MRV Inc." 624 "Blackbox Machine Control Pty Ltd" 623 "Xirgo Technologies" 622 "Floyd Bell Inc" 621 "Hagie Manufacturing Company" 620 "Sevcon Ltd." 619 "Right Weigh Load Scales" 618 "Evrard SA" 617 "Zero Emission Vehicles" 616 "SMART-TEC s.r.o." 615 "Networkfleet, Verizon Telematics" 614 "ARLT Technologies GmbH" 613 "HKS Co., Ltd." 612 "Samwon IT" 611 "Esterline" 610 "Trail Tech" 609 "Walvoil S.p.A." 608 "Gale Banks Engineering" 607 "Knappco/Civacon" 606 "Intellian Technologies" 605 "Aventics GmbH" 604 "Indexator Rototilt Systems AB" 603 "Kereval" 602 "Nomad Digital Ltd." 601 "Navitas Systems" 600 "Aquatic AV" 599 "Spudnik Equipment Co, LLC" 598 "ABB Turbo Systems Ltd" 597 "Hydac Filter Systems GmbH" 596 "Brunelco Electronic Innovators B.V." 595 "CustomWare" 594 "Kongsberg Automotive" 593 "Sensata Technologies" 592 "tecsis GmbH" 591 "United States Coast Guard" 590 "ARGO-HYTOS GMBH" 589 "MICO, Inc." 588 "Vignal Systems" 587 "JCA Electronics" 586 "Suzuki Motor Corp" 585 "Industrial Electronic Controls" 584 "CarMedialab GmbH" 583 "Yachtcontrol" 582 "Innovative Software Engineering" 581 "Väderstad - Verken AB" 580 "San Jose Technology, Inc." 579 "KVH Industries, Inc." 578 "advanSea" 577 "Denchi Power Ltd  (formerly ABSL Power Solutions Limited)" 576 "Vectia" 575 "Lytx" 574 "Vishay Precision Group" 573 "Orolia Ltd" 572 "Fasse Valves" 571 "Marinecraft Co., Ltd." 570 "frenzel + berg electronic GmbH & Co. KG" 569 "LORD MicroStrain Sensing Systems" 568 "Makersan Ltd. Co." 567 "Lithiumstart LLC" 566 "Geode Technology, Inc." 565 "Micro-Trak Systems, Inc." 564 "Auto Power Electronic" 563 "LOHR Sistemas Eletronicos LTDA" 562 "Bombardier Transportation GmbH" 561 "b-plus GmbH" 560 "Iowa State University, Agricultural and Biosystems Engineering" 559 "Four Peaks Navigation" 558 "Davis Instruments Corp." 557 "Rockson Automation GmbH" 556 "Doosan Infracore Norway" 555 "Sasaki Corporation" 554 "iris-GmbH infrared & intelligent sensors" 553 "KIB Electronics" 552 "Matsuyama Plow Mfg Co, Ltd" 551 "Wexler CSD Ltd." 550 "SUN-A Corporation" 549 "ROAD Deutschland GmbH" 548 "TM4 Inc." 547 "Thomson Linear LLC" 546 "Maruyama Mfg Co, Inc." 545 "GS Hydraulics" 544 "Au Group Electronics" 543 "BAUER Maschinen GmbH" 542 "Dinamica Generale s.p.a." 541 "Total Fire Systems, Inc." 540 "Dinex A/S" 539 "Mobileview" 538 "Crop Ventures, Inc." 537 "Schrader Electronics Ltd." 536 "SSI Technologies" 535 "MOTORPAL, a.s." 534 "Webasto Thermo & Comfort SE" 533 "Doran Manufacturing, LLC" 532 "Onwa Marine Electronics Co Ltd." 531 "Genge & Thoma AG" 530 "NMEA" 529 "National Instruments Korea" 528 "Hoganas AB, Electric Drive Systems" 527 "GKN Walterscheid GmbH" 526 "LOFA Industries, Inc" 525 "Rust Sales INC" 470 "SI-TEX Marine Electronics" 469 "RA Consulting GmbH" 468 "Tyco Fire Protection Products" 467 "Lely Industries N.V." 466 "Veethree Electronics and Marine LLC" 465 "Ashcroft Inc" 464 "Leach International Corporation" 463 "PROBOTIQ" 462 "IHI Shibaura Machinery Corporation" 461 "HAWE Hydraulik SE" 460 "San Giorgio S.E.I.N." 459 "Alltek Marine Electronics Corp" 458 "Control Solutions, Inc." 457 "RUSELPROM-ElectricDrive Ltd" 456 "General Kinetics" 455 "ADZ NAGANO GmbH" 454 "NGK Spark Plug Co. Ltd" 453 "Cooper Bussmann" 452 "WIKA Alexander Wiegand SE & Co. KG" 451 "Parker Hannifin Corp" 450 "Dycor Technologies Ltd." 449 "Polaris Industries Inc" 448 "Stanadyne Corporation, Electronics Systems" 447 "Great Plains Mfg." 446 "CertTech, L.L.C." 445 "KAT MECHATRONIC, Electronic Product Division" 444 "ITT Power Solutions" 443 "SignalQuest, Inc." 442 "Horsch Maschinen GmbH" 441 "PTG Reifendruckregelsysteme GmbH" 440 "Cummins Power Generation" 439 "Hyundai Heavy Industries" 438 "Comar Systems Ltd" 437 "Digital Yacht Limited" 436 "Kinze Manufacturing" 435 "Zunhammer GmbH" 434 "Stored Energy Systems" 433 "Rowe Electronics" 432 "S&A Systems, Inc." 431 "Tohatsu Corporation" 430 "Auteq Telematica S.A." 429 "Rota Engineering Ltd." 425 "Methode Electronics Inc, MDI" 424 "Odyne LLC" 423 "BSM Wireless, Inc." 422 "True Heading AB" 421 "Vertex Standard Co, Ltd" 420 "Vermeer Corporation, ACS Group" 419 "Fusion Electronics Ltd" 418 "Intellistick Inc" 417 "KZValve" 416 "Kubota Corporation" 415 "Valid Manufacturing Ltd." 414 "Cattron Group International" 413 "Datapross Nijbroek bv" 412 "WebTech Wireless Inc." 411 "Hy-Drive Technologies Ltd." 410 "COBO S.p.A. Divisione 3B6" 409 "Transfluid S.r.L." 408 "Corvus Energy Ltd." 407 "Comtech Mobile Datacom" 406 "Vecima Networks Inc." 405 "Wema System AS" 404 "Com Nav Marine Ltd" 403 "Trackwell ADS, Inc." 402 "Simma Software, Inc." 401 "Torqeedo GmbH" 400 "Livorsi Marine" 399 "ISEKI & Co., Ltd." 398 "Hilite International" 397 "Sanyo-kiki Co Ltd." 396 "Beyond Measure" 395 "GENTEC S.R.L." 394 "Capi 2 Nederland BV" 393 "Harvest Tec, Inc" 392 "Tianyuan Technology Co Ltd." 391 "Electronic Design for Industry, Inc" 390 "Partech Inc." 389 "Benchmark Electronics, Minnesota Division" 388 "Innomatix, LLC" 387 "Orscheln Products, LLC" 386 "JLG Automation BVBA" 385 "Johnson Outdoor Marine Electronics" 384 "Camano Light" 383 "MCL Industries" 382 "National Agriculture and Food Research Organization" 381 "B & G" 380 "Suntech International Ltd." 379 "Yamabiko Corporation" 378 "Glendinning Marine Products" 377 "ifm electronic gmbh" 376 "Quake Global" 375 "Williams Controls Inc." 374 "Northern Lights, Inc." 373 "Electronic Design Inc." 372 "Delphi" 371 "Heinzmann GmbH & Co. KG" 370 "Rolls-Royce Marine AS" 369 "Power Torque Engineering Ltd" 368 "HANSENHOF_electronic" 367 "Fliegl Agrartechnik" 366 "Viewnyx Corp." 365 "Digi-Star, LLC" 364 "OEM Controls Inc." 363 "BEI Duncan" 362 "Poettinger Landtechnik GmbH (formerly Alois Poettinger Maschinenfabrik GmbH)" 361 "InMach" 360 "HJS Emission Technology GmbH & Co KG   (formerly HJS Fahrzeugtechnik GmbH & Co KG)" 359 "Ludwig Bergmann GmbH" 358 "Victron Energy BV" 357 "Hardi International A/S" 356 "Fischer Panda Generators, Inc" 355 "Mastervolt International B.V." 354 "Junkkari OY" 353 "Hegemon Electronics, Inc." 352 "SAME DEUTZ-FAHR GROUP S.p.A." 351 "Thrane & Thrane" 350 "Noris Marine Systems GmbH & Co KG" 349 "Suonentieto" 348 "Amazonen Werke H. Dreyer" 347 "Honeywell" 346 "Control Solutions" 345 "Korean Maritime University" 344 "Parvus Corporation" 343 "Baumer Group" 342 "THOMAS MAGNETE GmbH" 341 "Boning GmbH & Co" 340 "Continental AG" 339 "Competence Center ISOBUS e.V." 338 "GRAF-SYTECO" 337 "Carraro S.p.A." 336 "APE s.r.o." 335 "Evo Electric Ltd" 334 "Takata-Petri AG" 333 "Hadley Products Corporation" 332 "HWH Corporation" 331 "Horton, Inc." 330 "Kidde Aerospace and Defense" 329 "Deif A/S" 328 "Qwerty Electronik AB" 327 "Sonceboz SA" 326 "Akron Brass Company" 325 "ASM Automation Sensorik Messtechnik GmbH" 324 "Snap-on Diagnostics" 323 "Mobileye Vision Technologies Ltd." 322 "MICHENKA s.r.o." 321 "Ultra Electronics, Electrics" 320 "Miedema Landbouwwerktuigenfabriek B.V." 319 "Cadec Global" 318 "SAT Plan" 317 "Navtronics Bvba" 263 "IMMI" 262 "HydraForce, Inc" 261 "Red Dot Corporation" 260 "Reichhardt GmbH Steuerungstechnik" 259 "Jetter AG" 258 "ARAG" 257 "Honda Motor Co., Ltd" 256 "Tyco Electronics AMP" 255 "MEAS France" 254 "GE Sensing" 253 "Mobile Control Systems" 252 "Sensor-Technik Wiedemann GmbH" 251 "German Agricultural Society, Test Center (DLG)" 250 "Kuhn Group" 249 "Schaltbau GmbH" 248 "Cooper Standard Automotive Active Systems Group" 247 "ePULSE" 246 "Class 1, Inc" 245 "Capstan Ag Systems, Inc." 244 "Techno-Matic" 243 "eRide, Inc." 242 "Kokusandenki Co. Ltd" 241 "Schneider Automation SAS" 240 "Vanair Mfg" 239 "May & Scofield Ltd" 238 "ZF Friedrichshafen AG" 237 "Agtron Enterprises Inc" 236 "NORAC Systems International Inc" 235 "SailorMade Marine Telemetry - Tetra Technology Ltd." 234 "Mondial electronic GmbH" 233 "Yacht Monitoring Solutions Inc." 232 "TSD Integrated Controls" 231 "Topcon Positioning Systems, Inc." 230 "Saucon Technologies" 229 "Garmin International Inc." 228 "Unused (formerly ZF Marine Electronics)" 227 "Lykketronic A/S" 226 "Monaco Coach Corporation" 225 "SKF" 224 "EMMI Network, S.L." 223 "Vaueo Retarder Co., Ltd." 222 "Generac Power Systems, Inc." 221 "SiE" 220 "Beede Electrical Instrument Company, Inc" 219 "Cat OEM Solutions" 218 "Gits Manufacturing Company" 217 "RM Michaelides Software & Elektronik GmbH" 216 "Paneltronics Inc." 215 "Aetna Engineering/Fireboy-Xintex" 214 "MC elettronica Srl" 164 "MTU Friedrichshafen GmbH (formerly DaimlerChrysler Off-Highway)" 163 "BRP Inc." 162 "Axiomatic Technologies" 161 "Offshore Systems (UK) Ltd" 160 "Nido" 159 "NTech Industries Inc" 158 "Firestone Industrial Products Company" 157 "ISSPRO Inc." 156 "ITT Industries - Cannon" 155 "Vetronix Corporation" 154 "Westerbeke Corporation" 153 "Woodward, Industrial Controls Division" 152 "elobau GmbH & Co. KG" 151 "Raven Industries, Inc." 150 "Fleetguard" 149 "Holset" 148 "Blue Water Data, Inc." 147 "Nautibus electronic GmbH" 146 "Maxima Technologies" 145 "MurCal Controls" 144 "Mercury Marine" 143 "W. Gmeiner GmbH & Co." 142 "TRW Automotive (Commercial Steering Systems)" 141 "Thales Navigation Ltd." 140 "Lowrance Electronics, Inc." 139 "Caterpillar Trimble Control Technologies (CTCT), LLC" 138 "Georg Fritzmeier GmbH & Co. KG" 137 "Maretron" 136 "Komatsu Ltd" 135 "Airmar Technology Corporation" 134 "Iris Technology Ltd" 133 "Bucher Schoerling GmbH" 132 "Mulag-Fahrzeugwerk" 131 "ITT Industries" 130 "Nido - Universal Machines B.V." 129 "OMNEX Control Systems Inc." 128 "Gerhard Duecker GmbH & Co. KG" 127 "Holland USA" 126 "Driver Tech" 125 "Nevada Automotive Test Center" 124 "Hydac Electronic" 123 "Basler Electric" 122 "FG Wilson (Engineering) Limited" 121 "HED (Hydro Electronic Devices, Inc.)" 120 "RDS Technology Ltd" 119 "IntegriNautics  " 118 "Intron GmbH" 117 "HUSCO International" 116 "BEELINE Technologies" 115 "NACCO Materials Handling Group, Inc." 114 "EControls, Inc." 113 "Stress-Tek, Inc." 112 "MECALAC" 111 "Maschinenfabrik Bernard Krone GmbH" 110 "EPIQ Sensor-Nite" 109 "TeeJet Technologies Denmark (formerly LH Technologies ApS)" 108 "WTK-Elecktronik GmbH" 107 "Grimme Landmaschinen GmbH & Co. KG" 106 "BAE Systems Controls, Inc." 105 "Kiepe Elektrik GmbH & Co. KG" 104 "CLAAS KGaA mbH (formerly CLAAS Selbstfahrende Erntemaschinen GmbH)" 103 "CLAAS E-Systems KGaA mbH & Co. KG (formerly CLAAS Agrosystems GmbH & Co. KG)" 102 "AGCO (formerly AGCO GmbH & Co.)" 101 "Sensoria" 100 "VDO Technik AG" 99 "International Transmissions Ltd (ITL)" 98 "Mueller-Elektronik GmbH & Co" 97 "Ag Leader Technology, Inc." 96 "Mech@tronic IT GmbH" 95 "Pacific Insight Electronics Corp." 94 "CNH Industrial N.V. (formerly CNH Global N.V.)" 93 "Perkins Engines Company Ltd." 92 "Ag-Chem Equipment Co., Inc." 91 "BSG Bodensee Steuergeraete GmbH" 90 "Knorr-Bremse SfN GmbH" 89 "Kverneland Group, Electronics Division" 88 "Satloc Precision GPS" 87 "J.C. Bamford Excavators Ltd (JCB)" 86 "C. E. Niehoff & Company" 85 "Kohler Co" 84 "New Holland UK Limited" 83 "Bendix VORAD Technologies (formerly Eaton VORAD Technologies)" 82 "Bobcat/Ingersoll-Rand (formerly Melroe/Ingersoll-Rand)" 81 "Fire Research Corp." 80 "Twin Disc, Inc." 79 "Daimler Benz AG - Engine Division (PBM)" 78 "Frank W. Murphy Manufacturing, Inc" 77 "Deere Power Systems Group" 76 "unused (formerly Deere & Co, Construction Division)" 75 "Deere & Co, Agricultural Division" 74 "Eaton Axle-Brake Division" 73 "LeTourneau, Inc." 72 "Sisu Corporation" 71 "Vansco Electronics Ltd." 70 "Flex-coil Limited" 69 "Trimble Navigation" 316 "ITT Flow Control" 315 "Icom Incorporated" 314 "CSM GmbH" 313 "Ilmor Engineering, Inc." 312 "Lectronix, Inc." 311 "Patrick Power Products" 310 "TECNORD srl" 309 "Krauss-Maffei Wegmann GmbH & Co. KG" 308 "Cyntrx" 307 "MAS Technologies" 306 "Sleipner Motor AB" 305 "NovAtel Inc" 304 "EmpirBus AB" 303 "CTS Corporation" 302 "Nissin Kogyo Co., LTD" 301 "Parker Hannifin (UK) Ltd FDE group" 300 "Systron Donner Automotive" 299 "Rauch" 298 "Holley Performance" 297 "Zonar Systems Inc" 296 "micro dynamics GmbH" 295 "BEP Marine" 294 "Grayhill Inc." 293 "Spyder Controls Corp." 292 "IKUSI - Angel Iglesias S.A." 291 "Groeneveld Transport Efficiency BV" 290 "Kuebler GmbH" 289 "Watlow" 288 "Mitsubishi FUSO Truck & Bus Corp." 287 "NTech Industries, Inc" 286 "Coelmo srl" 285 "Sea Recovery Corp" 284 "Mobile Tech Chile" 283 "CWF Hamilton & Co Ltd" 282 "Medallion Instrumentation Systems" 281 "Precision Governors LLC" 280 "Leica Geosystems Pty Ltd" 279 "Geometris LP" 278 "Takata Electronics" 277 "LHP Telematics" 276 "Aqua-Hot Heating Systems" 275 "Navico Egersund AS" 274 "LTW Technology Co., LTD" 273 "Active Research Limited" 272 "Gross Mechanical Laboratories, Inc" 271 "Cole Hersee" 270 "Tennant" 269 "Saft America Inc.,  Space & Defense Division" 268 "Accurate Technologies" 267 "Red Lion Controls, Inc" 266 "International Thermal Research Ltd" 265 "MTS Sensor Technologie GmbH" 264 "Autolync" 213 "CNH Belgium N.V." 212 "Sure Power Industries, Inc" 211 "DNA Group" 210 "Iteris, Inc." 209 "Bell Equip. Co. SA (PTY) LTD" 208 "Drew Technologies, Inc" 207 "Otto Engineering" 206 "port GmbH" 205 "SmarTire Systems Inc" 204 "The Morey Corporation" 203 "MILtronik GmbH" 202 "Curtis Instruments, Inc" 201 "Disenos y Tecnologia S.A." 200 "MGM Brakes" 199 "Actia Corp" 198 "Mystic Valley Communications" 197 "Mechron Power Systems" 196 "LEMKEN GmbH & Co KG" 195 "General Engine Products" 194 "TriMark Corporation" 193 "Jeppesen Marine" 192 "Floscan" 191 "XRS Corporation (formerly XATA Corporation)" 190 "Hella KGaA Hueck & Co" 189 "QUALCOMM" 188 "EMP Corp" 187 "Air-Weigh" 186 "Altronic, Inc" 185 "Beede Electrical Instrument Company" 184 "EIA Electronics" 183 "KDS Controls, Inc" 182 "Vehicle Systems Engineering B.V." 181 "Coretronics, Inc." 180 "Smart Power Systems" 179 "TeeJet Technologies Springfield (formerly Midwest Technologies Illinois, LLC)" 178 "Continental Automotive GmbH (formerly Siemens VDO Automotive AG)" 177 "Diagnostic Systems Associates" 176 "Moritz Aerospace" 175 "Veris Technologies, Inc." 174 "AB Volvo Penta" 173 "Ryeso, Inc." 172 "Yanmar Co., Ltd. (formerly Yanmar Marine USA)" 171 "Wachendorff Elektronik GmbH & Co. KG" 170 "Computronics Corporation Ltd." 169 "Marlin Technologies Inc." 168 "Xantrex" 167 "JLG Industries Inc" 166 "John Deere Electronic Solutions (formerly Phoenix International)" 165 "CPAC Systems AB" 68 "Scania" 67 "John Deere Coffeyville Works (formerly Funk Manufacturing Company)" 66 "John Deere Construction Equipment Division" 65 "MAN Nutzfahrzeuge AG" 64 "Unused (formerly SpectraPrecision Laserplane, then SpectraPhysics)" 63 "ZF Industries Inc." 62 "Wabco" 61 "Volvo Truck Corp." 60 "Volvo Trucks North America Inc." 59 "VES Inc." 58 "SPX Corporation, OTC Div" 57 "Danfoss  (formerly Sauer Sundstrand Co, then Sauer-Danfoss Co)" 56 "SAIC" 55 "Ryder System Inc." 54 "Meritor Wabco" 53 "Continental Automotive Systems US, Inc. (formerly Rockwell Land Transportation)" 52 "Meritor Automotive, Inc. (formerly Rockwell Automotive)" 51 "Robert Bosch GmbH" 50 "Robert Bosch Corp" 49 "RE America Inc." 48 "Pollak Alphabet" 47 "Phillips Semiconductor" 46 "Noregon Systems, Inc  (formerly Parasoft Computing Solutions)" 45 "PACCAR" 44 "Nippondenso Co. Ltd." 43 "International Truck and Engine Corporation - Vehicle Electronics (formerly Navistar Intl Trans Corp.)" 42 "International Truck and Engine Corporation - Engine Electronics  (formerly Navistar Intl Trans Co., Engine Electronics)" 41 "Motorola Inc." 40 "Motorola AIEG Inc." 39 "Microfirm Inc." 38 "Micro Processor Systems Inc." 37 "Mack Trucks Inc." 36 "Lucas Ind." 35 "Kenworth Truck Co." 34 "Kelsey Hayes Co." 33 "John Deere" 32 "Jacobs Vehicle Systems" 31 "J Pollak Corp" 30 "Isuzu Motors Ltd" 29 "Hino Motors Ltd." 28 "Grote Ind. Inc." 27 "GMC" 26 "General Motors Corp, Service Technology Grp" 25 "Daimler Trucks North America LLC (formerly Freightliner LLC)" 24 "Ford Motor Co., Vehicle Controls" 23 "Ford Motor Co., Heavy Truck" 22 "Ford Motor Co., Electronic Concepts & Systems" 21 "Echlin Inc., Midland Brake Inc." 20 "Eaton Ltd" 19 "Eaton Corp. Trucking Info Services" 18 "Eaton Corp, Transmission Div." 17 "Eaton Corp, Corp Res & Dev" 16 "Eaton Corp" 15 "DICKEY-john Corporation" 14 "Detroit Diesel Corporation" 13 "Delco Electronics" 12 "Deere & Company, Precision Farming" 11 "Dearborn Group Inc." 10 "Cummins Inc (formerly Cummins Engine Co)" 9 "Chrysler Corp." 8 "Caterpillar Inc." 7 "Case Corp." 6 "Berifors Electronics AB" 5 "AMP Inc." 4 "Ametek-Dixson" 3 "Ametek, US Gauge Division" 2 "Allison Transmission, Inc." 1 "Bendix Commercial Vehicle Systems LLC (formerly Allied Signal Inc.)" 0 "Reserved" ;

SG_MUL_VAL_ 2619670017 HitchPosReq GroupFunctionValue 66-67;
SG_MUL_VAL_ 2619670017 PTOSpeedRequest GroupFunctionValue 64-65;
SG_MUL_VAL_ 2619670017 RequestCounter GroupFunctionValue 0-31, 64-68, 70-70;
SG_MUL_VAL_ 2619670017 AuxValveFlowReq GroupFunctionValue 0-31;
SG_MUL_VAL_ 2619670017 MinimumTIMVersionNr GroupFunctionValue 246-246, 247-247;
SG_MUL_VAL_ 2619670017 ImplementedTIMVersionNr GroupFunctionValue 246-246, 247-247;
SG_MUL_VAL_ 2619670017 TIMMessageType GroupFunctionValue 0-31, 64-68, 70-70;
SG_MUL_VAL_ 2619670018 HitchPosReq GroupFunctionValue 66-67;
SG_MUL_VAL_ 2619670018 PTOSpeedRequest GroupFunctionValue 64-65;
SG_MUL_VAL_ 2619670018 RequestCounter GroupFunctionValue 0-31, 64-68, 70-70;
SG_MUL_VAL_ 2619670018 AuxValveFlowReq GroupFunctionValue 0-31;
SG_MUL_VAL_ 2619670018 MinimumTIMVersionNr GroupFunctionValue 246-246, 247-247;
SG_MUL_VAL_ 2619670018 ImplementedTIMVersionNr GroupFunctionValue 246-246, 247-247;
SG_MUL_VAL_ 2619670018 TIMMessageType GroupFunctionValue 0-31, 64-68, 70-70;
SG_MUL_VAL_ 2619670019 HitchPosReq GroupFunctionValue 66-67;
SG_MUL_VAL_ 2619670019 PTOSpeedRequest GroupFunctionValue 64-65;
SG_MUL_VAL_ 2619670019 RequestCounter GroupFunctionValue 0-31, 64-68, 70-70;
SG_MUL_VAL_ 2619670019 AuxValveFlowReq GroupFunctionValue 0-31;
SG_MUL_VAL_ 2619670019 MinimumTIMVersionNr GroupFunctionValue 246-246, 247-247;
SG_MUL_VAL_ 2619670019 ImplementedTIMVersionNr GroupFunctionValue 246-246, 247-247;
SG_MUL_VAL_ 2619670019 TIMMessageType GroupFunctionValue 0-31, 64-68, 70-70;
SG_MUL_VAL_ 2619604717 HitchPosition GroupFunctionValue 66-67;
SG_MUL_VAL_ 2619604717 HitchExitReasonCode GroupFunctionValue 66-67;
SG_MUL_VAL_ 2619604717 PTOSpeed GroupFunctionValue 64-64, 65-65;
SG_MUL_VAL_ 2619604717 PTOExitReasonCode GroupFunctionValue 64-65;
SG_MUL_VAL_ 2619604717 TIMAuxValveFlow GroupFunctionValue 0-31;
SG_MUL_VAL_ 2619604717 FlowType GroupFunctionValue 0-31;
SG_MUL_VAL_ 2619604717 ReflectedRequestCounter GroupFunctionValue 0-31, 64-68, 70-70;
SG_MUL_VAL_ 2619604717 AuxValveExitReasonCode GroupFunctionValue 0-31;
SG_MUL_VAL_ 2619604717 AutomationStatus GroupFunctionValue 0-31, 64-68, 70-70;
SG_MUL_VAL_ 2619604717 TIMMessageType GroupFunctionValue 0-31, 64-68, 70-70;
SG_MUL_VAL_ 2624650989 ChallengeData MessageCode 4-4, 6-6;
SG_MUL_VAL_ 2624650989 CertType MessageCode 2-2, 3-3;
SG_MUL_VAL_ 2624650989 CertificateFormat MessageCode 2-2, 3-3;
SG_MUL_VAL_ 2624650989 AuthenticationType MessageCode 2-7, 9-9, 249-249;
SG_MUL_VAL_ 2624650989 ErrorCode MessageCode 2-2, 4-4, 6-6, 249-249;
SG_MUL_VAL_ 2624585219 ChallengeData MessageCode 5-5, 7-7;
SG_MUL_VAL_ 2624585219 ErrorCode MessageCode 3-3, 5-5, 7-7, 250-250;
SG_MUL_VAL_ 2624585219 CertType MessageCode 2-2, 3-3;
SG_MUL_VAL_ 2624585219 CertificateFormat MessageCode 2-2, 3-3;
SG_MUL_VAL_ 2624585219 AuthenticationType MessageCode 2-8, 250-250;
SG_MUL_VAL_ 2624585218 ChallengeData MessageCode 5-5, 7-7;
SG_MUL_VAL_ 2624585218 ErrorCode MessageCode 3-3, 5-5, 7-7, 250-250;
SG_MUL_VAL_ 2624585218 CertType MessageCode 2-2, 3-3;
SG_MUL_VAL_ 2624585218 CertificateFormat MessageCode 2-2, 3-3;
SG_MUL_VAL_ 2624585218 AuthenticationType MessageCode 2-8, 250-250;
SG_MUL_VAL_ 2624585217 ChallengeData MessageCode 5-5, 7-7;
SG_MUL_VAL_ 2624585217 ErrorCode MessageCode 3-3, 5-5, 7-7, 250-250;
SG_MUL_VAL_ 2624585217 CertType MessageCode 2-2, 3-3;
SG_MUL_VAL_ 2624585217 CertificateFormat MessageCode 2-2, 3-3;
SG_MUL_VAL_ 2624585217 AuthenticationType MessageCode 2-8, 250-250;
